VERSION ""

NS_ :

BS_:

BU_: BCM BSM DIAG_TEST ECM EPS IPC MTA ORC PAM

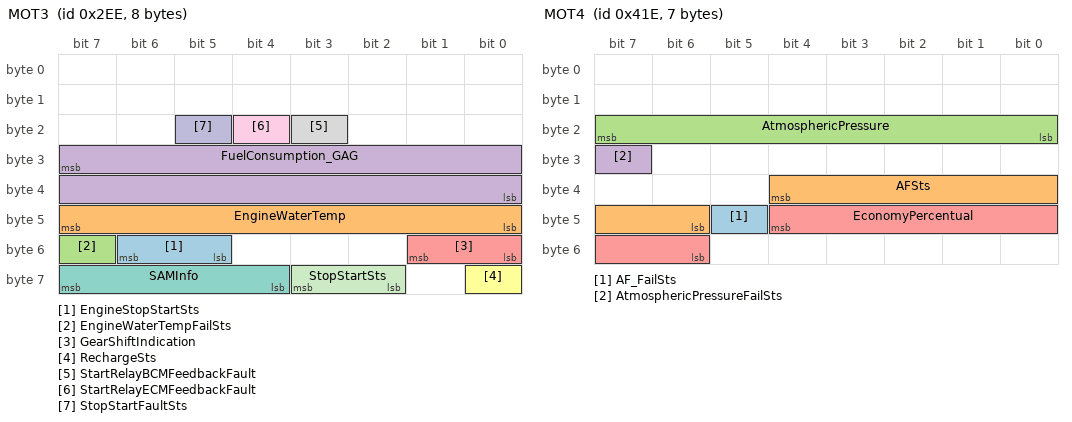
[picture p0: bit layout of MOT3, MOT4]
BO_ 750 MOT3: 8 ECM
 SG_ EngineStopStartSts : 54|2@0+ (1,0) [0|3] "-"  BCM,BSM,EPS,MTA
 SG_ EngineWaterTemp : 47|8@0+ (1,-40) [-40|215] "°C"  BCM,IPC,MTA
 SG_ EngineWaterTempFailSts : 55|1@0+ (1,0) [0|1] "-"  BCM,IPC
 SG_ FuelConsumption_GAG : 31|16@0+ (0.0022,0) [0|144.1748] "litres/hour"  BCM,IPC
 SG_ GearShiftIndication : 49|2@0+ (1,0) [0|3] "-"  BCM,IPC
 SG_ RechargeSts : 56|1@0+ (1,0) [0|1] "-"  BCM,IPC
 SG_ SAMInfo : 63|4@0+ (1,0) [0|0] "-"  BCM
 SG_ StartRelayBCMFeedbackFault : 19|1@0+ (1,0) [0|1] "-"  BCM
 SG_ StartRelayECMFeedbackFault : 20|1@0+ (1,0) [0|1] "-"  BCM
 SG_ StopStartFaultSts : 21|1@0+ (1,0) [0|1] "-"  BCM
 SG_ StopStartSts : 59|2@0+ (1,0) [0|3] "-"  BCM,BSM,EPS,IPC,MTA

BO_ 1054 MOT4: 7 ECM
 SG_ AF_FailSts : 45|1@0+ (1,0) [0|1] ""  BCM,IPC
 SG_ AFSts : 36|7@0+ (0.1,8) [8|20.7] ""  BCM,IPC
 SG_ AtmosphericPressure : 23|8@0+ (3.6,300) [300|1214.4] "mbar"  MTA
 SG_ AtmosphericPressureFailSts : 31|1@0+ (1,0) [0|1] "-"  MTA
 SG_ EconomyPercentual : 44|7@0+ (1,0) [0|127] "%"  IPC

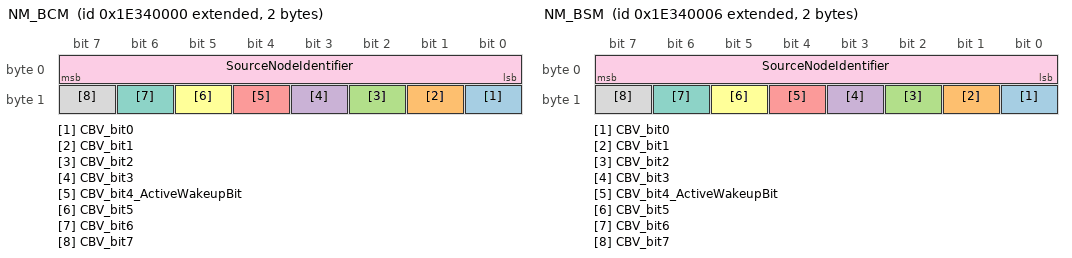
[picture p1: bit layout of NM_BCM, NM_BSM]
BO_ 2654208000 NM_BCM: 2 BCM
 SG_ CBV_bit0 : 8|1@0+ (1,0) [0|0] ""  BSM,ECM,EPS,IPC,MTA
 SG_ CBV_bit1 : 9|1@0+ (1,0) [0|0] ""  BSM,ECM,EPS,IPC,MTA
 SG_ CBV_bit2 : 10|1@0+ (1,0) [0|0] ""  BSM,ECM,EPS,IPC,MTA
 SG_ CBV_bit3 : 11|1@0+ (1,0) [0|0] ""  BSM,ECM,EPS,IPC,MTA
 SG_ CBV_bit4_ActiveWakeupBit : 12|1@0+ (1,0) [0|0] ""  BSM,ECM,EPS,IPC,MTA
 SG_ CBV_bit5 : 13|1@0+ (1,0) [0|0] ""  BSM,ECM,EPS,IPC,MTA
 SG_ CBV_bit6 : 14|1@0+ (1,0) [0|0] ""  BSM,ECM,EPS,IPC,MTA
 SG_ CBV_bit7 : 15|1@0+ (1,0) [0|0] ""  BSM,ECM,EPS,IPC,MTA
 SG_ SourceNodeIdentifier : 7|8@0+ (1,0) [0|1] "-"  BSM,ECM,EPS,IPC,MTA

BO_ 2654208006 NM_BSM: 2 BSM
 SG_ CBV_bit0 : 8|1@0+ (1,0) [0|0] ""  BCM,ECM,EPS,IPC,MTA
 SG_ CBV_bit1 : 9|1@0+ (1,0) [0|0] ""  BCM,ECM,EPS,IPC,MTA
 SG_ CBV_bit2 : 10|1@0+ (1,0) [0|0] ""  BCM,ECM,EPS,IPC,MTA
 SG_ CBV_bit3 : 11|1@0+ (1,0) [0|0] ""  BCM,ECM,EPS,IPC,MTA
 SG_ CBV_bit4_ActiveWakeupBit : 12|1@0+ (1,0) [0|0] ""  BCM,ECM,EPS,IPC,MTA
 SG_ CBV_bit5 : 13|1@0+ (1,0) [0|0] ""  BCM,ECM,EPS,IPC,MTA
 SG_ CBV_bit6 : 14|1@0+ (1,0) [0|0] ""  BCM,ECM,EPS,IPC,MTA
 SG_ CBV_bit7 : 15|1@0+ (1,0) [0|0] ""  BCM,ECM,EPS,IPC,MTA
 SG_ SourceNodeIdentifier : 7|8@0+ (1,0) [0|1] "-"  BCM,ECM,EPS,IPC,MTA

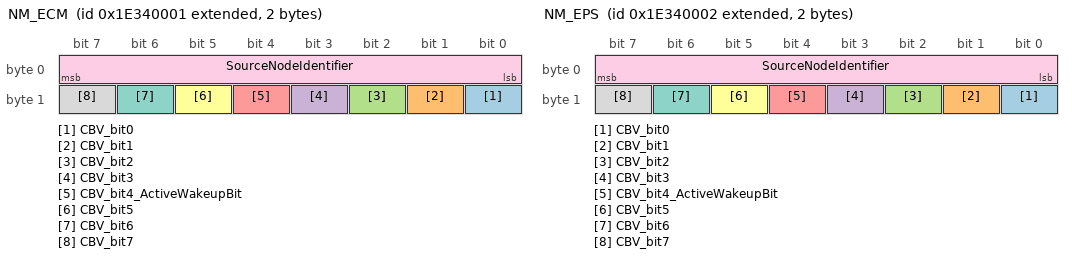
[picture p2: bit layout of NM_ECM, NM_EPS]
BO_ 2654208001 NM_ECM: 2 ECM
 SG_ CBV_bit0 : 8|1@0+ (1,0) [0|0] ""  BCM,BSM,EPS,IPC,MTA
 SG_ CBV_bit1 : 9|1@0+ (1,0) [0|0] ""  BCM,BSM,EPS,IPC,MTA
 SG_ CBV_bit2 : 10|1@0+ (1,0) [0|0] ""  BCM,BSM,EPS,IPC,MTA
 SG_ CBV_bit3 : 11|1@0+ (1,0) [0|0] ""  BCM,BSM,EPS,IPC,MTA
 SG_ CBV_bit4_ActiveWakeupBit : 12|1@0+ (1,0) [0|0] ""  BCM,BSM,EPS,IPC,MTA
 SG_ CBV_bit5 : 13|1@0+ (1,0) [0|0] ""  BCM,BSM,EPS,IPC,MTA
 SG_ CBV_bit6 : 14|1@0+ (1,0) [0|0] ""  BCM,BSM,EPS,IPC,MTA
 SG_ CBV_bit7 : 15|1@0+ (1,0) [0|0] ""  BCM,BSM,EPS,IPC,MTA
 SG_ SourceNodeIdentifier : 7|8@0+ (1,0) [0|1] "-"  BCM,BSM,EPS,IPC,MTA

BO_ 2654208002 NM_EPS: 2 EPS
 SG_ CBV_bit0 : 8|1@0+ (1,0) [0|0] ""  BCM,BSM,ECM,IPC,MTA
 SG_ CBV_bit1 : 9|1@0+ (1,0) [0|0] ""  BCM,BSM,ECM,IPC,MTA
 SG_ CBV_bit2 : 10|1@0+ (1,0) [0|0] ""  BCM,BSM,ECM,IPC,MTA
 SG_ CBV_bit3 : 11|1@0+ (1,0) [0|0] ""  BCM,BSM,ECM,IPC,MTA
 SG_ CBV_bit4_ActiveWakeupBit : 12|1@0+ (1,0) [0|0] ""  BCM,BSM,ECM,IPC,MTA
 SG_ CBV_bit5 : 13|1@0+ (1,0) [0|0] ""  BCM,BSM,ECM,IPC,MTA
 SG_ CBV_bit6 : 14|1@0+ (1,0) [0|0] ""  BCM,BSM,ECM,IPC,MTA
 SG_ CBV_bit7 : 15|1@0+ (1,0) [0|0] ""  BCM,BSM,ECM,IPC,MTA
 SG_ SourceNodeIdentifier : 7|8@0+ (1,0) [0|1] "-"  BCM,BSM,ECM,IPC,MTA

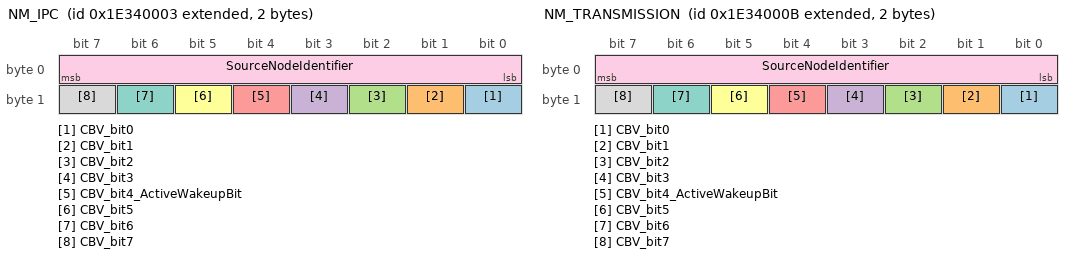
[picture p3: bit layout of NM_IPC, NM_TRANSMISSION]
BO_ 2654208003 NM_IPC: 2 IPC
 SG_ CBV_bit0 : 8|1@0+ (1,0) [0|0] ""  BCM,BSM,ECM,EPS,MTA
 SG_ CBV_bit1 : 9|1@0+ (1,0) [0|0] ""  BCM,BSM,ECM,EPS,MTA
 SG_ CBV_bit2 : 10|1@0+ (1,0) [0|0] ""  BCM,BSM,ECM,EPS,MTA
 SG_ CBV_bit3 : 11|1@0+ (1,0) [0|0] ""  BCM,BSM,ECM,EPS,MTA
 SG_ CBV_bit4_ActiveWakeupBit : 12|1@0+ (1,0) [0|0] ""  BCM,BSM,ECM,EPS,MTA
 SG_ CBV_bit5 : 13|1@0+ (1,0) [0|0] ""  BCM,BSM,ECM,EPS,MTA
 SG_ CBV_bit6 : 14|1@0+ (1,0) [0|0] ""  BCM,BSM,ECM,EPS,MTA
 SG_ CBV_bit7 : 15|1@0+ (1,0) [0|0] ""  BCM,BSM,ECM,EPS,MTA
 SG_ SourceNodeIdentifier : 7|8@0+ (1,0) [0|1] "-"  BCM,BSM,ECM,EPS,MTA

BO_ 2654208011 NM_TRANSMISSION: 2 MTA
 SG_ CBV_bit0 : 8|1@0+ (1,0) [0|0] ""  BCM,BSM,ECM,EPS,IPC
 SG_ CBV_bit1 : 9|1@0+ (1,0) [0|0] ""  BCM,BSM,ECM,EPS,IPC
 SG_ CBV_bit2 : 10|1@0+ (1,0) [0|0] ""  BCM,BSM,ECM,EPS,IPC
 SG_ CBV_bit3 : 11|1@0+ (1,0) [0|0] ""  BCM,BSM,ECM,EPS,IPC
 SG_ CBV_bit4_ActiveWakeupBit : 12|1@0+ (1,0) [0|0] ""  BCM,BSM,ECM,EPS,IPC
 SG_ CBV_bit5 : 13|1@0+ (1,0) [0|0] ""  BCM,BSM,ECM,EPS,IPC
 SG_ CBV_bit6 : 14|1@0+ (1,0) [0|0] ""  BCM,BSM,ECM,EPS,IPC
 SG_ CBV_bit7 : 15|1@0+ (1,0) [0|0] ""  BCM,BSM,ECM,EPS,IPC
 SG_ SourceNodeIdentifier : 7|8@0+ (1,0) [0|1] "-"  BCM,BSM,ECM,EPS,IPC

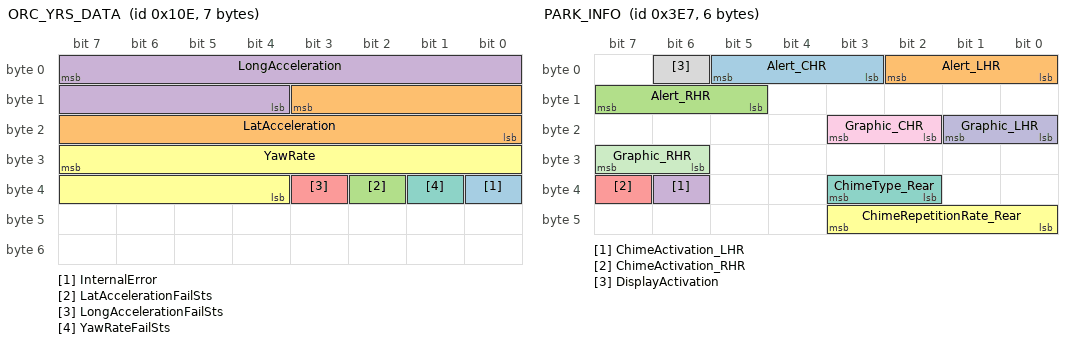
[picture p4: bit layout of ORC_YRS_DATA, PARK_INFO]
BO_ 270 ORC_YRS_DATA: 7 ORC
 SG_ InternalError : 32|1@0+ (1,0) [0|1] "-"  BSM
 SG_ LatAcceleration : 11|12@0+ (0.02,-40.96) [-40.96|40.92] "m/s^2"  BSM
 SG_ LatAccelerationFailSts : 34|1@0+ (1,0) [0|3] "-"  BSM
 SG_ LongAcceleration : 7|12@0+ (0.02,-40.96) [-40.96|40.92] "m/s^2"  BSM
 SG_ LongAccelerationFailSts : 35|1@0+ (1,0) [0|3] "-"  BSM
 SG_ YawRate : 31|12@0+ (0.08,-163.84) [-163.84|163.68] "deg/s"  BSM
 SG_ YawRateFailSts : 33|1@0+ (1,0) [0|3] "-"  BSM

BO_ 999 PARK_INFO: 6 PAM
 SG_ Alert_CHR : 5|3@0+ (1,0) [0|7] "-"  IPC
 SG_ Alert_LHR : 2|3@0+ (1,0) [0|7] "-"  IPC
 SG_ Alert_RHR : 15|3@0+ (1,0) [0|7] "-"  IPC
 SG_ ChimeActivation_LHR : 38|1@0+ (1,0) [0|1] "-"  IPC
 SG_ ChimeActivation_RHR : 39|1@0+ (1,0) [0|1] "-"  IPC
 SG_ ChimeRepetitionRate_Rear : 43|4@0+ (1,0) [0|15] "Hz"  IPC
 SG_ ChimeType_Rear : 35|2@0+ (1,0) [0|1] "-"  IPC
 SG_ DisplayActivation : 6|1@0+ (1,0) [0|1] "-"  IPC
 SG_ Graphic_CHR : 19|2@0+ (1,0) [0|3] "-"  IPC
 SG_ Graphic_LHR : 17|2@0+ (1,0) [0|3] "-"  IPC
 SG_ Graphic_RHR : 31|2@0+ (1,0) [0|3] "-"  IPC

BO_ 2654339072 PDC_INFO_BCM: 3 BCM
 SG_ CurrentFailSts_BCM : 6|1@0+ (1,0) [0|1] "" Vector__XXX
 SG_ DES_BCM : 4|1@0+ (1,0) [0|1] "" Vector__XXX
 SG_ EOL_BCM : 7|1@0+ (1,0) [0|1] "-" Vector__XXX
 SG_ GenericFailSts_BCM : 5|1@0+ (1,0) [0|1] "" Vector__XXX
 SG_ Reserved_for_PDC_BCM : 3|4@0+ (1,0) [0|0] "" Vector__XXX
 SG_ StayActiveSource_BCM_0 : 15|1@0+ (1,0) [0|1] "" Vector__XXX
 SG_ StayActiveSource_BCM_1 : 14|1@0+ (1,0) [0|1] "" Vector__XXX
 SG_ StayActiveSource_BCM_10 : 21|1@0+ (1,0) [0|1] "" Vector__XXX
 SG_ StayActiveSource_BCM_11 : 20|1@0+ (1,0) [0|1] "" Vector__XXX
 SG_ StayActiveSource_BCM_12 : 19|1@0+ (1,0) [0|1] "" Vector__XXX
 SG_ StayActiveSource_BCM_13 : 18|1@0+ (1,0) [0|1] "" Vector__XXX
 SG_ StayActiveSource_BCM_14 : 17|1@0+ (1,0) [0|1] "" Vector__XXX
 SG_ StayActiveSource_BCM_15 : 16|1@0+ (1,0) [0|1] "" Vector__XXX
 SG_ StayActiveSource_BCM_2 : 13|1@0+ (1,0) [0|1] "" Vector__XXX
 SG_ StayActiveSource_BCM_3 : 12|1@0+ (1,0) [0|1] "" Vector__XXX
 SG_ StayActiveSource_BCM_4 : 11|1@0+ (1,0) [0|1] "" Vector__XXX
 SG_ StayActiveSource_BCM_5 : 10|1@0+ (1,0) [0|1] "" Vector__XXX
 SG_ StayActiveSource_BCM_6 : 9|1@0+ (1,0) [0|1] "" Vector__XXX
 SG_ StayActiveSource_BCM_7 : 8|1@0+ (1,0) [0|1] "" Vector__XXX
 SG_ StayActiveSource_BCM_8 : 23|1@0+ (1,0) [0|1] "" Vector__XXX
 SG_ StayActiveSource_BCM_9 : 22|1@0+ (1,0) [0|1] "" Vector__XXX

BO_ 2654339078 PDC_INFO_BSM: 3 BSM
 SG_ CurrentFailSts_BSM : 6|1@0+ (1,0) [0|1] ""  BCM
 SG_ DES_BSM : 4|1@0+ (1,0) [0|1] "" Vector__XXX
 SG_ EOL_BSM : 7|1@0+ (1,0) [0|1] "-"  BCM
 SG_ GenericFailSts_BSM : 5|1@0+ (1,0) [0|1] ""  BCM
 SG_ Reserved_for_PDC_BSM : 3|4@0+ (1,0) [0|0] "" Vector__XXX
 SG_ StayActiveSource_BSM_0 : 15|1@0+ (1,0) [0|1] "" Vector__XXX
 SG_ StayActiveSource_BSM_1 : 14|1@0+ (1,0) [0|1] "" Vector__XXX
 SG_ StayActiveSource_BSM_10 : 21|1@0+ (1,0) [0|1] "" Vector__XXX
 SG_ StayActiveSource_BSM_11 : 20|1@0+ (1,0) [0|1] "" Vector__XXX
 SG_ StayActiveSource_BSM_12 : 19|1@0+ (1,0) [0|1] "" Vector__XXX
 SG_ StayActiveSource_BSM_13 : 18|1@0+ (1,0) [0|1] "" Vector__XXX
 SG_ StayActiveSource_BSM_14 : 17|1@0+ (1,0) [0|1] "" Vector__XXX
 SG_ StayActiveSource_BSM_15 : 16|1@0+ (1,0) [0|1] "" Vector__XXX
 SG_ StayActiveSource_BSM_2 : 13|1@0+ (1,0) [0|1] "" Vector__XXX
 SG_ StayActiveSource_BSM_3 : 12|1@0+ (1,0) [0|1] "" Vector__XXX
 SG_ StayActiveSource_BSM_4 : 11|1@0+ (1,0) [0|1] "" Vector__XXX
 SG_ StayActiveSource_BSM_5 : 10|1@0+ (1,0) [0|1] "" Vector__XXX
 SG_ StayActiveSource_BSM_6 : 9|1@0+ (1,0) [0|1] "" Vector__XXX
 SG_ StayActiveSource_BSM_7 : 8|1@0+ (1,0) [0|1] "" Vector__XXX
 SG_ StayActiveSource_BSM_8 : 23|1@0+ (1,0) [0|1] "" Vector__XXX
 SG_ StayActiveSource_BSM_9 : 22|1@0+ (1,0) [0|1] "" Vector__XXX

BO_ 2654339073 PDC_INFO_ECM: 3 ECM
 SG_ CurrentFailSts_ECM : 6|1@0+ (1,0) [0|1] ""  BCM
 SG_ DES_ECM : 4|1@0+ (1,0) [0|1] "" Vector__XXX
 SG_ EOL_ECM : 7|1@0+ (1,0) [0|1] "-"  BCM
 SG_ GenericFailSts_ECM : 5|1@0+ (1,0) [0|1] ""  BCM
 SG_ Reserved_for_PDC_ECM : 3|4@0+ (1,0) [0|0] "" Vector__XXX
 SG_ StayActiveSource_ECM_0 : 15|1@0+ (1,0) [0|1] "" Vector__XXX
 SG_ StayActiveSource_ECM_1 : 14|1@0+ (1,0) [0|1] "" Vector__XXX
 SG_ StayActiveSource_ECM_10 : 21|1@0+ (1,0) [0|1] "" Vector__XXX
 SG_ StayActiveSource_ECM_11 : 20|1@0+ (1,0) [0|1] "" Vector__XXX
 SG_ StayActiveSource_ECM_12 : 19|1@0+ (1,0) [0|1] "" Vector__XXX
 SG_ StayActiveSource_ECM_13 : 18|1@0+ (1,0) [0|1] "" Vector__XXX
 SG_ StayActiveSource_ECM_14 : 17|1@0+ (1,0) [0|1] "" Vector__XXX
 SG_ StayActiveSource_ECM_15 : 16|1@0+ (1,0) [0|1] "" Vector__XXX
 SG_ StayActiveSource_ECM_2 : 13|1@0+ (1,0) [0|1] "" Vector__XXX
 SG_ StayActiveSource_ECM_3 : 12|1@0+ (1,0) [0|1] "" Vector__XXX
 SG_ StayActiveSource_ECM_4 : 11|1@0+ (1,0) [0|1] "" Vector__XXX
 SG_ StayActiveSource_ECM_5 : 10|1@0+ (1,0) [0|1] "" Vector__XXX
 SG_ StayActiveSource_ECM_6 : 9|1@0+ (1,0) [0|1] "" Vector__XXX
 SG_ StayActiveSource_ECM_7 : 8|1@0+ (1,0) [0|1] "" Vector__XXX
 SG_ StayActiveSource_ECM_8 : 23|1@0+ (1,0) [0|1] "" Vector__XXX
 SG_ StayActiveSource_ECM_9 : 22|1@0+ (1,0) [0|1] "" Vector__XXX

BO_ 2654339074 PDC_INFO_EPS: 3 EPS
 SG_ CurrentFailSts_EPS : 6|1@0+ (1,0) [0|1] ""  BCM
 SG_ DES_EPS : 4|1@0+ (1,0) [0|1] "" Vector__XXX
 SG_ EOL_EPS : 7|1@0+ (1,0) [0|1] "-"  BCM
 SG_ GenericFailSts_EPS : 5|1@0+ (1,0) [0|1] ""  BCM
 SG_ Reserved_for_PDC_EPS : 3|4@0+ (1,0) [0|0] "" Vector__XXX
 SG_ StayActiveSource_EPS_0 : 15|1@0+ (1,0) [0|1] "" Vector__XXX
 SG_ StayActiveSource_EPS_1 : 14|1@0+ (1,0) [0|1] "" Vector__XXX
 SG_ StayActiveSource_EPS_10 : 21|1@0+ (1,0) [0|1] "" Vector__XXX
 SG_ StayActiveSource_EPS_11 : 20|1@0+ (1,0) [0|1] "" Vector__XXX
 SG_ StayActiveSource_EPS_12 : 19|1@0+ (1,0) [0|1] "" Vector__XXX
 SG_ StayActiveSource_EPS_13 : 18|1@0+ (1,0) [0|1] "" Vector__XXX
 SG_ StayActiveSource_EPS_14 : 17|1@0+ (1,0) [0|1] "" Vector__XXX
 SG_ StayActiveSource_EPS_15 : 16|1@0+ (1,0) [0|1] "" Vector__XXX
 SG_ StayActiveSource_EPS_2 : 13|1@0+ (1,0) [0|1] "" Vector__XXX
 SG_ StayActiveSource_EPS_3 : 12|1@0+ (1,0) [0|1] "" Vector__XXX
 SG_ StayActiveSource_EPS_4 : 11|1@0+ (1,0) [0|1] "" Vector__XXX
 SG_ StayActiveSource_EPS_5 : 10|1@0+ (1,0) [0|1] "" Vector__XXX
 SG_ StayActiveSource_EPS_6 : 9|1@0+ (1,0) [0|1] "" Vector__XXX
 SG_ StayActiveSource_EPS_7 : 8|1@0+ (1,0) [0|1] "" Vector__XXX
 SG_ StayActiveSource_EPS_8 : 23|1@0+ (1,0) [0|1] "" Vector__XXX
 SG_ StayActiveSource_EPS_9 : 22|1@0+ (1,0) [0|1] "" Vector__XXX

BO_ 2654339075 PDC_INFO_IPC: 3 IPC
 SG_ CurrentFailSts_IPC : 6|1@0+ (1,0) [0|1] ""  BCM
 SG_ DES_IPC : 4|1@0+ (1,0) [0|1] "" Vector__XXX
 SG_ EOL_IPC : 7|1@0+ (1,0) [0|1] "-"  BCM
 SG_ GenericFailSts_IPC : 5|1@0+ (1,0) [0|1] ""  BCM
 SG_ Reserved_for_PDC_IPC : 3|4@0+ (1,0) [0|0] "" Vector__XXX
 SG_ StayActiveSource_IPC_0 : 15|1@0+ (1,0) [0|1] "" Vector__XXX
 SG_ StayActiveSource_IPC_1 : 14|1@0+ (1,0) [0|1] "" Vector__XXX
 SG_ StayActiveSource_IPC_10 : 21|1@0+ (1,0) [0|1] "" Vector__XXX
 SG_ StayActiveSource_IPC_11 : 20|1@0+ (1,0) [0|1] "" Vector__XXX
 SG_ StayActiveSource_IPC_12 : 19|1@0+ (1,0) [0|1] "" Vector__XXX
 SG_ StayActiveSource_IPC_13 : 18|1@0+ (1,0) [0|1] "" Vector__XXX
 SG_ StayActiveSource_IPC_14 : 17|1@0+ (1,0) [0|1] "" Vector__XXX
 SG_ StayActiveSource_IPC_15 : 16|1@0+ (1,0) [0|1] "" Vector__XXX
 SG_ StayActiveSource_IPC_2 : 13|1@0+ (1,0) [0|1] "" Vector__XXX
 SG_ StayActiveSource_IPC_3 : 12|1@0+ (1,0) [0|1] "" Vector__XXX
 SG_ StayActiveSource_IPC_4 : 11|1@0+ (1,0) [0|1] "" Vector__XXX
 SG_ StayActiveSource_IPC_5 : 10|1@0+ (1,0) [0|1] "" Vector__XXX
 SG_ StayActiveSource_IPC_6 : 9|1@0+ (1,0) [0|1] "" Vector__XXX
 SG_ StayActiveSource_IPC_7 : 8|1@0+ (1,0) [0|1] "" Vector__XXX
 SG_ StayActiveSource_IPC_8 : 23|1@0+ (1,0) [0|1] "" Vector__XXX
 SG_ StayActiveSource_IPC_9 : 22|1@0+ (1,0) [0|1] "" Vector__XXX

CM_ SG_ 750 EngineStopStartSts "It is set to Engine Stop when the Engine is turned off by the Stop&Start management";
CM_ SG_ 750 EngineWaterTemp "It is the engine water temperature, measured through the related sensor.";
CM_ SG_ 750 EngineWaterTempFailSts "It is the Fail Status bit of EngineWaterTemp signal; the signal is set to Fail Present when the engine temperature sensor is faulty.";
CM_ SG_ 750 FuelConsumption_GAG "It represents istantaneous consumption information sent on network";
CM_ SG_ 750 GearShiftIndication "It gives indication of gear shifting";
CM_ SG_ 750 RechargeSts "It is the ECM logical Output used to indicate if alternator status is in Recharge or Not Recharge status.";
CM_ SG_ 750 SAMInfo "This signal indicates the logic status of the SAM strategy.";
CM_ SG_ 750 StartRelayBCMFeedbackFault "Diagnosis signal of the BCM cranking relay sent by ECM";
CM_ SG_ 750 StartRelayECMFeedbackFault "Diagnosis signal of the ECM cranking relay, sent by ECM";
CM_ SG_ 750 StopStartFaultSts "Indicates a possible fault occurred on the sensor acquired by ECM";
CM_ SG_ 750 StopStartSts "Sent by ECM to BCM, highlight the status of the Stop&Start function.";
CM_ SG_ 1054 AtmosphericPressure "It indicates atmospheric pressure read from the atmospheric pressure sensor.";
CM_ SG_ 1054 AtmosphericPressureFailSts "This signal indicates if the atmospheric pressure sensor is in fail.";
CM_ SG_ 270 InternalError "This signal indicates if an internal error has been processed";
CM_ SG_ 270 LatAcceleration "This signal indicates the Lateral Acceleration Value";
CM_ SG_ 270 LatAccelerationFailSts "This signal indicates the status of Lateral Acceleration Signal";
CM_ SG_ 270 LongAcceleration "This signal indicates the Longitudinal Acceleration Value";
CM_ SG_ 270 LongAccelerationFailSts "This signal indicates the status of Longitudinal acceleration signal";
CM_ SG_ 270 YawRate "This signal indicates the Yaw Rate Value";
CM_ SG_ 270 YawRateFailSts "This signal indicates the Status of Yaw Rate Signal";
CM_ SG_ 999 Alert_CHR "This signal indicates which arc shall be displayed in the central hand, rear position of the car graphics.";
CM_ SG_ 999 Alert_LHR "This signal indicates which arc shall be displayed in the left hand, rear position of the car graphics.";
CM_ SG_ 999 Alert_RHR "This signal indicates which arc shall be displayed in the right hand, rear position of the car graphics.";
CM_ SG_ 999 ChimeActivation_LHR "This signal indicates the chime activation request for the left hand, rear audio speaker, or rear hardwired buzzer.";
CM_ SG_ 999 ChimeActivation_RHR "This signal indicates the chime activation request for the right hand, rear audio speaker, or rear hardwired buzzer.";
CM_ SG_ 999 ChimeRepetitionRate_Rear "This signal indicates the repetition rate for the rear audio speakers.";
CM_ SG_ 999 ChimeType_Rear "This signal indicates the Chime Type for the rear audio speakers.";
CM_ SG_ 999 DisplayActivation "This signal indicates the request to display the car graphics layout on the IPC/EVIC screen.";
CM_ SG_ 999 Graphic_CHR "This signal indicates the flash rate of the arc displayed in the central hand, rear position of the car graphics.";
CM_ SG_ 999 Graphic_LHR "This signal indicates the flash rate of the arc displayed in the left hand, rear position of the car graphics.";
CM_ SG_ 999 Graphic_RHR "This signal indicates the flash rate of the arc displayed in the right hand, rear position of the car graphics.";
BA_DEF_ SG_  "GenSigStartValue" INT 0 2147483647;
BA_DEF_ SG_  "GenSigInactiveValue" INT 0 2147483647;
BA_DEF_ SG_  "GenSigSendType" ENUM  "NotUsed","OnWrite","OnWriteWithRepetition","OnChange","OnChangeWithRepetition","IfActive","IfActiveWithRepetition","NoSigSendType";
BA_DEF_ SG_  "GenSigTimeoutTime_BCM" INT 0 65535;
BA_DEF_ SG_  "GenSigTimeoutTime_BSM" INT 0 65535;
BA_DEF_ SG_  "GenSigTimeoutTime_DIAG_TEST" INT 0 65535;
BA_DEF_ SG_  "GenSigTimeoutTime_ECM" INT 0 65535;
BA_DEF_ SG_  "GenSigTimeoutTime_EPS" INT 0 65535;
BA_DEF_ SG_  "GenSigTimeoutTime_IPC" INT 0 65535;
BA_DEF_ SG_  "GenSigTimeoutTime_MTA" INT 0 65535;
BA_DEF_ SG_  "GenSigTimeoutTime_ORC" INT 0 65535;
BA_DEF_ SG_  "GenSigTimeoutTime_PAM" INT 0 65535;
BA_DEF_ BO_  "DiagRequest" ENUM  "No","Yes";
BA_DEF_ BO_  "Type" ENUM  "P","C","PE","COC","PE_Cntrl","E","E_Cntrl","OC","S","BAF","DC","EM","MM","-";
BA_DEF_ BO_  "DiagResponse" ENUM  "No","Yes";
BA_DEF_ BO_  "NmMessage" ENUM  "No","Yes";
BA_DEF_ BO_  "GenMsgSendType" ENUM  "Cyclic","NotUsed","NotUsed","NotUsed","NotUsed","NotUsed","NotUsed","NotUsed","NoMsgSendType";
BA_DEF_ BO_  "GenMsgNrOfRepetition" INT 0 255;
BA_DEF_ BO_  "GenMsgILSupport" ENUM  "No","Yes";
BA_DEF_ BO_  "GenMsgStartDelayTime" INT 0 65535;
BA_DEF_ BO_  "GenMsgCycleTimeFast" INT 0 65535;
BA_DEF_ BO_  "GenMsgCycleTime" INT 0 65535;
BA_DEF_ BO_  "GenMsgDelayTime" INT 0 65535;
BA_DEF_ BO_  "NmAsrMessage" ENUM  "No","Yes";
BA_DEF_ BO_  "DiagState" ENUM  "No","Yes";
BA_DEF_ BO_  "DiagConnection" HEX 0 65535;
BA_DEF_DEF_  "GenSigStartValue" 0;
BA_DEF_DEF_  "GenSigInactiveValue" 0;
BA_DEF_DEF_  "GenSigSendType" "NoSigSendType";
BA_DEF_DEF_  "GenSigTimeoutTime_BCM" 2500;
BA_DEF_DEF_  "GenSigTimeoutTime_BSM" 2500;
BA_DEF_DEF_  "GenSigTimeoutTime_DIAG_TEST" 2500;
BA_DEF_DEF_  "GenSigTimeoutTime_ECM" 2500;
BA_DEF_DEF_  "GenSigTimeoutTime_EPS" 2500;
BA_DEF_DEF_  "GenSigTimeoutTime_IPC" 2500;
BA_DEF_DEF_  "GenSigTimeoutTime_MTA" 2500;
BA_DEF_DEF_  "GenSigTimeoutTime_ORC" 2500;
BA_DEF_DEF_  "GenSigTimeoutTime_PAM" 2500;
BA_DEF_DEF_  "DiagRequest" "No";
BA_DEF_DEF_  "Type" "-";
BA_DEF_DEF_  "DiagResponse" "No";
BA_DEF_DEF_  "NmMessage" "No";
BA_DEF_DEF_  "GenMsgSendType" "NoMsgSendType";
BA_DEF_DEF_  "GenMsgNrOfRepetition" 0;
BA_DEF_DEF_  "GenMsgILSupport" "No";
BA_DEF_DEF_  "GenMsgStartDelayTime" 0;
BA_DEF_DEF_  "GenMsgCycleTimeFast" 0;
BA_DEF_DEF_  "GenMsgCycleTime" 0;
BA_DEF_DEF_  "GenMsgDelayTime" 0;
BA_DEF_DEF_  "NmAsrMessage" "No";
BA_DEF_DEF_  "DiagState" "No";
BA_DEF_DEF_  "DiagConnection" 0;
BA_ "Type" BO_ 750 1;
BA_ "GenMsgSendType" BO_ 750 0;
BA_ "GenMsgILSupport" BO_ 750 1;
BA_ "GenMsgStartDelayTime" BO_ 750 30;
BA_ "GenMsgCycleTime" BO_ 750 50;
BA_ "Type" BO_ 1054 1;
BA_ "GenMsgSendType" BO_ 1054 0;
BA_ "GenMsgILSupport" BO_ 1054 1;
BA_ "GenMsgStartDelayTime" BO_ 1054 50;
BA_ "GenMsgCycleTime" BO_ 1054 100;
BA_ "Type" BO_ 2654208000 8;
BA_ "NmMessage" BO_ 2654208000 1;
BA_ "NmAsrMessage" BO_ 2654208000 1;
BA_ "Type" BO_ 2654208006 8;
BA_ "NmMessage" BO_ 2654208006 1;
BA_ "NmAsrMessage" BO_ 2654208006 1;
BA_ "Type" BO_ 2654208001 8;
BA_ "NmMessage" BO_ 2654208001 1;
BA_ "NmAsrMessage" BO_ 2654208001 1;
BA_ "Type" BO_ 2654208002 8;
BA_ "NmMessage" BO_ 2654208002 1;
BA_ "NmAsrMessage" BO_ 2654208002 1;
BA_ "Type" BO_ 2654208003 8;
BA_ "NmMessage" BO_ 2654208003 1;
BA_ "NmAsrMessage" BO_ 2654208003 1;
BA_ "Type" BO_ 2654208011 8;
BA_ "NmMessage" BO_ 2654208011 1;
BA_ "NmAsrMessage" BO_ 2654208011 1;
BA_ "Type" BO_ 270 1;
BA_ "GenMsgSendType" BO_ 270 0;
BA_ "GenMsgILSupport" BO_ 270 1;
BA_ "GenMsgCycleTime" BO_ 270 10;
BA_ "Type" BO_ 999 9;
BA_ "GenMsgNrOfRepetition" BO_ 999 3;
BA_ "GenMsgILSupport" BO_ 999 1;
BA_ "GenMsgCycleTimeFast" BO_ 999 100;
BA_ "Type" BO_ 2654339072 1;
BA_ "GenMsgSendType" BO_ 2654339072 0;
BA_ "GenMsgILSupport" BO_ 2654339072 1;
BA_ "GenMsgStartDelayTime" BO_ 2654339072 500;
BA_ "GenMsgCycleTime" BO_ 2654339072 1000;
BA_ "Type" BO_ 2654339078 1;
BA_ "GenMsgSendType" BO_ 2654339078 0;
BA_ "GenMsgILSupport" BO_ 2654339078 1;
BA_ "GenMsgStartDelayTime" BO_ 2654339078 755;
BA_ "GenMsgCycleTime" BO_ 2654339078 1000;
BA_ "Type" BO_ 2654339073 1;
BA_ "GenMsgSendType" BO_ 2654339073 0;
BA_ "GenMsgILSupport" BO_ 2654339073 1;
BA_ "GenMsgStartDelayTime" BO_ 2654339073 260;
BA_ "GenMsgCycleTime" BO_ 2654339073 1000;
BA_ "Type" BO_ 2654339074 1;
BA_ "GenMsgSendType" BO_ 2654339074 0;
BA_ "GenMsgILSupport" BO_ 2654339074 1;
BA_ "GenMsgCycleTime" BO_ 2654339074 1000;
BA_ "Type" BO_ 2654339075 1;
BA_ "GenMsgSendType" BO_ 2654339075 0;
BA_ "GenMsgILSupport" BO_ 2654339075 1;
BA_ "GenMsgStartDelayTime" BO_ 2654339075 265;
BA_ "GenMsgCycleTime" BO_ 2654339075 1000;
BA_ "GenSigStartValue" SG_ 750 EngineStopStartSts 1;
BA_ "GenSigTimeoutTime_DIAG_TEST" SG_ 750 EngineStopStartSts 0;
BA_ "GenSigTimeoutTime_ECM" SG_ 750 EngineStopStartSts 0;
BA_ "GenSigTimeoutTime_IPC" SG_ 750 EngineStopStartSts 0;
BA_ "GenSigTimeoutTime_ORC" SG_ 750 EngineStopStartSts 0;
BA_ "GenSigTimeoutTime_PAM" SG_ 750 EngineStopStartSts 0;
BA_ "GenSigTimeoutTime_BSM" SG_ 750 EngineWaterTemp 0;
BA_ "GenSigTimeoutTime_DIAG_TEST" SG_ 750 EngineWaterTemp 0;
BA_ "GenSigTimeoutTime_ECM" SG_ 750 EngineWaterTemp 0;
BA_ "GenSigTimeoutTime_EPS" SG_ 750 EngineWaterTemp 0;
BA_ "GenSigTimeoutTime_ORC" SG_ 750 EngineWaterTemp 0;
BA_ "GenSigTimeoutTime_PAM" SG_ 750 EngineWaterTemp 0;
BA_ "GenSigTimeoutTime_BSM" SG_ 750 EngineWaterTempFailSts 0;
BA_ "GenSigTimeoutTime_DIAG_TEST" SG_ 750 EngineWaterTempFailSts 0;
BA_ "GenSigTimeoutTime_ECM" SG_ 750 EngineWaterTempFailSts 0;
BA_ "GenSigTimeoutTime_EPS" SG_ 750 EngineWaterTempFailSts 0;
BA_ "GenSigTimeoutTime_MTA" SG_ 750 EngineWaterTempFailSts 0;
BA_ "GenSigTimeoutTime_ORC" SG_ 750 EngineWaterTempFailSts 0;
BA_ "GenSigTimeoutTime_PAM" SG_ 750 EngineWaterTempFailSts 0;
BA_ "GenSigTimeoutTime_BSM" SG_ 750 FuelConsumption_GAG 0;
BA_ "GenSigTimeoutTime_DIAG_TEST" SG_ 750 FuelConsumption_GAG 0;
BA_ "GenSigTimeoutTime_ECM" SG_ 750 FuelConsumption_GAG 0;
BA_ "GenSigTimeoutTime_EPS" SG_ 750 FuelConsumption_GAG 0;
BA_ "GenSigTimeoutTime_MTA" SG_ 750 FuelConsumption_GAG 0;
BA_ "GenSigTimeoutTime_ORC" SG_ 750 FuelConsumption_GAG 0;
BA_ "GenSigTimeoutTime_PAM" SG_ 750 FuelConsumption_GAG 0;
BA_ "GenSigTimeoutTime_BSM" SG_ 750 GearShiftIndication 0;
BA_ "GenSigTimeoutTime_DIAG_TEST" SG_ 750 GearShiftIndication 0;
BA_ "GenSigTimeoutTime_ECM" SG_ 750 GearShiftIndication 0;
BA_ "GenSigTimeoutTime_EPS" SG_ 750 GearShiftIndication 0;
BA_ "GenSigTimeoutTime_MTA" SG_ 750 GearShiftIndication 0;
BA_ "GenSigTimeoutTime_ORC" SG_ 750 GearShiftIndication 0;
BA_ "GenSigTimeoutTime_PAM" SG_ 750 GearShiftIndication 0;
BA_ "GenSigStartValue" SG_ 750 RechargeSts 1;
BA_ "GenSigTimeoutTime_BSM" SG_ 750 RechargeSts 0;
BA_ "GenSigTimeoutTime_DIAG_TEST" SG_ 750 RechargeSts 0;
BA_ "GenSigTimeoutTime_ECM" SG_ 750 RechargeSts 0;
BA_ "GenSigTimeoutTime_EPS" SG_ 750 RechargeSts 0;
BA_ "GenSigTimeoutTime_MTA" SG_ 750 RechargeSts 0;
BA_ "GenSigTimeoutTime_ORC" SG_ 750 RechargeSts 0;
BA_ "GenSigTimeoutTime_PAM" SG_ 750 RechargeSts 0;
BA_ "GenSigStartValue" SG_ 750 SAMInfo 15;
BA_ "GenSigTimeoutTime_BSM" SG_ 750 SAMInfo 0;
BA_ "GenSigTimeoutTime_DIAG_TEST" SG_ 750 SAMInfo 0;
BA_ "GenSigTimeoutTime_ECM" SG_ 750 SAMInfo 0;
BA_ "GenSigTimeoutTime_EPS" SG_ 750 SAMInfo 0;
BA_ "GenSigTimeoutTime_IPC" SG_ 750 SAMInfo 0;
BA_ "GenSigTimeoutTime_MTA" SG_ 750 SAMInfo 0;
BA_ "GenSigTimeoutTime_ORC" SG_ 750 SAMInfo 0;
BA_ "GenSigTimeoutTime_PAM" SG_ 750 SAMInfo 0;
BA_ "GenSigTimeoutTime_BSM" SG_ 750 StartRelayBCMFeedbackFault 0;
BA_ "GenSigTimeoutTime_DIAG_TEST" SG_ 750 StartRelayBCMFeedbackFault 0;
BA_ "GenSigTimeoutTime_ECM" SG_ 750 StartRelayBCMFeedbackFault 0;
BA_ "GenSigTimeoutTime_EPS" SG_ 750 StartRelayBCMFeedbackFault 0;
BA_ "GenSigTimeoutTime_IPC" SG_ 750 StartRelayBCMFeedbackFault 0;
BA_ "GenSigTimeoutTime_MTA" SG_ 750 StartRelayBCMFeedbackFault 0;
BA_ "GenSigTimeoutTime_ORC" SG_ 750 StartRelayBCMFeedbackFault 0;
BA_ "GenSigTimeoutTime_PAM" SG_ 750 StartRelayBCMFeedbackFault 0;
BA_ "GenSigTimeoutTime_BSM" SG_ 750 StartRelayECMFeedbackFault 0;
BA_ "GenSigTimeoutTime_DIAG_TEST" SG_ 750 StartRelayECMFeedbackFault 0;
BA_ "GenSigTimeoutTime_ECM" SG_ 750 StartRelayECMFeedbackFault 0;
BA_ "GenSigTimeoutTime_EPS" SG_ 750 StartRelayECMFeedbackFault 0;
BA_ "GenSigTimeoutTime_IPC" SG_ 750 StartRelayECMFeedbackFault 0;
BA_ "GenSigTimeoutTime_MTA" SG_ 750 StartRelayECMFeedbackFault 0;
BA_ "GenSigTimeoutTime_ORC" SG_ 750 StartRelayECMFeedbackFault 0;
BA_ "GenSigTimeoutTime_PAM" SG_ 750 StartRelayECMFeedbackFault 0;
BA_ "GenSigTimeoutTime_BSM" SG_ 750 StopStartFaultSts 0;
BA_ "GenSigTimeoutTime_DIAG_TEST" SG_ 750 StopStartFaultSts 0;
BA_ "GenSigTimeoutTime_ECM" SG_ 750 StopStartFaultSts 0;
BA_ "GenSigTimeoutTime_EPS" SG_ 750 StopStartFaultSts 0;
BA_ "GenSigTimeoutTime_IPC" SG_ 750 StopStartFaultSts 0;
BA_ "GenSigTimeoutTime_MTA" SG_ 750 StopStartFaultSts 0;
BA_ "GenSigTimeoutTime_ORC" SG_ 750 StopStartFaultSts 0;
BA_ "GenSigTimeoutTime_PAM" SG_ 750 StopStartFaultSts 0;
BA_ "GenSigTimeoutTime_DIAG_TEST" SG_ 750 StopStartSts 0;
BA_ "GenSigTimeoutTime_ECM" SG_ 750 StopStartSts 0;
BA_ "GenSigTimeoutTime_ORC" SG_ 750 StopStartSts 0;
BA_ "GenSigTimeoutTime_PAM" SG_ 750 StopStartSts 0;
BA_ "GenSigTimeoutTime_BSM" SG_ 1054 AF_FailSts 0;
BA_ "GenSigTimeoutTime_DIAG_TEST" SG_ 1054 AF_FailSts 0;
BA_ "GenSigTimeoutTime_ECM" SG_ 1054 AF_FailSts 0;
BA_ "GenSigTimeoutTime_EPS" SG_ 1054 AF_FailSts 0;
BA_ "GenSigTimeoutTime_MTA" SG_ 1054 AF_FailSts 0;
BA_ "GenSigTimeoutTime_ORC" SG_ 1054 AF_FailSts 0;
BA_ "GenSigTimeoutTime_PAM" SG_ 1054 AF_FailSts 0;
BA_ "GenSigStartValue" SG_ 1054 AFSts 8;
BA_ "GenSigTimeoutTime_BSM" SG_ 1054 AFSts 0;
BA_ "GenSigTimeoutTime_DIAG_TEST" SG_ 1054 AFSts 0;
BA_ "GenSigTimeoutTime_ECM" SG_ 1054 AFSts 0;
BA_ "GenSigTimeoutTime_EPS" SG_ 1054 AFSts 0;
BA_ "GenSigTimeoutTime_MTA" SG_ 1054 AFSts 0;
BA_ "GenSigTimeoutTime_ORC" SG_ 1054 AFSts 0;
BA_ "GenSigTimeoutTime_PAM" SG_ 1054 AFSts 0;
BA_ "GenSigStartValue" SG_ 1054 AtmosphericPressure 255;
BA_ "GenSigTimeoutTime_BCM" SG_ 1054 AtmosphericPressure 0;
BA_ "GenSigTimeoutTime_BSM" SG_ 1054 AtmosphericPressure 0;
BA_ "GenSigTimeoutTime_DIAG_TEST" SG_ 1054 AtmosphericPressure 0;
BA_ "GenSigTimeoutTime_ECM" SG_ 1054 AtmosphericPressure 0;
BA_ "GenSigTimeoutTime_EPS" SG_ 1054 AtmosphericPressure 0;
BA_ "GenSigTimeoutTime_IPC" SG_ 1054 AtmosphericPressure 0;
BA_ "GenSigTimeoutTime_ORC" SG_ 1054 AtmosphericPressure 0;
BA_ "GenSigTimeoutTime_PAM" SG_ 1054 AtmosphericPressure 0;
BA_ "GenSigTimeoutTime_BCM" SG_ 1054 AtmosphericPressureFailSts 0;
BA_ "GenSigTimeoutTime_BSM" SG_ 1054 AtmosphericPressureFailSts 0;
BA_ "GenSigTimeoutTime_DIAG_TEST" SG_ 1054 AtmosphericPressureFailSts 0;
BA_ "GenSigTimeoutTime_ECM" SG_ 1054 AtmosphericPressureFailSts 0;
BA_ "GenSigTimeoutTime_EPS" SG_ 1054 AtmosphericPressureFailSts 0;
BA_ "GenSigTimeoutTime_IPC" SG_ 1054 AtmosphericPressureFailSts 0;
BA_ "GenSigTimeoutTime_ORC" SG_ 1054 AtmosphericPressureFailSts 0;
BA_ "GenSigTimeoutTime_PAM" SG_ 1054 AtmosphericPressureFailSts 0;
BA_ "GenSigTimeoutTime_BCM" SG_ 1054 EconomyPercentual 0;
BA_ "GenSigTimeoutTime_BSM" SG_ 1054 EconomyPercentual 0;
BA_ "GenSigTimeoutTime_DIAG_TEST" SG_ 1054 EconomyPercentual 0;
BA_ "GenSigTimeoutTime_ECM" SG_ 1054 EconomyPercentual 0;
BA_ "GenSigTimeoutTime_EPS" SG_ 1054 EconomyPercentual 0;
BA_ "GenSigTimeoutTime_MTA" SG_ 1054 EconomyPercentual 0;
BA_ "GenSigTimeoutTime_ORC" SG_ 1054 EconomyPercentual 0;
BA_ "GenSigTimeoutTime_PAM" SG_ 1054 EconomyPercentual 0;
BA_ "GenSigTimeoutTime_BCM" SG_ 2654208000 CBV_bit0 0;
BA_ "GenSigTimeoutTime_BSM" SG_ 2654208000 CBV_bit0 0;
BA_ "GenSigTimeoutTime_DIAG_TEST" SG_ 2654208000 CBV_bit0 0;
BA_ "GenSigTimeoutTime_ECM" SG_ 2654208000 CBV_bit0 0;
BA_ "GenSigTimeoutTime_EPS" SG_ 2654208000 CBV_bit0 0;
BA_ "GenSigTimeoutTime_IPC" SG_ 2654208000 CBV_bit0 0;
BA_ "GenSigTimeoutTime_MTA" SG_ 2654208000 CBV_bit0 0;
BA_ "GenSigTimeoutTime_ORC" SG_ 2654208000 CBV_bit0 0;
BA_ "GenSigTimeoutTime_PAM" SG_ 2654208000 CBV_bit0 0;
BA_ "GenSigTimeoutTime_BCM" SG_ 2654208000 CBV_bit1 0;
BA_ "GenSigTimeoutTime_BSM" SG_ 2654208000 CBV_bit1 0;
BA_ "GenSigTimeoutTime_DIAG_TEST" SG_ 2654208000 CBV_bit1 0;
BA_ "GenSigTimeoutTime_ECM" SG_ 2654208000 CBV_bit1 0;
BA_ "GenSigTimeoutTime_EPS" SG_ 2654208000 CBV_bit1 0;
BA_ "GenSigTimeoutTime_IPC" SG_ 2654208000 CBV_bit1 0;
BA_ "GenSigTimeoutTime_MTA" SG_ 2654208000 CBV_bit1 0;
BA_ "GenSigTimeoutTime_ORC" SG_ 2654208000 CBV_bit1 0;
BA_ "GenSigTimeoutTime_PAM" SG_ 2654208000 CBV_bit1 0;
BA_ "GenSigTimeoutTime_BCM" SG_ 2654208000 CBV_bit2 0;
BA_ "GenSigTimeoutTime_BSM" SG_ 2654208000 CBV_bit2 0;
BA_ "GenSigTimeoutTime_DIAG_TEST" SG_ 2654208000 CBV_bit2 0;
BA_ "GenSigTimeoutTime_ECM" SG_ 2654208000 CBV_bit2 0;
BA_ "GenSigTimeoutTime_EPS" SG_ 2654208000 CBV_bit2 0;
BA_ "GenSigTimeoutTime_IPC" SG_ 2654208000 CBV_bit2 0;
BA_ "GenSigTimeoutTime_MTA" SG_ 2654208000 CBV_bit2 0;
BA_ "GenSigTimeoutTime_ORC" SG_ 2654208000 CBV_bit2 0;
BA_ "GenSigTimeoutTime_PAM" SG_ 2654208000 CBV_bit2 0;
BA_ "GenSigTimeoutTime_BCM" SG_ 2654208000 CBV_bit3 0;
BA_ "GenSigTimeoutTime_BSM" SG_ 2654208000 CBV_bit3 0;
BA_ "GenSigTimeoutTime_DIAG_TEST" SG_ 2654208000 CBV_bit3 0;
BA_ "GenSigTimeoutTime_ECM" SG_ 2654208000 CBV_bit3 0;
BA_ "GenSigTimeoutTime_EPS" SG_ 2654208000 CBV_bit3 0;
BA_ "GenSigTimeoutTime_IPC" SG_ 2654208000 CBV_bit3 0;
BA_ "GenSigTimeoutTime_MTA" SG_ 2654208000 CBV_bit3 0;
BA_ "GenSigTimeoutTime_ORC" SG_ 2654208000 CBV_bit3 0;
BA_ "GenSigTimeoutTime_PAM" SG_ 2654208000 CBV_bit3 0;
BA_ "GenSigTimeoutTime_BCM" SG_ 2654208000 CBV_bit4_ActiveWakeupBit 0;
BA_ "GenSigTimeoutTime_BSM" SG_ 2654208000 CBV_bit4_ActiveWakeupBit 0;
BA_ "GenSigTimeoutTime_DIAG_TEST" SG_ 2654208000 CBV_bit4_ActiveWakeupBit 0;
BA_ "GenSigTimeoutTime_ECM" SG_ 2654208000 CBV_bit4_ActiveWakeupBit 0;
BA_ "GenSigTimeoutTime_EPS" SG_ 2654208000 CBV_bit4_ActiveWakeupBit 0;
BA_ "GenSigTimeoutTime_IPC" SG_ 2654208000 CBV_bit4_ActiveWakeupBit 0;
BA_ "GenSigTimeoutTime_MTA" SG_ 2654208000 CBV_bit4_ActiveWakeupBit 0;
BA_ "GenSigTimeoutTime_ORC" SG_ 2654208000 CBV_bit4_ActiveWakeupBit 0;
BA_ "GenSigTimeoutTime_PAM" SG_ 2654208000 CBV_bit4_ActiveWakeupBit 0;
BA_ "GenSigTimeoutTime_BCM" SG_ 2654208000 CBV_bit5 0;
BA_ "GenSigTimeoutTime_BSM" SG_ 2654208000 CBV_bit5 0;
BA_ "GenSigTimeoutTime_DIAG_TEST" SG_ 2654208000 CBV_bit5 0;
BA_ "GenSigTimeoutTime_ECM" SG_ 2654208000 CBV_bit5 0;
BA_ "GenSigTimeoutTime_EPS" SG_ 2654208000 CBV_bit5 0;
BA_ "GenSigTimeoutTime_IPC" SG_ 2654208000 CBV_bit5 0;
BA_ "GenSigTimeoutTime_MTA" SG_ 2654208000 CBV_bit5 0;
BA_ "GenSigTimeoutTime_ORC" SG_ 2654208000 CBV_bit5 0;
BA_ "GenSigTimeoutTime_PAM" SG_ 2654208000 CBV_bit5 0;
BA_ "GenSigTimeoutTime_BCM" SG_ 2654208000 CBV_bit6 0;
BA_ "GenSigTimeoutTime_BSM" SG_ 2654208000 CBV_bit6 0;
BA_ "GenSigTimeoutTime_DIAG_TEST" SG_ 2654208000 CBV_bit6 0;
BA_ "GenSigTimeoutTime_ECM" SG_ 2654208000 CBV_bit6 0;
BA_ "GenSigTimeoutTime_EPS" SG_ 2654208000 CBV_bit6 0;
BA_ "GenSigTimeoutTime_IPC" SG_ 2654208000 CBV_bit6 0;
BA_ "GenSigTimeoutTime_MTA" SG_ 2654208000 CBV_bit6 0;
BA_ "GenSigTimeoutTime_ORC" SG_ 2654208000 CBV_bit6 0;
BA_ "GenSigTimeoutTime_PAM" SG_ 2654208000 CBV_bit6 0;
BA_ "GenSigTimeoutTime_BCM" SG_ 2654208000 CBV_bit7 0;
BA_ "GenSigTimeoutTime_BSM" SG_ 2654208000 CBV_bit7 0;
BA_ "GenSigTimeoutTime_DIAG_TEST" SG_ 2654208000 CBV_bit7 0;
BA_ "GenSigTimeoutTime_ECM" SG_ 2654208000 CBV_bit7 0;
BA_ "GenSigTimeoutTime_EPS" SG_ 2654208000 CBV_bit7 0;
BA_ "GenSigTimeoutTime_IPC" SG_ 2654208000 CBV_bit7 0;
BA_ "GenSigTimeoutTime_MTA" SG_ 2654208000 CBV_bit7 0;
BA_ "GenSigTimeoutTime_ORC" SG_ 2654208000 CBV_bit7 0;
BA_ "GenSigTimeoutTime_PAM" SG_ 2654208000 CBV_bit7 0;
BA_ "GenSigTimeoutTime_BCM" SG_ 2654208000 SourceNodeIdentifier 0;
BA_ "GenSigTimeoutTime_BSM" SG_ 2654208000 SourceNodeIdentifier 0;
BA_ "GenSigTimeoutTime_DIAG_TEST" SG_ 2654208000 SourceNodeIdentifier 0;
BA_ "GenSigTimeoutTime_ECM" SG_ 2654208000 SourceNodeIdentifier 0;
BA_ "GenSigTimeoutTime_EPS" SG_ 2654208000 SourceNodeIdentifier 0;
BA_ "GenSigTimeoutTime_IPC" SG_ 2654208000 SourceNodeIdentifier 0;
BA_ "GenSigTimeoutTime_MTA" SG_ 2654208000 SourceNodeIdentifier 0;
BA_ "GenSigTimeoutTime_ORC" SG_ 2654208000 SourceNodeIdentifier 0;
BA_ "GenSigTimeoutTime_PAM" SG_ 2654208000 SourceNodeIdentifier 0;
BA_ "GenSigTimeoutTime_BCM" SG_ 2654208006 CBV_bit0 0;
BA_ "GenSigTimeoutTime_BSM" SG_ 2654208006 CBV_bit0 0;
BA_ "GenSigTimeoutTime_DIAG_TEST" SG_ 2654208006 CBV_bit0 0;
BA_ "GenSigTimeoutTime_ECM" SG_ 2654208006 CBV_bit0 0;
BA_ "GenSigTimeoutTime_EPS" SG_ 2654208006 CBV_bit0 0;
BA_ "GenSigTimeoutTime_IPC" SG_ 2654208006 CBV_bit0 0;
BA_ "GenSigTimeoutTime_MTA" SG_ 2654208006 CBV_bit0 0;
BA_ "GenSigTimeoutTime_ORC" SG_ 2654208006 CBV_bit0 0;
BA_ "GenSigTimeoutTime_PAM" SG_ 2654208006 CBV_bit0 0;
BA_ "GenSigTimeoutTime_BCM" SG_ 2654208006 CBV_bit1 0;
BA_ "GenSigTimeoutTime_BSM" SG_ 2654208006 CBV_bit1 0;
BA_ "GenSigTimeoutTime_DIAG_TEST" SG_ 2654208006 CBV_bit1 0;
BA_ "GenSigTimeoutTime_ECM" SG_ 2654208006 CBV_bit1 0;
BA_ "GenSigTimeoutTime_EPS" SG_ 2654208006 CBV_bit1 0;
BA_ "GenSigTimeoutTime_IPC" SG_ 2654208006 CBV_bit1 0;
BA_ "GenSigTimeoutTime_MTA" SG_ 2654208006 CBV_bit1 0;
BA_ "GenSigTimeoutTime_ORC" SG_ 2654208006 CBV_bit1 0;
BA_ "GenSigTimeoutTime_PAM" SG_ 2654208006 CBV_bit1 0;
BA_ "GenSigTimeoutTime_BCM" SG_ 2654208006 CBV_bit2 0;
BA_ "GenSigTimeoutTime_BSM" SG_ 2654208006 CBV_bit2 0;
BA_ "GenSigTimeoutTime_DIAG_TEST" SG_ 2654208006 CBV_bit2 0;
BA_ "GenSigTimeoutTime_ECM" SG_ 2654208006 CBV_bit2 0;
BA_ "GenSigTimeoutTime_EPS" SG_ 2654208006 CBV_bit2 0;
BA_ "GenSigTimeoutTime_IPC" SG_ 2654208006 CBV_bit2 0;
BA_ "GenSigTimeoutTime_MTA" SG_ 2654208006 CBV_bit2 0;
BA_ "GenSigTimeoutTime_ORC" SG_ 2654208006 CBV_bit2 0;
BA_ "GenSigTimeoutTime_PAM" SG_ 2654208006 CBV_bit2 0;
BA_ "GenSigTimeoutTime_BCM" SG_ 2654208006 CBV_bit3 0;
BA_ "GenSigTimeoutTime_BSM" SG_ 2654208006 CBV_bit3 0;
BA_ "GenSigTimeoutTime_DIAG_TEST" SG_ 2654208006 CBV_bit3 0;
BA_ "GenSigTimeoutTime_ECM" SG_ 2654208006 CBV_bit3 0;
BA_ "GenSigTimeoutTime_EPS" SG_ 2654208006 CBV_bit3 0;
BA_ "GenSigTimeoutTime_IPC" SG_ 2654208006 CBV_bit3 0;
BA_ "GenSigTimeoutTime_MTA" SG_ 2654208006 CBV_bit3 0;
BA_ "GenSigTimeoutTime_ORC" SG_ 2654208006 CBV_bit3 0;
BA_ "GenSigTimeoutTime_PAM" SG_ 2654208006 CBV_bit3 0;
BA_ "GenSigTimeoutTime_BCM" SG_ 2654208006 CBV_bit4_ActiveWakeupBit 0;
BA_ "GenSigTimeoutTime_BSM" SG_ 2654208006 CBV_bit4_ActiveWakeupBit 0;
BA_ "GenSigTimeoutTime_DIAG_TEST" SG_ 2654208006 CBV_bit4_ActiveWakeupBit 0;
BA_ "GenSigTimeoutTime_ECM" SG_ 2654208006 CBV_bit4_ActiveWakeupBit 0;
BA_ "GenSigTimeoutTime_EPS" SG_ 2654208006 CBV_bit4_ActiveWakeupBit 0;
BA_ "GenSigTimeoutTime_IPC" SG_ 2654208006 CBV_bit4_ActiveWakeupBit 0;
BA_ "GenSigTimeoutTime_MTA" SG_ 2654208006 CBV_bit4_ActiveWakeupBit 0;
BA_ "GenSigTimeoutTime_ORC" SG_ 2654208006 CBV_bit4_ActiveWakeupBit 0;
BA_ "GenSigTimeoutTime_PAM" SG_ 2654208006 CBV_bit4_ActiveWakeupBit 0;
BA_ "GenSigTimeoutTime_BCM" SG_ 2654208006 CBV_bit5 0;
BA_ "GenSigTimeoutTime_BSM" SG_ 2654208006 CBV_bit5 0;
BA_ "GenSigTimeoutTime_DIAG_TEST" SG_ 2654208006 CBV_bit5 0;
BA_ "GenSigTimeoutTime_ECM" SG_ 2654208006 CBV_bit5 0;
BA_ "GenSigTimeoutTime_EPS" SG_ 2654208006 CBV_bit5 0;
BA_ "GenSigTimeoutTime_IPC" SG_ 2654208006 CBV_bit5 0;
BA_ "GenSigTimeoutTime_MTA" SG_ 2654208006 CBV_bit5 0;
BA_ "GenSigTimeoutTime_ORC" SG_ 2654208006 CBV_bit5 0;
BA_ "GenSigTimeoutTime_PAM" SG_ 2654208006 CBV_bit5 0;
BA_ "GenSigTimeoutTime_BCM" SG_ 2654208006 CBV_bit6 0;
BA_ "GenSigTimeoutTime_BSM" SG_ 2654208006 CBV_bit6 0;
BA_ "GenSigTimeoutTime_DIAG_TEST" SG_ 2654208006 CBV_bit6 0;
BA_ "GenSigTimeoutTime_ECM" SG_ 2654208006 CBV_bit6 0;
BA_ "GenSigTimeoutTime_EPS" SG_ 2654208006 CBV_bit6 0;
BA_ "GenSigTimeoutTime_IPC" SG_ 2654208006 CBV_bit6 0;
BA_ "GenSigTimeoutTime_MTA" SG_ 2654208006 CBV_bit6 0;
BA_ "GenSigTimeoutTime_ORC" SG_ 2654208006 CBV_bit6 0;
BA_ "GenSigTimeoutTime_PAM" SG_ 2654208006 CBV_bit6 0;
BA_ "GenSigTimeoutTime_BCM" SG_ 2654208006 CBV_bit7 0;
BA_ "GenSigTimeoutTime_BSM" SG_ 2654208006 CBV_bit7 0;
BA_ "GenSigTimeoutTime_DIAG_TEST" SG_ 2654208006 CBV_bit7 0;
BA_ "GenSigTimeoutTime_ECM" SG_ 2654208006 CBV_bit7 0;
BA_ "GenSigTimeoutTime_EPS" SG_ 2654208006 CBV_bit7 0;
BA_ "GenSigTimeoutTime_IPC" SG_ 2654208006 CBV_bit7 0;
BA_ "GenSigTimeoutTime_MTA" SG_ 2654208006 CBV_bit7 0;
BA_ "GenSigTimeoutTime_ORC" SG_ 2654208006 CBV_bit7 0;
BA_ "GenSigTimeoutTime_PAM" SG_ 2654208006 CBV_bit7 0;
BA_ "GenSigTimeoutTime_BCM" SG_ 2654208006 SourceNodeIdentifier 0;
BA_ "GenSigTimeoutTime_BSM" SG_ 2654208006 SourceNodeIdentifier 0;
BA_ "GenSigTimeoutTime_DIAG_TEST" SG_ 2654208006 SourceNodeIdentifier 0;
BA_ "GenSigTimeoutTime_ECM" SG_ 2654208006 SourceNodeIdentifier 0;
BA_ "GenSigTimeoutTime_EPS" SG_ 2654208006 SourceNodeIdentifier 0;
BA_ "GenSigTimeoutTime_IPC" SG_ 2654208006 SourceNodeIdentifier 0;
BA_ "GenSigTimeoutTime_MTA" SG_ 2654208006 SourceNodeIdentifier 0;
BA_ "GenSigTimeoutTime_ORC" SG_ 2654208006 SourceNodeIdentifier 0;
BA_ "GenSigTimeoutTime_PAM" SG_ 2654208006 SourceNodeIdentifier 0;
BA_ "GenSigTimeoutTime_BCM" SG_ 2654208001 CBV_bit0 0;
BA_ "GenSigTimeoutTime_BSM" SG_ 2654208001 CBV_bit0 0;
BA_ "GenSigTimeoutTime_DIAG_TEST" SG_ 2654208001 CBV_bit0 0;
BA_ "GenSigTimeoutTime_ECM" SG_ 2654208001 CBV_bit0 0;
BA_ "GenSigTimeoutTime_EPS" SG_ 2654208001 CBV_bit0 0;
BA_ "GenSigTimeoutTime_IPC" SG_ 2654208001 CBV_bit0 0;
BA_ "GenSigTimeoutTime_MTA" SG_ 2654208001 CBV_bit0 0;
BA_ "GenSigTimeoutTime_ORC" SG_ 2654208001 CBV_bit0 0;
BA_ "GenSigTimeoutTime_PAM" SG_ 2654208001 CBV_bit0 0;
BA_ "GenSigTimeoutTime_BCM" SG_ 2654208001 CBV_bit1 0;
BA_ "GenSigTimeoutTime_BSM" SG_ 2654208001 CBV_bit1 0;
BA_ "GenSigTimeoutTime_DIAG_TEST" SG_ 2654208001 CBV_bit1 0;
BA_ "GenSigTimeoutTime_ECM" SG_ 2654208001 CBV_bit1 0;
BA_ "GenSigTimeoutTime_EPS" SG_ 2654208001 CBV_bit1 0;
BA_ "GenSigTimeoutTime_IPC" SG_ 2654208001 CBV_bit1 0;
BA_ "GenSigTimeoutTime_MTA" SG_ 2654208001 CBV_bit1 0;
BA_ "GenSigTimeoutTime_ORC" SG_ 2654208001 CBV_bit1 0;
BA_ "GenSigTimeoutTime_PAM" SG_ 2654208001 CBV_bit1 0;
BA_ "GenSigTimeoutTime_BCM" SG_ 2654208001 CBV_bit2 0;
BA_ "GenSigTimeoutTime_BSM" SG_ 2654208001 CBV_bit2 0;
BA_ "GenSigTimeoutTime_DIAG_TEST" SG_ 2654208001 CBV_bit2 0;
BA_ "GenSigTimeoutTime_ECM" SG_ 2654208001 CBV_bit2 0;
BA_ "GenSigTimeoutTime_EPS" SG_ 2654208001 CBV_bit2 0;
BA_ "GenSigTimeoutTime_IPC" SG_ 2654208001 CBV_bit2 0;
BA_ "GenSigTimeoutTime_MTA" SG_ 2654208001 CBV_bit2 0;
BA_ "GenSigTimeoutTime_ORC" SG_ 2654208001 CBV_bit2 0;
BA_ "GenSigTimeoutTime_PAM" SG_ 2654208001 CBV_bit2 0;
BA_ "GenSigTimeoutTime_BCM" SG_ 2654208001 CBV_bit3 0;
BA_ "GenSigTimeoutTime_BSM" SG_ 2654208001 CBV_bit3 0;
BA_ "GenSigTimeoutTime_DIAG_TEST" SG_ 2654208001 CBV_bit3 0;
BA_ "GenSigTimeoutTime_ECM" SG_ 2654208001 CBV_bit3 0;
BA_ "GenSigTimeoutTime_EPS" SG_ 2654208001 CBV_bit3 0;
BA_ "GenSigTimeoutTime_IPC" SG_ 2654208001 CBV_bit3 0;
BA_ "GenSigTimeoutTime_MTA" SG_ 2654208001 CBV_bit3 0;
BA_ "GenSigTimeoutTime_ORC" SG_ 2654208001 CBV_bit3 0;
BA_ "GenSigTimeoutTime_PAM" SG_ 2654208001 CBV_bit3 0;
BA_ "GenSigTimeoutTime_BCM" SG_ 2654208001 CBV_bit4_ActiveWakeupBit 0;
BA_ "GenSigTimeoutTime_BSM" SG_ 2654208001 CBV_bit4_ActiveWakeupBit 0;
BA_ "GenSigTimeoutTime_DIAG_TEST" SG_ 2654208001 CBV_bit4_ActiveWakeupBit 0;
BA_ "GenSigTimeoutTime_ECM" SG_ 2654208001 CBV_bit4_ActiveWakeupBit 0;
BA_ "GenSigTimeoutTime_EPS" SG_ 2654208001 CBV_bit4_ActiveWakeupBit 0;
BA_ "GenSigTimeoutTime_IPC" SG_ 2654208001 CBV_bit4_ActiveWakeupBit 0;
BA_ "GenSigTimeoutTime_MTA" SG_ 2654208001 CBV_bit4_ActiveWakeupBit 0;
BA_ "GenSigTimeoutTime_ORC" SG_ 2654208001 CBV_bit4_ActiveWakeupBit 0;
BA_ "GenSigTimeoutTime_PAM" SG_ 2654208001 CBV_bit4_ActiveWakeupBit 0;
BA_ "GenSigTimeoutTime_BCM" SG_ 2654208001 CBV_bit5 0;
BA_ "GenSigTimeoutTime_BSM" SG_ 2654208001 CBV_bit5 0;
BA_ "GenSigTimeoutTime_DIAG_TEST" SG_ 2654208001 CBV_bit5 0;
BA_ "GenSigTimeoutTime_ECM" SG_ 2654208001 CBV_bit5 0;
BA_ "GenSigTimeoutTime_EPS" SG_ 2654208001 CBV_bit5 0;
BA_ "GenSigTimeoutTime_IPC" SG_ 2654208001 CBV_bit5 0;
BA_ "GenSigTimeoutTime_MTA" SG_ 2654208001 CBV_bit5 0;
BA_ "GenSigTimeoutTime_ORC" SG_ 2654208001 CBV_bit5 0;
BA_ "GenSigTimeoutTime_PAM" SG_ 2654208001 CBV_bit5 0;
BA_ "GenSigTimeoutTime_BCM" SG_ 2654208001 CBV_bit6 0;
BA_ "GenSigTimeoutTime_BSM" SG_ 2654208001 CBV_bit6 0;
BA_ "GenSigTimeoutTime_DIAG_TEST" SG_ 2654208001 CBV_bit6 0;
BA_ "GenSigTimeoutTime_ECM" SG_ 2654208001 CBV_bit6 0;
BA_ "GenSigTimeoutTime_EPS" SG_ 2654208001 CBV_bit6 0;
BA_ "GenSigTimeoutTime_IPC" SG_ 2654208001 CBV_bit6 0;
BA_ "GenSigTimeoutTime_MTA" SG_ 2654208001 CBV_bit6 0;
BA_ "GenSigTimeoutTime_ORC" SG_ 2654208001 CBV_bit6 0;
BA_ "GenSigTimeoutTime_PAM" SG_ 2654208001 CBV_bit6 0;
BA_ "GenSigTimeoutTime_BCM" SG_ 2654208001 CBV_bit7 0;
BA_ "GenSigTimeoutTime_BSM" SG_ 2654208001 CBV_bit7 0;
BA_ "GenSigTimeoutTime_DIAG_TEST" SG_ 2654208001 CBV_bit7 0;
BA_ "GenSigTimeoutTime_ECM" SG_ 2654208001 CBV_bit7 0;
BA_ "GenSigTimeoutTime_EPS" SG_ 2654208001 CBV_bit7 0;
BA_ "GenSigTimeoutTime_IPC" SG_ 2654208001 CBV_bit7 0;
BA_ "GenSigTimeoutTime_MTA" SG_ 2654208001 CBV_bit7 0;
BA_ "GenSigTimeoutTime_ORC" SG_ 2654208001 CBV_bit7 0;
BA_ "GenSigTimeoutTime_PAM" SG_ 2654208001 CBV_bit7 0;
BA_ "GenSigTimeoutTime_BCM" SG_ 2654208001 SourceNodeIdentifier 0;
BA_ "GenSigTimeoutTime_BSM" SG_ 2654208001 SourceNodeIdentifier 0;
BA_ "GenSigTimeoutTime_DIAG_TEST" SG_ 2654208001 SourceNodeIdentifier 0;
BA_ "GenSigTimeoutTime_ECM" SG_ 2654208001 SourceNodeIdentifier 0;
BA_ "GenSigTimeoutTime_EPS" SG_ 2654208001 SourceNodeIdentifier 0;
BA_ "GenSigTimeoutTime_IPC" SG_ 2654208001 SourceNodeIdentifier 0;
BA_ "GenSigTimeoutTime_MTA" SG_ 2654208001 SourceNodeIdentifier 0;
BA_ "GenSigTimeoutTime_ORC" SG_ 2654208001 SourceNodeIdentifier 0;
BA_ "GenSigTimeoutTime_PAM" SG_ 2654208001 SourceNodeIdentifier 0;
BA_ "GenSigTimeoutTime_BCM" SG_ 2654208002 CBV_bit0 0;
BA_ "GenSigTimeoutTime_BSM" SG_ 2654208002 CBV_bit0 0;
BA_ "GenSigTimeoutTime_DIAG_TEST" SG_ 2654208002 CBV_bit0 0;
BA_ "GenSigTimeoutTime_ECM" SG_ 2654208002 CBV_bit0 0;
BA_ "GenSigTimeoutTime_EPS" SG_ 2654208002 CBV_bit0 0;
BA_ "GenSigTimeoutTime_IPC" SG_ 2654208002 CBV_bit0 0;
BA_ "GenSigTimeoutTime_MTA" SG_ 2654208002 CBV_bit0 0;
BA_ "GenSigTimeoutTime_ORC" SG_ 2654208002 CBV_bit0 0;
BA_ "GenSigTimeoutTime_PAM" SG_ 2654208002 CBV_bit0 0;
BA_ "GenSigTimeoutTime_BCM" SG_ 2654208002 CBV_bit1 0;
BA_ "GenSigTimeoutTime_BSM" SG_ 2654208002 CBV_bit1 0;
BA_ "GenSigTimeoutTime_DIAG_TEST" SG_ 2654208002 CBV_bit1 0;
BA_ "GenSigTimeoutTime_ECM" SG_ 2654208002 CBV_bit1 0;
BA_ "GenSigTimeoutTime_EPS" SG_ 2654208002 CBV_bit1 0;
BA_ "GenSigTimeoutTime_IPC" SG_ 2654208002 CBV_bit1 0;
BA_ "GenSigTimeoutTime_MTA" SG_ 2654208002 CBV_bit1 0;
BA_ "GenSigTimeoutTime_ORC" SG_ 2654208002 CBV_bit1 0;
BA_ "GenSigTimeoutTime_PAM" SG_ 2654208002 CBV_bit1 0;
BA_ "GenSigTimeoutTime_BCM" SG_ 2654208002 CBV_bit2 0;
BA_ "GenSigTimeoutTime_BSM" SG_ 2654208002 CBV_bit2 0;
BA_ "GenSigTimeoutTime_DIAG_TEST" SG_ 2654208002 CBV_bit2 0;
BA_ "GenSigTimeoutTime_ECM" SG_ 2654208002 CBV_bit2 0;
BA_ "GenSigTimeoutTime_EPS" SG_ 2654208002 CBV_bit2 0;
BA_ "GenSigTimeoutTime_IPC" SG_ 2654208002 CBV_bit2 0;
BA_ "GenSigTimeoutTime_MTA" SG_ 2654208002 CBV_bit2 0;
BA_ "GenSigTimeoutTime_ORC" SG_ 2654208002 CBV_bit2 0;
BA_ "GenSigTimeoutTime_PAM" SG_ 2654208002 CBV_bit2 0;
BA_ "GenSigTimeoutTime_BCM" SG_ 2654208002 CBV_bit3 0;
BA_ "GenSigTimeoutTime_BSM" SG_ 2654208002 CBV_bit3 0;
BA_ "GenSigTimeoutTime_DIAG_TEST" SG_ 2654208002 CBV_bit3 0;
BA_ "GenSigTimeoutTime_ECM" SG_ 2654208002 CBV_bit3 0;
BA_ "GenSigTimeoutTime_EPS" SG_ 2654208002 CBV_bit3 0;
BA_ "GenSigTimeoutTime_IPC" SG_ 2654208002 CBV_bit3 0;
BA_ "GenSigTimeoutTime_MTA" SG_ 2654208002 CBV_bit3 0;
BA_ "GenSigTimeoutTime_ORC" SG_ 2654208002 CBV_bit3 0;
BA_ "GenSigTimeoutTime_PAM" SG_ 2654208002 CBV_bit3 0;
BA_ "GenSigTimeoutTime_BCM" SG_ 2654208002 CBV_bit4_ActiveWakeupBit 0;
BA_ "GenSigTimeoutTime_BSM" SG_ 2654208002 CBV_bit4_ActiveWakeupBit 0;
BA_ "GenSigTimeoutTime_DIAG_TEST" SG_ 2654208002 CBV_bit4_ActiveWakeupBit 0;
BA_ "GenSigTimeoutTime_ECM" SG_ 2654208002 CBV_bit4_ActiveWakeupBit 0;
BA_ "GenSigTimeoutTime_EPS" SG_ 2654208002 CBV_bit4_ActiveWakeupBit 0;
BA_ "GenSigTimeoutTime_IPC" SG_ 2654208002 CBV_bit4_ActiveWakeupBit 0;
BA_ "GenSigTimeoutTime_MTA" SG_ 2654208002 CBV_bit4_ActiveWakeupBit 0;
BA_ "GenSigTimeoutTime_ORC" SG_ 2654208002 CBV_bit4_ActiveWakeupBit 0;
BA_ "GenSigTimeoutTime_PAM" SG_ 2654208002 CBV_bit4_ActiveWakeupBit 0;
BA_ "GenSigTimeoutTime_BCM" SG_ 2654208002 CBV_bit5 0;
BA_ "GenSigTimeoutTime_BSM" SG_ 2654208002 CBV_bit5 0;
BA_ "GenSigTimeoutTime_DIAG_TEST" SG_ 2654208002 CBV_bit5 0;
BA_ "GenSigTimeoutTime_ECM" SG_ 2654208002 CBV_bit5 0;
BA_ "GenSigTimeoutTime_EPS" SG_ 2654208002 CBV_bit5 0;
BA_ "GenSigTimeoutTime_IPC" SG_ 2654208002 CBV_bit5 0;
BA_ "GenSigTimeoutTime_MTA" SG_ 2654208002 CBV_bit5 0;
BA_ "GenSigTimeoutTime_ORC" SG_ 2654208002 CBV_bit5 0;
BA_ "GenSigTimeoutTime_PAM" SG_ 2654208002 CBV_bit5 0;
BA_ "GenSigTimeoutTime_BCM" SG_ 2654208002 CBV_bit6 0;
BA_ "GenSigTimeoutTime_BSM" SG_ 2654208002 CBV_bit6 0;
BA_ "GenSigTimeoutTime_DIAG_TEST" SG_ 2654208002 CBV_bit6 0;
BA_ "GenSigTimeoutTime_ECM" SG_ 2654208002 CBV_bit6 0;
BA_ "GenSigTimeoutTime_EPS" SG_ 2654208002 CBV_bit6 0;
BA_ "GenSigTimeoutTime_IPC" SG_ 2654208002 CBV_bit6 0;
BA_ "GenSigTimeoutTime_MTA" SG_ 2654208002 CBV_bit6 0;
BA_ "GenSigTimeoutTime_ORC" SG_ 2654208002 CBV_bit6 0;
BA_ "GenSigTimeoutTime_PAM" SG_ 2654208002 CBV_bit6 0;
BA_ "GenSigTimeoutTime_BCM" SG_ 2654208002 CBV_bit7 0;
BA_ "GenSigTimeoutTime_BSM" SG_ 2654208002 CBV_bit7 0;
BA_ "GenSigTimeoutTime_DIAG_TEST" SG_ 2654208002 CBV_bit7 0;
BA_ "GenSigTimeoutTime_ECM" SG_ 2654208002 CBV_bit7 0;
BA_ "GenSigTimeoutTime_EPS" SG_ 2654208002 CBV_bit7 0;
BA_ "GenSigTimeoutTime_IPC" SG_ 2654208002 CBV_bit7 0;
BA_ "GenSigTimeoutTime_MTA" SG_ 2654208002 CBV_bit7 0;
BA_ "GenSigTimeoutTime_ORC" SG_ 2654208002 CBV_bit7 0;
BA_ "GenSigTimeoutTime_PAM" SG_ 2654208002 CBV_bit7 0;
BA_ "GenSigTimeoutTime_BCM" SG_ 2654208002 SourceNodeIdentifier 0;
BA_ "GenSigTimeoutTime_BSM" SG_ 2654208002 SourceNodeIdentifier 0;
BA_ "GenSigTimeoutTime_DIAG_TEST" SG_ 2654208002 SourceNodeIdentifier 0;
BA_ "GenSigTimeoutTime_ECM" SG_ 2654208002 SourceNodeIdentifier 0;
BA_ "GenSigTimeoutTime_EPS" SG_ 2654208002 SourceNodeIdentifier 0;
BA_ "GenSigTimeoutTime_IPC" SG_ 2654208002 SourceNodeIdentifier 0;
BA_ "GenSigTimeoutTime_MTA" SG_ 2654208002 SourceNodeIdentifier 0;
BA_ "GenSigTimeoutTime_ORC" SG_ 2654208002 SourceNodeIdentifier 0;
BA_ "GenSigTimeoutTime_PAM" SG_ 2654208002 SourceNodeIdentifier 0;
BA_ "GenSigTimeoutTime_BCM" SG_ 2654208003 CBV_bit0 0;
BA_ "GenSigTimeoutTime_BSM" SG_ 2654208003 CBV_bit0 0;
BA_ "GenSigTimeoutTime_DIAG_TEST" SG_ 2654208003 CBV_bit0 0;
BA_ "GenSigTimeoutTime_ECM" SG_ 2654208003 CBV_bit0 0;
BA_ "GenSigTimeoutTime_EPS" SG_ 2654208003 CBV_bit0 0;
BA_ "GenSigTimeoutTime_IPC" SG_ 2654208003 CBV_bit0 0;
BA_ "GenSigTimeoutTime_MTA" SG_ 2654208003 CBV_bit0 0;
BA_ "GenSigTimeoutTime_ORC" SG_ 2654208003 CBV_bit0 0;
BA_ "GenSigTimeoutTime_PAM" SG_ 2654208003 CBV_bit0 0;
BA_ "GenSigTimeoutTime_BCM" SG_ 2654208003 CBV_bit1 0;
BA_ "GenSigTimeoutTime_BSM" SG_ 2654208003 CBV_bit1 0;
BA_ "GenSigTimeoutTime_DIAG_TEST" SG_ 2654208003 CBV_bit1 0;
BA_ "GenSigTimeoutTime_ECM" SG_ 2654208003 CBV_bit1 0;
BA_ "GenSigTimeoutTime_EPS" SG_ 2654208003 CBV_bit1 0;
BA_ "GenSigTimeoutTime_IPC" SG_ 2654208003 CBV_bit1 0;
BA_ "GenSigTimeoutTime_MTA" SG_ 2654208003 CBV_bit1 0;
BA_ "GenSigTimeoutTime_ORC" SG_ 2654208003 CBV_bit1 0;
BA_ "GenSigTimeoutTime_PAM" SG_ 2654208003 CBV_bit1 0;
BA_ "GenSigTimeoutTime_BCM" SG_ 2654208003 CBV_bit2 0;
BA_ "GenSigTimeoutTime_BSM" SG_ 2654208003 CBV_bit2 0;
BA_ "GenSigTimeoutTime_DIAG_TEST" SG_ 2654208003 CBV_bit2 0;
BA_ "GenSigTimeoutTime_ECM" SG_ 2654208003 CBV_bit2 0;
BA_ "GenSigTimeoutTime_EPS" SG_ 2654208003 CBV_bit2 0;
BA_ "GenSigTimeoutTime_IPC" SG_ 2654208003 CBV_bit2 0;
BA_ "GenSigTimeoutTime_MTA" SG_ 2654208003 CBV_bit2 0;
BA_ "GenSigTimeoutTime_ORC" SG_ 2654208003 CBV_bit2 0;
BA_ "GenSigTimeoutTime_PAM" SG_ 2654208003 CBV_bit2 0;
BA_ "GenSigTimeoutTime_BCM" SG_ 2654208003 CBV_bit3 0;
BA_ "GenSigTimeoutTime_BSM" SG_ 2654208003 CBV_bit3 0;
BA_ "GenSigTimeoutTime_DIAG_TEST" SG_ 2654208003 CBV_bit3 0;
BA_ "GenSigTimeoutTime_ECM" SG_ 2654208003 CBV_bit3 0;
BA_ "GenSigTimeoutTime_EPS" SG_ 2654208003 CBV_bit3 0;
BA_ "GenSigTimeoutTime_IPC" SG_ 2654208003 CBV_bit3 0;
BA_ "GenSigTimeoutTime_MTA" SG_ 2654208003 CBV_bit3 0;
BA_ "GenSigTimeoutTime_ORC" SG_ 2654208003 CBV_bit3 0;
BA_ "GenSigTimeoutTime_PAM" SG_ 2654208003 CBV_bit3 0;
BA_ "GenSigTimeoutTime_BCM" SG_ 2654208003 CBV_bit4_ActiveWakeupBit 0;
BA_ "GenSigTimeoutTime_BSM" SG_ 2654208003 CBV_bit4_ActiveWakeupBit 0;
BA_ "GenSigTimeoutTime_DIAG_TEST" SG_ 2654208003 CBV_bit4_ActiveWakeupBit 0;
BA_ "GenSigTimeoutTime_ECM" SG_ 2654208003 CBV_bit4_ActiveWakeupBit 0;
BA_ "GenSigTimeoutTime_EPS" SG_ 2654208003 CBV_bit4_ActiveWakeupBit 0;
BA_ "GenSigTimeoutTime_IPC" SG_ 2654208003 CBV_bit4_ActiveWakeupBit 0;
BA_ "GenSigTimeoutTime_MTA" SG_ 2654208003 CBV_bit4_ActiveWakeupBit 0;
BA_ "GenSigTimeoutTime_ORC" SG_ 2654208003 CBV_bit4_ActiveWakeupBit 0;
BA_ "GenSigTimeoutTime_PAM" SG_ 2654208003 CBV_bit4_ActiveWakeupBit 0;
BA_ "GenSigTimeoutTime_BCM" SG_ 2654208003 CBV_bit5 0;
BA_ "GenSigTimeoutTime_BSM" SG_ 2654208003 CBV_bit5 0;
BA_ "GenSigTimeoutTime_DIAG_TEST" SG_ 2654208003 CBV_bit5 0;
BA_ "GenSigTimeoutTime_ECM" SG_ 2654208003 CBV_bit5 0;
BA_ "GenSigTimeoutTime_EPS" SG_ 2654208003 CBV_bit5 0;
BA_ "GenSigTimeoutTime_IPC" SG_ 2654208003 CBV_bit5 0;
BA_ "GenSigTimeoutTime_MTA" SG_ 2654208003 CBV_bit5 0;
BA_ "GenSigTimeoutTime_ORC" SG_ 2654208003 CBV_bit5 0;
BA_ "GenSigTimeoutTime_PAM" SG_ 2654208003 CBV_bit5 0;
BA_ "GenSigTimeoutTime_BCM" SG_ 2654208003 CBV_bit6 0;
BA_ "GenSigTimeoutTime_BSM" SG_ 2654208003 CBV_bit6 0;
BA_ "GenSigTimeoutTime_DIAG_TEST" SG_ 2654208003 CBV_bit6 0;
BA_ "GenSigTimeoutTime_ECM" SG_ 2654208003 CBV_bit6 0;
BA_ "GenSigTimeoutTime_EPS" SG_ 2654208003 CBV_bit6 0;
BA_ "GenSigTimeoutTime_IPC" SG_ 2654208003 CBV_bit6 0;
BA_ "GenSigTimeoutTime_MTA" SG_ 2654208003 CBV_bit6 0;
BA_ "GenSigTimeoutTime_ORC" SG_ 2654208003 CBV_bit6 0;
BA_ "GenSigTimeoutTime_PAM" SG_ 2654208003 CBV_bit6 0;
BA_ "GenSigTimeoutTime_BCM" SG_ 2654208003 CBV_bit7 0;
BA_ "GenSigTimeoutTime_BSM" SG_ 2654208003 CBV_bit7 0;
BA_ "GenSigTimeoutTime_DIAG_TEST" SG_ 2654208003 CBV_bit7 0;
BA_ "GenSigTimeoutTime_ECM" SG_ 2654208003 CBV_bit7 0;
BA_ "GenSigTimeoutTime_EPS" SG_ 2654208003 CBV_bit7 0;
BA_ "GenSigTimeoutTime_IPC" SG_ 2654208003 CBV_bit7 0;
BA_ "GenSigTimeoutTime_MTA" SG_ 2654208003 CBV_bit7 0;
BA_ "GenSigTimeoutTime_ORC" SG_ 2654208003 CBV_bit7 0;
BA_ "GenSigTimeoutTime_PAM" SG_ 2654208003 CBV_bit7 0;
BA_ "GenSigTimeoutTime_BCM" SG_ 2654208003 SourceNodeIdentifier 0;
BA_ "GenSigTimeoutTime_BSM" SG_ 2654208003 SourceNodeIdentifier 0;
BA_ "GenSigTimeoutTime_DIAG_TEST" SG_ 2654208003 SourceNodeIdentifier 0;
BA_ "GenSigTimeoutTime_ECM" SG_ 2654208003 SourceNodeIdentifier 0;
BA_ "GenSigTimeoutTime_EPS" SG_ 2654208003 SourceNodeIdentifier 0;
BA_ "GenSigTimeoutTime_IPC" SG_ 2654208003 SourceNodeIdentifier 0;
BA_ "GenSigTimeoutTime_MTA" SG_ 2654208003 SourceNodeIdentifier 0;
BA_ "GenSigTimeoutTime_ORC" SG_ 2654208003 SourceNodeIdentifier 0;
BA_ "GenSigTimeoutTime_PAM" SG_ 2654208003 SourceNodeIdentifier 0;
BA_ "GenSigTimeoutTime_BCM" SG_ 2654208011 CBV_bit0 0;
BA_ "GenSigTimeoutTime_BSM" SG_ 2654208011 CBV_bit0 0;
BA_ "GenSigTimeoutTime_DIAG_TEST" SG_ 2654208011 CBV_bit0 0;
BA_ "GenSigTimeoutTime_ECM" SG_ 2654208011 CBV_bit0 0;
BA_ "GenSigTimeoutTime_EPS" SG_ 2654208011 CBV_bit0 0;
BA_ "GenSigTimeoutTime_IPC" SG_ 2654208011 CBV_bit0 0;
BA_ "GenSigTimeoutTime_MTA" SG_ 2654208011 CBV_bit0 0;
BA_ "GenSigTimeoutTime_ORC" SG_ 2654208011 CBV_bit0 0;
BA_ "GenSigTimeoutTime_PAM" SG_ 2654208011 CBV_bit0 0;
BA_ "GenSigTimeoutTime_BCM" SG_ 2654208011 CBV_bit1 0;
BA_ "GenSigTimeoutTime_BSM" SG_ 2654208011 CBV_bit1 0;
BA_ "GenSigTimeoutTime_DIAG_TEST" SG_ 2654208011 CBV_bit1 0;
BA_ "GenSigTimeoutTime_ECM" SG_ 2654208011 CBV_bit1 0;
BA_ "GenSigTimeoutTime_EPS" SG_ 2654208011 CBV_bit1 0;
BA_ "GenSigTimeoutTime_IPC" SG_ 2654208011 CBV_bit1 0;
BA_ "GenSigTimeoutTime_MTA" SG_ 2654208011 CBV_bit1 0;
BA_ "GenSigTimeoutTime_ORC" SG_ 2654208011 CBV_bit1 0;
BA_ "GenSigTimeoutTime_PAM" SG_ 2654208011 CBV_bit1 0;
BA_ "GenSigTimeoutTime_BCM" SG_ 2654208011 CBV_bit2 0;
BA_ "GenSigTimeoutTime_BSM" SG_ 2654208011 CBV_bit2 0;
BA_ "GenSigTimeoutTime_DIAG_TEST" SG_ 2654208011 CBV_bit2 0;
BA_ "GenSigTimeoutTime_ECM" SG_ 2654208011 CBV_bit2 0;
BA_ "GenSigTimeoutTime_EPS" SG_ 2654208011 CBV_bit2 0;
BA_ "GenSigTimeoutTime_IPC" SG_ 2654208011 CBV_bit2 0;
BA_ "GenSigTimeoutTime_MTA" SG_ 2654208011 CBV_bit2 0;
BA_ "GenSigTimeoutTime_ORC" SG_ 2654208011 CBV_bit2 0;
BA_ "GenSigTimeoutTime_PAM" SG_ 2654208011 CBV_bit2 0;
BA_ "GenSigTimeoutTime_BCM" SG_ 2654208011 CBV_bit3 0;
BA_ "GenSigTimeoutTime_BSM" SG_ 2654208011 CBV_bit3 0;
BA_ "GenSigTimeoutTime_DIAG_TEST" SG_ 2654208011 CBV_bit3 0;
BA_ "GenSigTimeoutTime_ECM" SG_ 2654208011 CBV_bit3 0;
BA_ "GenSigTimeoutTime_EPS" SG_ 2654208011 CBV_bit3 0;
BA_ "GenSigTimeoutTime_IPC" SG_ 2654208011 CBV_bit3 0;
BA_ "GenSigTimeoutTime_MTA" SG_ 2654208011 CBV_bit3 0;
BA_ "GenSigTimeoutTime_ORC" SG_ 2654208011 CBV_bit3 0;
BA_ "GenSigTimeoutTime_PAM" SG_ 2654208011 CBV_bit3 0;
BA_ "GenSigTimeoutTime_BCM" SG_ 2654208011 CBV_bit4_ActiveWakeupBit 0;
BA_ "GenSigTimeoutTime_BSM" SG_ 2654208011 CBV_bit4_ActiveWakeupBit 0;
BA_ "GenSigTimeoutTime_DIAG_TEST" SG_ 2654208011 CBV_bit4_ActiveWakeupBit 0;
BA_ "GenSigTimeoutTime_ECM" SG_ 2654208011 CBV_bit4_ActiveWakeupBit 0;
BA_ "GenSigTimeoutTime_EPS" SG_ 2654208011 CBV_bit4_ActiveWakeupBit 0;
BA_ "GenSigTimeoutTime_IPC" SG_ 2654208011 CBV_bit4_ActiveWakeupBit 0;
BA_ "GenSigTimeoutTime_MTA" SG_ 2654208011 CBV_bit4_ActiveWakeupBit 0;
BA_ "GenSigTimeoutTime_ORC" SG_ 2654208011 CBV_bit4_ActiveWakeupBit 0;
BA_ "GenSigTimeoutTime_PAM" SG_ 2654208011 CBV_bit4_ActiveWakeupBit 0;
BA_ "GenSigTimeoutTime_BCM" SG_ 2654208011 CBV_bit5 0;
BA_ "GenSigTimeoutTime_BSM" SG_ 2654208011 CBV_bit5 0;
BA_ "GenSigTimeoutTime_DIAG_TEST" SG_ 2654208011 CBV_bit5 0;
BA_ "GenSigTimeoutTime_ECM" SG_ 2654208011 CBV_bit5 0;
BA_ "GenSigTimeoutTime_EPS" SG_ 2654208011 CBV_bit5 0;
BA_ "GenSigTimeoutTime_IPC" SG_ 2654208011 CBV_bit5 0;
BA_ "GenSigTimeoutTime_MTA" SG_ 2654208011 CBV_bit5 0;
BA_ "GenSigTimeoutTime_ORC" SG_ 2654208011 CBV_bit5 0;
BA_ "GenSigTimeoutTime_PAM" SG_ 2654208011 CBV_bit5 0;
BA_ "GenSigTimeoutTime_BCM" SG_ 2654208011 CBV_bit6 0;
BA_ "GenSigTimeoutTime_BSM" SG_ 2654208011 CBV_bit6 0;
BA_ "GenSigTimeoutTime_DIAG_TEST" SG_ 2654208011 CBV_bit6 0;
BA_ "GenSigTimeoutTime_ECM" SG_ 2654208011 CBV_bit6 0;
BA_ "GenSigTimeoutTime_EPS" SG_ 2654208011 CBV_bit6 0;
BA_ "GenSigTimeoutTime_IPC" SG_ 2654208011 CBV_bit6 0;
BA_ "GenSigTimeoutTime_MTA" SG_ 2654208011 CBV_bit6 0;
BA_ "GenSigTimeoutTime_ORC" SG_ 2654208011 CBV_bit6 0;
BA_ "GenSigTimeoutTime_PAM" SG_ 2654208011 CBV_bit6 0;
BA_ "GenSigTimeoutTime_BCM" SG_ 2654208011 CBV_bit7 0;
BA_ "GenSigTimeoutTime_BSM" SG_ 2654208011 CBV_bit7 0;
BA_ "GenSigTimeoutTime_DIAG_TEST" SG_ 2654208011 CBV_bit7 0;
BA_ "GenSigTimeoutTime_ECM" SG_ 2654208011 CBV_bit7 0;
BA_ "GenSigTimeoutTime_EPS" SG_ 2654208011 CBV_bit7 0;
BA_ "GenSigTimeoutTime_IPC" SG_ 2654208011 CBV_bit7 0;
BA_ "GenSigTimeoutTime_MTA" SG_ 2654208011 CBV_bit7 0;
BA_ "GenSigTimeoutTime_ORC" SG_ 2654208011 CBV_bit7 0;
BA_ "GenSigTimeoutTime_PAM" SG_ 2654208011 CBV_bit7 0;
BA_ "GenSigTimeoutTime_BCM" SG_ 2654208011 SourceNodeIdentifier 0;
BA_ "GenSigTimeoutTime_BSM" SG_ 2654208011 SourceNodeIdentifier 0;
BA_ "GenSigTimeoutTime_DIAG_TEST" SG_ 2654208011 SourceNodeIdentifier 0;
BA_ "GenSigTimeoutTime_ECM" SG_ 2654208011 SourceNodeIdentifier 0;
BA_ "GenSigTimeoutTime_EPS" SG_ 2654208011 SourceNodeIdentifier 0;
BA_ "GenSigTimeoutTime_IPC" SG_ 2654208011 SourceNodeIdentifier 0;
BA_ "GenSigTimeoutTime_MTA" SG_ 2654208011 SourceNodeIdentifier 0;
BA_ "GenSigTimeoutTime_ORC" SG_ 2654208011 SourceNodeIdentifier 0;
BA_ "GenSigTimeoutTime_PAM" SG_ 2654208011 SourceNodeIdentifier 0;
BA_ "GenSigTimeoutTime_BCM" SG_ 270 InternalError 0;
BA_ "GenSigTimeoutTime_DIAG_TEST" SG_ 270 InternalError 0;
BA_ "GenSigTimeoutTime_ECM" SG_ 270 InternalError 0;
BA_ "GenSigTimeoutTime_EPS" SG_ 270 InternalError 0;
BA_ "GenSigTimeoutTime_IPC" SG_ 270 InternalError 0;
BA_ "GenSigTimeoutTime_MTA" SG_ 270 InternalError 0;
BA_ "GenSigTimeoutTime_ORC" SG_ 270 InternalError 0;
BA_ "GenSigTimeoutTime_PAM" SG_ 270 InternalError 0;
BA_ "GenSigTimeoutTime_BCM" SG_ 270 LatAcceleration 0;
BA_ "GenSigTimeoutTime_DIAG_TEST" SG_ 270 LatAcceleration 0;
BA_ "GenSigTimeoutTime_ECM" SG_ 270 LatAcceleration 0;
BA_ "GenSigTimeoutTime_EPS" SG_ 270 LatAcceleration 0;
BA_ "GenSigTimeoutTime_IPC" SG_ 270 LatAcceleration 0;
BA_ "GenSigTimeoutTime_MTA" SG_ 270 LatAcceleration 0;
BA_ "GenSigTimeoutTime_ORC" SG_ 270 LatAcceleration 0;
BA_ "GenSigTimeoutTime_PAM" SG_ 270 LatAcceleration 0;
BA_ "GenSigTimeoutTime_BCM" SG_ 270 LatAccelerationFailSts 0;
BA_ "GenSigTimeoutTime_DIAG_TEST" SG_ 270 LatAccelerationFailSts 0;
BA_ "GenSigTimeoutTime_ECM" SG_ 270 LatAccelerationFailSts 0;
BA_ "GenSigTimeoutTime_EPS" SG_ 270 LatAccelerationFailSts 0;
BA_ "GenSigTimeoutTime_IPC" SG_ 270 LatAccelerationFailSts 0;
BA_ "GenSigTimeoutTime_MTA" SG_ 270 LatAccelerationFailSts 0;
BA_ "GenSigTimeoutTime_ORC" SG_ 270 LatAccelerationFailSts 0;
BA_ "GenSigTimeoutTime_PAM" SG_ 270 LatAccelerationFailSts 0;
BA_ "GenSigTimeoutTime_BCM" SG_ 270 LongAcceleration 0;
BA_ "GenSigTimeoutTime_DIAG_TEST" SG_ 270 LongAcceleration 0;
BA_ "GenSigTimeoutTime_ECM" SG_ 270 LongAcceleration 0;
BA_ "GenSigTimeoutTime_EPS" SG_ 270 LongAcceleration 0;
BA_ "GenSigTimeoutTime_IPC" SG_ 270 LongAcceleration 0;
BA_ "GenSigTimeoutTime_MTA" SG_ 270 LongAcceleration 0;
BA_ "GenSigTimeoutTime_ORC" SG_ 270 LongAcceleration 0;
BA_ "GenSigTimeoutTime_PAM" SG_ 270 LongAcceleration 0;
BA_ "GenSigTimeoutTime_BCM" SG_ 270 LongAccelerationFailSts 0;
BA_ "GenSigTimeoutTime_DIAG_TEST" SG_ 270 LongAccelerationFailSts 0;
BA_ "GenSigTimeoutTime_ECM" SG_ 270 LongAccelerationFailSts 0;
BA_ "GenSigTimeoutTime_EPS" SG_ 270 LongAccelerationFailSts 0;
BA_ "GenSigTimeoutTime_IPC" SG_ 270 LongAccelerationFailSts 0;
BA_ "GenSigTimeoutTime_MTA" SG_ 270 LongAccelerationFailSts 0;
BA_ "GenSigTimeoutTime_ORC" SG_ 270 LongAccelerationFailSts 0;
BA_ "GenSigTimeoutTime_PAM" SG_ 270 LongAccelerationFailSts 0;
BA_ "GenSigTimeoutTime_BCM" SG_ 270 YawRate 0;
BA_ "GenSigTimeoutTime_DIAG_TEST" SG_ 270 YawRate 0;
BA_ "GenSigTimeoutTime_ECM" SG_ 270 YawRate 0;
BA_ "GenSigTimeoutTime_EPS" SG_ 270 YawRate 0;
BA_ "GenSigTimeoutTime_IPC" SG_ 270 YawRate 0;
BA_ "GenSigTimeoutTime_MTA" SG_ 270 YawRate 0;
BA_ "GenSigTimeoutTime_ORC" SG_ 270 YawRate 0;
BA_ "GenSigTimeoutTime_PAM" SG_ 270 YawRate 0;
BA_ "GenSigTimeoutTime_BCM" SG_ 270 YawRateFailSts 0;
BA_ "GenSigTimeoutTime_DIAG_TEST" SG_ 270 YawRateFailSts 0;
BA_ "GenSigTimeoutTime_ECM" SG_ 270 YawRateFailSts 0;
BA_ "GenSigTimeoutTime_EPS" SG_ 270 YawRateFailSts 0;
BA_ "GenSigTimeoutTime_IPC" SG_ 270 YawRateFailSts 0;
BA_ "GenSigTimeoutTime_MTA" SG_ 270 YawRateFailSts 0;
BA_ "GenSigTimeoutTime_ORC" SG_ 270 YawRateFailSts 0;
BA_ "GenSigTimeoutTime_PAM" SG_ 270 YawRateFailSts 0;
BA_ "GenSigTimeoutTime_BCM" SG_ 999 Alert_CHR 0;
BA_ "GenSigTimeoutTime_BSM" SG_ 999 Alert_CHR 0;
BA_ "GenSigTimeoutTime_DIAG_TEST" SG_ 999 Alert_CHR 0;
BA_ "GenSigTimeoutTime_ECM" SG_ 999 Alert_CHR 0;
BA_ "GenSigTimeoutTime_EPS" SG_ 999 Alert_CHR 0;
BA_ "GenSigTimeoutTime_MTA" SG_ 999 Alert_CHR 0;
BA_ "GenSigTimeoutTime_ORC" SG_ 999 Alert_CHR 0;
BA_ "GenSigTimeoutTime_PAM" SG_ 999 Alert_CHR 0;
BA_ "GenSigTimeoutTime_BCM" SG_ 999 Alert_LHR 0;
BA_ "GenSigTimeoutTime_BSM" SG_ 999 Alert_LHR 0;
BA_ "GenSigTimeoutTime_DIAG_TEST" SG_ 999 Alert_LHR 0;
BA_ "GenSigTimeoutTime_ECM" SG_ 999 Alert_LHR 0;
BA_ "GenSigTimeoutTime_EPS" SG_ 999 Alert_LHR 0;
BA_ "GenSigTimeoutTime_MTA" SG_ 999 Alert_LHR 0;
BA_ "GenSigTimeoutTime_ORC" SG_ 999 Alert_LHR 0;
BA_ "GenSigTimeoutTime_PAM" SG_ 999 Alert_LHR 0;
BA_ "GenSigTimeoutTime_BCM" SG_ 999 Alert_RHR 0;
BA_ "GenSigTimeoutTime_BSM" SG_ 999 Alert_RHR 0;
BA_ "GenSigTimeoutTime_DIAG_TEST" SG_ 999 Alert_RHR 0;
BA_ "GenSigTimeoutTime_ECM" SG_ 999 Alert_RHR 0;
BA_ "GenSigTimeoutTime_EPS" SG_ 999 Alert_RHR 0;
BA_ "GenSigTimeoutTime_MTA" SG_ 999 Alert_RHR 0;
BA_ "GenSigTimeoutTime_ORC" SG_ 999 Alert_RHR 0;
BA_ "GenSigTimeoutTime_PAM" SG_ 999 Alert_RHR 0;
BA_ "GenSigSendType" SG_ 999 ChimeActivation_LHR 6;
BA_ "GenSigTimeoutTime_BCM" SG_ 999 ChimeActivation_LHR 0;
BA_ "GenSigTimeoutTime_BSM" SG_ 999 ChimeActivation_LHR 0;
BA_ "GenSigTimeoutTime_DIAG_TEST" SG_ 999 ChimeActivation_LHR 0;
BA_ "GenSigTimeoutTime_ECM" SG_ 999 ChimeActivation_LHR 0;
BA_ "GenSigTimeoutTime_EPS" SG_ 999 ChimeActivation_LHR 0;
BA_ "GenSigTimeoutTime_MTA" SG_ 999 ChimeActivation_LHR 0;
BA_ "GenSigTimeoutTime_ORC" SG_ 999 ChimeActivation_LHR 0;
BA_ "GenSigTimeoutTime_PAM" SG_ 999 ChimeActivation_LHR 0;
BA_ "GenSigSendType" SG_ 999 ChimeActivation_RHR 6;
BA_ "GenSigTimeoutTime_BCM" SG_ 999 ChimeActivation_RHR 0;
BA_ "GenSigTimeoutTime_BSM" SG_ 999 ChimeActivation_RHR 0;
BA_ "GenSigTimeoutTime_DIAG_TEST" SG_ 999 ChimeActivation_RHR 0;
BA_ "GenSigTimeoutTime_ECM" SG_ 999 ChimeActivation_RHR 0;
BA_ "GenSigTimeoutTime_EPS" SG_ 999 ChimeActivation_RHR 0;
BA_ "GenSigTimeoutTime_MTA" SG_ 999 ChimeActivation_RHR 0;
BA_ "GenSigTimeoutTime_ORC" SG_ 999 ChimeActivation_RHR 0;
BA_ "GenSigTimeoutTime_PAM" SG_ 999 ChimeActivation_RHR 0;
BA_ "GenSigTimeoutTime_BCM" SG_ 999 ChimeRepetitionRate_Rear 0;
BA_ "GenSigTimeoutTime_BSM" SG_ 999 ChimeRepetitionRate_Rear 0;
BA_ "GenSigTimeoutTime_DIAG_TEST" SG_ 999 ChimeRepetitionRate_Rear 0;
BA_ "GenSigTimeoutTime_ECM" SG_ 999 ChimeRepetitionRate_Rear 0;
BA_ "GenSigTimeoutTime_EPS" SG_ 999 ChimeRepetitionRate_Rear 0;
BA_ "GenSigTimeoutTime_MTA" SG_ 999 ChimeRepetitionRate_Rear 0;
BA_ "GenSigTimeoutTime_ORC" SG_ 999 ChimeRepetitionRate_Rear 0;
BA_ "GenSigTimeoutTime_PAM" SG_ 999 ChimeRepetitionRate_Rear 0;
BA_ "GenSigTimeoutTime_BCM" SG_ 999 ChimeType_Rear 0;
BA_ "GenSigTimeoutTime_BSM" SG_ 999 ChimeType_Rear 0;
BA_ "GenSigTimeoutTime_DIAG_TEST" SG_ 999 ChimeType_Rear 0;
BA_ "GenSigTimeoutTime_ECM" SG_ 999 ChimeType_Rear 0;
BA_ "GenSigTimeoutTime_EPS" SG_ 999 ChimeType_Rear 0;
BA_ "GenSigTimeoutTime_MTA" SG_ 999 ChimeType_Rear 0;
BA_ "GenSigTimeoutTime_ORC" SG_ 999 ChimeType_Rear 0;
BA_ "GenSigTimeoutTime_PAM" SG_ 999 ChimeType_Rear 0;
BA_ "GenSigSendType" SG_ 999 DisplayActivation 6;
BA_ "GenSigTimeoutTime_BCM" SG_ 999 DisplayActivation 0;
BA_ "GenSigTimeoutTime_BSM" SG_ 999 DisplayActivation 0;
BA_ "GenSigTimeoutTime_DIAG_TEST" SG_ 999 DisplayActivation 0;
BA_ "GenSigTimeoutTime_ECM" SG_ 999 DisplayActivation 0;
BA_ "GenSigTimeoutTime_EPS" SG_ 999 DisplayActivation 0;
BA_ "GenSigTimeoutTime_MTA" SG_ 999 DisplayActivation 0;
BA_ "GenSigTimeoutTime_ORC" SG_ 999 DisplayActivation 0;
BA_ "GenSigTimeoutTime_PAM" SG_ 999 DisplayActivation 0;
BA_ "GenSigTimeoutTime_BCM" SG_ 999 Graphic_CHR 0;
BA_ "GenSigTimeoutTime_BSM" SG_ 999 Graphic_CHR 0;
BA_ "GenSigTimeoutTime_DIAG_TEST" SG_ 999 Graphic_CHR 0;
BA_ "GenSigTimeoutTime_ECM" SG_ 999 Graphic_CHR 0;
BA_ "GenSigTimeoutTime_EPS" SG_ 999 Graphic_CHR 0;
BA_ "GenSigTimeoutTime_MTA" SG_ 999 Graphic_CHR 0;
BA_ "GenSigTimeoutTime_ORC" SG_ 999 Graphic_CHR 0;
BA_ "GenSigTimeoutTime_PAM" SG_ 999 Graphic_CHR 0;
BA_ "GenSigTimeoutTime_BCM" SG_ 999 Graphic_LHR 0;
BA_ "GenSigTimeoutTime_BSM" SG_ 999 Graphic_LHR 0;
BA_ "GenSigTimeoutTime_DIAG_TEST" SG_ 999 Graphic_LHR 0;
BA_ "GenSigTimeoutTime_ECM" SG_ 999 Graphic_LHR 0;
BA_ "GenSigTimeoutTime_EPS" SG_ 999 Graphic_LHR 0;
BA_ "GenSigTimeoutTime_MTA" SG_ 999 Graphic_LHR 0;
BA_ "GenSigTimeoutTime_ORC" SG_ 999 Graphic_LHR 0;
BA_ "GenSigTimeoutTime_PAM" SG_ 999 Graphic_LHR 0;
BA_ "GenSigTimeoutTime_BCM" SG_ 999 Graphic_RHR 0;
BA_ "GenSigTimeoutTime_BSM" SG_ 999 Graphic_RHR 0;
BA_ "GenSigTimeoutTime_DIAG_TEST" SG_ 999 Graphic_RHR 0;
BA_ "GenSigTimeoutTime_ECM" SG_ 999 Graphic_RHR 0;
BA_ "GenSigTimeoutTime_EPS" SG_ 999 Graphic_RHR 0;
BA_ "GenSigTimeoutTime_MTA" SG_ 999 Graphic_RHR 0;
BA_ "GenSigTimeoutTime_ORC" SG_ 999 Graphic_RHR 0;
BA_ "GenSigTimeoutTime_PAM" SG_ 999 Graphic_RHR 0;
BA_ "GenSigTimeoutTime_BCM" SG_ 2654339072 CurrentFailSts_BCM 0;
BA_ "GenSigTimeoutTime_BSM" SG_ 2654339072 CurrentFailSts_BCM 0;
BA_ "GenSigTimeoutTime_DIAG_TEST" SG_ 2654339072 CurrentFailSts_BCM 0;
BA_ "GenSigTimeoutTime_ECM" SG_ 2654339072 CurrentFailSts_BCM 0;
BA_ "GenSigTimeoutTime_EPS" SG_ 2654339072 CurrentFailSts_BCM 0;
BA_ "GenSigTimeoutTime_IPC" SG_ 2654339072 CurrentFailSts_BCM 0;
BA_ "GenSigTimeoutTime_MTA" SG_ 2654339072 CurrentFailSts_BCM 0;
BA_ "GenSigTimeoutTime_ORC" SG_ 2654339072 CurrentFailSts_BCM 0;
BA_ "GenSigTimeoutTime_PAM" SG_ 2654339072 CurrentFailSts_BCM 0;
BA_ "GenSigTimeoutTime_BCM" SG_ 2654339072 DES_BCM 0;
BA_ "GenSigTimeoutTime_BSM" SG_ 2654339072 DES_BCM 0;
BA_ "GenSigTimeoutTime_DIAG_TEST" SG_ 2654339072 DES_BCM 0;
BA_ "GenSigTimeoutTime_ECM" SG_ 2654339072 DES_BCM 0;
BA_ "GenSigTimeoutTime_EPS" SG_ 2654339072 DES_BCM 0;
BA_ "GenSigTimeoutTime_IPC" SG_ 2654339072 DES_BCM 0;
BA_ "GenSigTimeoutTime_MTA" SG_ 2654339072 DES_BCM 0;
BA_ "GenSigTimeoutTime_ORC" SG_ 2654339072 DES_BCM 0;
BA_ "GenSigTimeoutTime_PAM" SG_ 2654339072 DES_BCM 0;
BA_ "GenSigTimeoutTime_BCM" SG_ 2654339072 EOL_BCM 0;
BA_ "GenSigTimeoutTime_BSM" SG_ 2654339072 EOL_BCM 0;
BA_ "GenSigTimeoutTime_DIAG_TEST" SG_ 2654339072 EOL_BCM 0;
BA_ "GenSigTimeoutTime_ECM" SG_ 2654339072 EOL_BCM 0;
BA_ "GenSigTimeoutTime_EPS" SG_ 2654339072 EOL_BCM 0;
BA_ "GenSigTimeoutTime_IPC" SG_ 2654339072 EOL_BCM 0;
BA_ "GenSigTimeoutTime_MTA" SG_ 2654339072 EOL_BCM 0;
BA_ "GenSigTimeoutTime_ORC" SG_ 2654339072 EOL_BCM 0;
BA_ "GenSigTimeoutTime_PAM" SG_ 2654339072 EOL_BCM 0;
BA_ "GenSigTimeoutTime_BCM" SG_ 2654339072 GenericFailSts_BCM 0;
BA_ "GenSigTimeoutTime_BSM" SG_ 2654339072 GenericFailSts_BCM 0;
BA_ "GenSigTimeoutTime_DIAG_TEST" SG_ 2654339072 GenericFailSts_BCM 0;
BA_ "GenSigTimeoutTime_ECM" SG_ 2654339072 GenericFailSts_BCM 0;
BA_ "GenSigTimeoutTime_EPS" SG_ 2654339072 GenericFailSts_BCM 0;
BA_ "GenSigTimeoutTime_IPC" SG_ 2654339072 GenericFailSts_BCM 0;
BA_ "GenSigTimeoutTime_MTA" SG_ 2654339072 GenericFailSts_BCM 0;
BA_ "GenSigTimeoutTime_ORC" SG_ 2654339072 GenericFailSts_BCM 0;
BA_ "GenSigTimeoutTime_PAM" SG_ 2654339072 GenericFailSts_BCM 0;
BA_ "GenSigTimeoutTime_BCM" SG_ 2654339072 Reserved_for_PDC_BCM 0;
BA_ "GenSigTimeoutTime_BSM" SG_ 2654339072 Reserved_for_PDC_BCM 0;
BA_ "GenSigTimeoutTime_DIAG_TEST" SG_ 2654339072 Reserved_for_PDC_BCM 0;
BA_ "GenSigTimeoutTime_ECM" SG_ 2654339072 Reserved_for_PDC_BCM 0;
BA_ "GenSigTimeoutTime_EPS" SG_ 2654339072 Reserved_for_PDC_BCM 0;
BA_ "GenSigTimeoutTime_IPC" SG_ 2654339072 Reserved_for_PDC_BCM 0;
BA_ "GenSigTimeoutTime_MTA" SG_ 2654339072 Reserved_for_PDC_BCM 0;
BA_ "GenSigTimeoutTime_ORC" SG_ 2654339072 Reserved_for_PDC_BCM 0;
BA_ "GenSigTimeoutTime_PAM" SG_ 2654339072 Reserved_for_PDC_BCM 0;
BA_ "GenSigTimeoutTime_BCM" SG_ 2654339072 StayActiveSource_BCM_0 0;
BA_ "GenSigTimeoutTime_BSM" SG_ 2654339072 StayActiveSource_BCM_0 0;
BA_ "GenSigTimeoutTime_DIAG_TEST" SG_ 2654339072 StayActiveSource_BCM_0 0;
BA_ "GenSigTimeoutTime_ECM" SG_ 2654339072 StayActiveSource_BCM_0 0;
BA_ "GenSigTimeoutTime_EPS" SG_ 2654339072 StayActiveSource_BCM_0 0;
BA_ "GenSigTimeoutTime_IPC" SG_ 2654339072 StayActiveSource_BCM_0 0;
BA_ "GenSigTimeoutTime_MTA" SG_ 2654339072 StayActiveSource_BCM_0 0;
BA_ "GenSigTimeoutTime_ORC" SG_ 2654339072 StayActiveSource_BCM_0 0;
BA_ "GenSigTimeoutTime_PAM" SG_ 2654339072 StayActiveSource_BCM_0 0;
BA_ "GenSigTimeoutTime_BCM" SG_ 2654339072 StayActiveSource_BCM_1 0;
BA_ "GenSigTimeoutTime_BSM" SG_ 2654339072 StayActiveSource_BCM_1 0;
BA_ "GenSigTimeoutTime_DIAG_TEST" SG_ 2654339072 StayActiveSource_BCM_1 0;
BA_ "GenSigTimeoutTime_ECM" SG_ 2654339072 StayActiveSource_BCM_1 0;
BA_ "GenSigTimeoutTime_EPS" SG_ 2654339072 StayActiveSource_BCM_1 0;
BA_ "GenSigTimeoutTime_IPC" SG_ 2654339072 StayActiveSource_BCM_1 0;
BA_ "GenSigTimeoutTime_MTA" SG_ 2654339072 StayActiveSource_BCM_1 0;
BA_ "GenSigTimeoutTime_ORC" SG_ 2654339072 StayActiveSource_BCM_1 0;
BA_ "GenSigTimeoutTime_PAM" SG_ 2654339072 StayActiveSource_BCM_1 0;
BA_ "GenSigTimeoutTime_BCM" SG_ 2654339072 StayActiveSource_BCM_10 0;
BA_ "GenSigTimeoutTime_BSM" SG_ 2654339072 StayActiveSource_BCM_10 0;
BA_ "GenSigTimeoutTime_DIAG_TEST" SG_ 2654339072 StayActiveSource_BCM_10 0;
BA_ "GenSigTimeoutTime_ECM" SG_ 2654339072 StayActiveSource_BCM_10 0;
BA_ "GenSigTimeoutTime_EPS" SG_ 2654339072 StayActiveSource_BCM_10 0;
BA_ "GenSigTimeoutTime_IPC" SG_ 2654339072 StayActiveSource_BCM_10 0;
BA_ "GenSigTimeoutTime_MTA" SG_ 2654339072 StayActiveSource_BCM_10 0;
BA_ "GenSigTimeoutTime_ORC" SG_ 2654339072 StayActiveSource_BCM_10 0;
BA_ "GenSigTimeoutTime_PAM" SG_ 2654339072 StayActiveSource_BCM_10 0;
BA_ "GenSigTimeoutTime_BCM" SG_ 2654339072 StayActiveSource_BCM_11 0;
BA_ "GenSigTimeoutTime_BSM" SG_ 2654339072 StayActiveSource_BCM_11 0;
BA_ "GenSigTimeoutTime_DIAG_TEST" SG_ 2654339072 StayActiveSource_BCM_11 0;
BA_ "GenSigTimeoutTime_ECM" SG_ 2654339072 StayActiveSource_BCM_11 0;
BA_ "GenSigTimeoutTime_EPS" SG_ 2654339072 StayActiveSource_BCM_11 0;
BA_ "GenSigTimeoutTime_IPC" SG_ 2654339072 StayActiveSource_BCM_11 0;
BA_ "GenSigTimeoutTime_MTA" SG_ 2654339072 StayActiveSource_BCM_11 0;
BA_ "GenSigTimeoutTime_ORC" SG_ 2654339072 StayActiveSource_BCM_11 0;
BA_ "GenSigTimeoutTime_PAM" SG_ 2654339072 StayActiveSource_BCM_11 0;
BA_ "GenSigTimeoutTime_BCM" SG_ 2654339072 StayActiveSource_BCM_12 0;
BA_ "GenSigTimeoutTime_BSM" SG_ 2654339072 StayActiveSource_BCM_12 0;
BA_ "GenSigTimeoutTime_DIAG_TEST" SG_ 2654339072 StayActiveSource_BCM_12 0;
BA_ "GenSigTimeoutTime_ECM" SG_ 2654339072 StayActiveSource_BCM_12 0;
BA_ "GenSigTimeoutTime_EPS" SG_ 2654339072 StayActiveSource_BCM_12 0;
BA_ "GenSigTimeoutTime_IPC" SG_ 2654339072 StayActiveSource_BCM_12 0;
BA_ "GenSigTimeoutTime_MTA" SG_ 2654339072 StayActiveSource_BCM_12 0;
BA_ "GenSigTimeoutTime_ORC" SG_ 2654339072 StayActiveSource_BCM_12 0;
BA_ "GenSigTimeoutTime_PAM" SG_ 2654339072 StayActiveSource_BCM_12 0;
BA_ "GenSigTimeoutTime_BCM" SG_ 2654339072 StayActiveSource_BCM_13 0;
BA_ "GenSigTimeoutTime_BSM" SG_ 2654339072 StayActiveSource_BCM_13 0;
BA_ "GenSigTimeoutTime_DIAG_TEST" SG_ 2654339072 StayActiveSource_BCM_13 0;
BA_ "GenSigTimeoutTime_ECM" SG_ 2654339072 StayActiveSource_BCM_13 0;
BA_ "GenSigTimeoutTime_EPS" SG_ 2654339072 StayActiveSource_BCM_13 0;
BA_ "GenSigTimeoutTime_IPC" SG_ 2654339072 StayActiveSource_BCM_13 0;
BA_ "GenSigTimeoutTime_MTA" SG_ 2654339072 StayActiveSource_BCM_13 0;
BA_ "GenSigTimeoutTime_ORC" SG_ 2654339072 StayActiveSource_BCM_13 0;
BA_ "GenSigTimeoutTime_PAM" SG_ 2654339072 StayActiveSource_BCM_13 0;
BA_ "GenSigTimeoutTime_BCM" SG_ 2654339072 StayActiveSource_BCM_14 0;
BA_ "GenSigTimeoutTime_BSM" SG_ 2654339072 StayActiveSource_BCM_14 0;
BA_ "GenSigTimeoutTime_DIAG_TEST" SG_ 2654339072 StayActiveSource_BCM_14 0;
BA_ "GenSigTimeoutTime_ECM" SG_ 2654339072 StayActiveSource_BCM_14 0;
BA_ "GenSigTimeoutTime_EPS" SG_ 2654339072 StayActiveSource_BCM_14 0;
BA_ "GenSigTimeoutTime_IPC" SG_ 2654339072 StayActiveSource_BCM_14 0;
BA_ "GenSigTimeoutTime_MTA" SG_ 2654339072 StayActiveSource_BCM_14 0;
BA_ "GenSigTimeoutTime_ORC" SG_ 2654339072 StayActiveSource_BCM_14 0;
BA_ "GenSigTimeoutTime_PAM" SG_ 2654339072 StayActiveSource_BCM_14 0;
BA_ "GenSigTimeoutTime_BCM" SG_ 2654339072 StayActiveSource_BCM_15 0;
BA_ "GenSigTimeoutTime_BSM" SG_ 2654339072 StayActiveSource_BCM_15 0;
BA_ "GenSigTimeoutTime_DIAG_TEST" SG_ 2654339072 StayActiveSource_BCM_15 0;
BA_ "GenSigTimeoutTime_ECM" SG_ 2654339072 StayActiveSource_BCM_15 0;
BA_ "GenSigTimeoutTime_EPS" SG_ 2654339072 StayActiveSource_BCM_15 0;
BA_ "GenSigTimeoutTime_IPC" SG_ 2654339072 StayActiveSource_BCM_15 0;
BA_ "GenSigTimeoutTime_MTA" SG_ 2654339072 StayActiveSource_BCM_15 0;
BA_ "GenSigTimeoutTime_ORC" SG_ 2654339072 StayActiveSource_BCM_15 0;
BA_ "GenSigTimeoutTime_PAM" SG_ 2654339072 StayActiveSource_BCM_15 0;
BA_ "GenSigTimeoutTime_BCM" SG_ 2654339072 StayActiveSource_BCM_2 0;
BA_ "GenSigTimeoutTime_BSM" SG_ 2654339072 StayActiveSource_BCM_2 0;
BA_ "GenSigTimeoutTime_DIAG_TEST" SG_ 2654339072 StayActiveSource_BCM_2 0;
BA_ "GenSigTimeoutTime_ECM" SG_ 2654339072 StayActiveSource_BCM_2 0;
BA_ "GenSigTimeoutTime_EPS" SG_ 2654339072 StayActiveSource_BCM_2 0;
BA_ "GenSigTimeoutTime_IPC" SG_ 2654339072 StayActiveSource_BCM_2 0;
BA_ "GenSigTimeoutTime_MTA" SG_ 2654339072 StayActiveSource_BCM_2 0;
BA_ "GenSigTimeoutTime_ORC" SG_ 2654339072 StayActiveSource_BCM_2 0;
BA_ "GenSigTimeoutTime_PAM" SG_ 2654339072 StayActiveSource_BCM_2 0;
BA_ "GenSigTimeoutTime_BCM" SG_ 2654339072 StayActiveSource_BCM_3 0;
BA_ "GenSigTimeoutTime_BSM" SG_ 2654339072 StayActiveSource_BCM_3 0;
BA_ "GenSigTimeoutTime_DIAG_TEST" SG_ 2654339072 StayActiveSource_BCM_3 0;
BA_ "GenSigTimeoutTime_ECM" SG_ 2654339072 StayActiveSource_BCM_3 0;
BA_ "GenSigTimeoutTime_EPS" SG_ 2654339072 StayActiveSource_BCM_3 0;
BA_ "GenSigTimeoutTime_IPC" SG_ 2654339072 StayActiveSource_BCM_3 0;
BA_ "GenSigTimeoutTime_MTA" SG_ 2654339072 StayActiveSource_BCM_3 0;
BA_ "GenSigTimeoutTime_ORC" SG_ 2654339072 StayActiveSource_BCM_3 0;
BA_ "GenSigTimeoutTime_PAM" SG_ 2654339072 StayActiveSource_BCM_3 0;
BA_ "GenSigTimeoutTime_BCM" SG_ 2654339072 StayActiveSource_BCM_4 0;
BA_ "GenSigTimeoutTime_BSM" SG_ 2654339072 StayActiveSource_BCM_4 0;
BA_ "GenSigTimeoutTime_DIAG_TEST" SG_ 2654339072 StayActiveSource_BCM_4 0;
BA_ "GenSigTimeoutTime_ECM" SG_ 2654339072 StayActiveSource_BCM_4 0;
BA_ "GenSigTimeoutTime_EPS" SG_ 2654339072 StayActiveSource_BCM_4 0;
BA_ "GenSigTimeoutTime_IPC" SG_ 2654339072 StayActiveSource_BCM_4 0;
BA_ "GenSigTimeoutTime_MTA" SG_ 2654339072 StayActiveSource_BCM_4 0;
BA_ "GenSigTimeoutTime_ORC" SG_ 2654339072 StayActiveSource_BCM_4 0;
BA_ "GenSigTimeoutTime_PAM" SG_ 2654339072 StayActiveSource_BCM_4 0;
BA_ "GenSigTimeoutTime_BCM" SG_ 2654339072 StayActiveSource_BCM_5 0;
BA_ "GenSigTimeoutTime_BSM" SG_ 2654339072 StayActiveSource_BCM_5 0;
BA_ "GenSigTimeoutTime_DIAG_TEST" SG_ 2654339072 StayActiveSource_BCM_5 0;
BA_ "GenSigTimeoutTime_ECM" SG_ 2654339072 StayActiveSource_BCM_5 0;
BA_ "GenSigTimeoutTime_EPS" SG_ 2654339072 StayActiveSource_BCM_5 0;
BA_ "GenSigTimeoutTime_IPC" SG_ 2654339072 StayActiveSource_BCM_5 0;
BA_ "GenSigTimeoutTime_MTA" SG_ 2654339072 StayActiveSource_BCM_5 0;
BA_ "GenSigTimeoutTime_ORC" SG_ 2654339072 StayActiveSource_BCM_5 0;
BA_ "GenSigTimeoutTime_PAM" SG_ 2654339072 StayActiveSource_BCM_5 0;
BA_ "GenSigTimeoutTime_BCM" SG_ 2654339072 StayActiveSource_BCM_6 0;
BA_ "GenSigTimeoutTime_BSM" SG_ 2654339072 StayActiveSource_BCM_6 0;
BA_ "GenSigTimeoutTime_DIAG_TEST" SG_ 2654339072 StayActiveSource_BCM_6 0;
BA_ "GenSigTimeoutTime_ECM" SG_ 2654339072 StayActiveSource_BCM_6 0;
BA_ "GenSigTimeoutTime_EPS" SG_ 2654339072 StayActiveSource_BCM_6 0;
BA_ "GenSigTimeoutTime_IPC" SG_ 2654339072 StayActiveSource_BCM_6 0;
BA_ "GenSigTimeoutTime_MTA" SG_ 2654339072 StayActiveSource_BCM_6 0;
BA_ "GenSigTimeoutTime_ORC" SG_ 2654339072 StayActiveSource_BCM_6 0;
BA_ "GenSigTimeoutTime_PAM" SG_ 2654339072 StayActiveSource_BCM_6 0;
BA_ "GenSigTimeoutTime_BCM" SG_ 2654339072 StayActiveSource_BCM_7 0;
BA_ "GenSigTimeoutTime_BSM" SG_ 2654339072 StayActiveSource_BCM_7 0;
BA_ "GenSigTimeoutTime_DIAG_TEST" SG_ 2654339072 StayActiveSource_BCM_7 0;
BA_ "GenSigTimeoutTime_ECM" SG_ 2654339072 StayActiveSource_BCM_7 0;
BA_ "GenSigTimeoutTime_EPS" SG_ 2654339072 StayActiveSource_BCM_7 0;
BA_ "GenSigTimeoutTime_IPC" SG_ 2654339072 StayActiveSource_BCM_7 0;
BA_ "GenSigTimeoutTime_MTA" SG_ 2654339072 StayActiveSource_BCM_7 0;
BA_ "GenSigTimeoutTime_ORC" SG_ 2654339072 StayActiveSource_BCM_7 0;
BA_ "GenSigTimeoutTime_PAM" SG_ 2654339072 StayActiveSource_BCM_7 0;
BA_ "GenSigTimeoutTime_BCM" SG_ 2654339072 StayActiveSource_BCM_8 0;
BA_ "GenSigTimeoutTime_BSM" SG_ 2654339072 StayActiveSource_BCM_8 0;
BA_ "GenSigTimeoutTime_DIAG_TEST" SG_ 2654339072 StayActiveSource_BCM_8 0;
BA_ "GenSigTimeoutTime_ECM" SG_ 2654339072 StayActiveSource_BCM_8 0;
BA_ "GenSigTimeoutTime_EPS" SG_ 2654339072 StayActiveSource_BCM_8 0;
BA_ "GenSigTimeoutTime_IPC" SG_ 2654339072 StayActiveSource_BCM_8 0;
BA_ "GenSigTimeoutTime_MTA" SG_ 2654339072 StayActiveSource_BCM_8 0;
BA_ "GenSigTimeoutTime_ORC" SG_ 2654339072 StayActiveSource_BCM_8 0;
BA_ "GenSigTimeoutTime_PAM" SG_ 2654339072 StayActiveSource_BCM_8 0;
BA_ "GenSigTimeoutTime_BCM" SG_ 2654339072 StayActiveSource_BCM_9 0;
BA_ "GenSigTimeoutTime_BSM" SG_ 2654339072 StayActiveSource_BCM_9 0;
BA_ "GenSigTimeoutTime_DIAG_TEST" SG_ 2654339072 StayActiveSource_BCM_9 0;
BA_ "GenSigTimeoutTime_ECM" SG_ 2654339072 StayActiveSource_BCM_9 0;
BA_ "GenSigTimeoutTime_EPS" SG_ 2654339072 StayActiveSource_BCM_9 0;
BA_ "GenSigTimeoutTime_IPC" SG_ 2654339072 StayActiveSource_BCM_9 0;
BA_ "GenSigTimeoutTime_MTA" SG_ 2654339072 StayActiveSource_BCM_9 0;
BA_ "GenSigTimeoutTime_ORC" SG_ 2654339072 StayActiveSource_BCM_9 0;
BA_ "GenSigTimeoutTime_PAM" SG_ 2654339072 StayActiveSource_BCM_9 0;
BA_ "GenSigTimeoutTime_BSM" SG_ 2654339078 CurrentFailSts_BSM 0;
BA_ "GenSigTimeoutTime_DIAG_TEST" SG_ 2654339078 CurrentFailSts_BSM 0;
BA_ "GenSigTimeoutTime_ECM" SG_ 2654339078 CurrentFailSts_BSM 0;
BA_ "GenSigTimeoutTime_EPS" SG_ 2654339078 CurrentFailSts_BSM 0;
BA_ "GenSigTimeoutTime_IPC" SG_ 2654339078 CurrentFailSts_BSM 0;
BA_ "GenSigTimeoutTime_MTA" SG_ 2654339078 CurrentFailSts_BSM 0;
BA_ "GenSigTimeoutTime_ORC" SG_ 2654339078 CurrentFailSts_BSM 0;
BA_ "GenSigTimeoutTime_PAM" SG_ 2654339078 CurrentFailSts_BSM 0;
BA_ "GenSigTimeoutTime_BCM" SG_ 2654339078 DES_BSM 0;
BA_ "GenSigTimeoutTime_BSM" SG_ 2654339078 DES_BSM 0;
BA_ "GenSigTimeoutTime_DIAG_TEST" SG_ 2654339078 DES_BSM 0;
BA_ "GenSigTimeoutTime_ECM" SG_ 2654339078 DES_BSM 0;
BA_ "GenSigTimeoutTime_EPS" SG_ 2654339078 DES_BSM 0;
BA_ "GenSigTimeoutTime_IPC" SG_ 2654339078 DES_BSM 0;
BA_ "GenSigTimeoutTime_MTA" SG_ 2654339078 DES_BSM 0;
BA_ "GenSigTimeoutTime_ORC" SG_ 2654339078 DES_BSM 0;
BA_ "GenSigTimeoutTime_PAM" SG_ 2654339078 DES_BSM 0;
BA_ "GenSigTimeoutTime_BSM" SG_ 2654339078 EOL_BSM 0;
BA_ "GenSigTimeoutTime_DIAG_TEST" SG_ 2654339078 EOL_BSM 0;
BA_ "GenSigTimeoutTime_ECM" SG_ 2654339078 EOL_BSM 0;
BA_ "GenSigTimeoutTime_EPS" SG_ 2654339078 EOL_BSM 0;
BA_ "GenSigTimeoutTime_IPC" SG_ 2654339078 EOL_BSM 0;
BA_ "GenSigTimeoutTime_MTA" SG_ 2654339078 EOL_BSM 0;
BA_ "GenSigTimeoutTime_ORC" SG_ 2654339078 EOL_BSM 0;
BA_ "GenSigTimeoutTime_PAM" SG_ 2654339078 EOL_BSM 0;
BA_ "GenSigTimeoutTime_BSM" SG_ 2654339078 GenericFailSts_BSM 0;
BA_ "GenSigTimeoutTime_DIAG_TEST" SG_ 2654339078 GenericFailSts_BSM 0;
BA_ "GenSigTimeoutTime_ECM" SG_ 2654339078 GenericFailSts_BSM 0;
BA_ "GenSigTimeoutTime_EPS" SG_ 2654339078 GenericFailSts_BSM 0;
BA_ "GenSigTimeoutTime_IPC" SG_ 2654339078 GenericFailSts_BSM 0;
BA_ "GenSigTimeoutTime_MTA" SG_ 2654339078 GenericFailSts_BSM 0;
BA_ "GenSigTimeoutTime_ORC" SG_ 2654339078 GenericFailSts_BSM 0;
BA_ "GenSigTimeoutTime_PAM" SG_ 2654339078 GenericFailSts_BSM 0;
BA_ "GenSigTimeoutTime_BCM" SG_ 2654339078 Reserved_for_PDC_BSM 0;
BA_ "GenSigTimeoutTime_BSM" SG_ 2654339078 Reserved_for_PDC_BSM 0;
BA_ "GenSigTimeoutTime_DIAG_TEST" SG_ 2654339078 Reserved_for_PDC_BSM 0;
BA_ "GenSigTimeoutTime_ECM" SG_ 2654339078 Reserved_for_PDC_BSM 0;
BA_ "GenSigTimeoutTime_EPS" SG_ 2654339078 Reserved_for_PDC_BSM 0;
BA_ "GenSigTimeoutTime_IPC" SG_ 2654339078 Reserved_for_PDC_BSM 0;
BA_ "GenSigTimeoutTime_MTA" SG_ 2654339078 Reserved_for_PDC_BSM 0;
BA_ "GenSigTimeoutTime_ORC" SG_ 2654339078 Reserved_for_PDC_BSM 0;
BA_ "GenSigTimeoutTime_PAM" SG_ 2654339078 Reserved_for_PDC_BSM 0;
BA_ "GenSigTimeoutTime_BCM" SG_ 2654339078 StayActiveSource_BSM_0 0;
BA_ "GenSigTimeoutTime_BSM" SG_ 2654339078 StayActiveSource_BSM_0 0;
BA_ "GenSigTimeoutTime_DIAG_TEST" SG_ 2654339078 StayActiveSource_BSM_0 0;
BA_ "GenSigTimeoutTime_ECM" SG_ 2654339078 StayActiveSource_BSM_0 0;
BA_ "GenSigTimeoutTime_EPS" SG_ 2654339078 StayActiveSource_BSM_0 0;
BA_ "GenSigTimeoutTime_IPC" SG_ 2654339078 StayActiveSource_BSM_0 0;
BA_ "GenSigTimeoutTime_MTA" SG_ 2654339078 StayActiveSource_BSM_0 0;
BA_ "GenSigTimeoutTime_ORC" SG_ 2654339078 StayActiveSource_BSM_0 0;
BA_ "GenSigTimeoutTime_PAM" SG_ 2654339078 StayActiveSource_BSM_0 0;
BA_ "GenSigTimeoutTime_BCM" SG_ 2654339078 StayActiveSource_BSM_1 0;
BA_ "GenSigTimeoutTime_BSM" SG_ 2654339078 StayActiveSource_BSM_1 0;
BA_ "GenSigTimeoutTime_DIAG_TEST" SG_ 2654339078 StayActiveSource_BSM_1 0;
BA_ "GenSigTimeoutTime_ECM" SG_ 2654339078 StayActiveSource_BSM_1 0;
BA_ "GenSigTimeoutTime_EPS" SG_ 2654339078 StayActiveSource_BSM_1 0;
BA_ "GenSigTimeoutTime_IPC" SG_ 2654339078 StayActiveSource_BSM_1 0;
BA_ "GenSigTimeoutTime_MTA" SG_ 2654339078 StayActiveSource_BSM_1 0;
BA_ "GenSigTimeoutTime_ORC" SG_ 2654339078 StayActiveSource_BSM_1 0;
BA_ "GenSigTimeoutTime_PAM" SG_ 2654339078 StayActiveSource_BSM_1 0;
BA_ "GenSigTimeoutTime_BCM" SG_ 2654339078 StayActiveSource_BSM_10 0;
BA_ "GenSigTimeoutTime_BSM" SG_ 2654339078 StayActiveSource_BSM_10 0;
BA_ "GenSigTimeoutTime_DIAG_TEST" SG_ 2654339078 StayActiveSource_BSM_10 0;
BA_ "GenSigTimeoutTime_ECM" SG_ 2654339078 StayActiveSource_BSM_10 0;
BA_ "GenSigTimeoutTime_EPS" SG_ 2654339078 StayActiveSource_BSM_10 0;
BA_ "GenSigTimeoutTime_IPC" SG_ 2654339078 StayActiveSource_BSM_10 0;
BA_ "GenSigTimeoutTime_MTA" SG_ 2654339078 StayActiveSource_BSM_10 0;
BA_ "GenSigTimeoutTime_ORC" SG_ 2654339078 StayActiveSource_BSM_10 0;
BA_ "GenSigTimeoutTime_PAM" SG_ 2654339078 StayActiveSource_BSM_10 0;
BA_ "GenSigTimeoutTime_BCM" SG_ 2654339078 StayActiveSource_BSM_11 0;
BA_ "GenSigTimeoutTime_BSM" SG_ 2654339078 StayActiveSource_BSM_11 0;
BA_ "GenSigTimeoutTime_DIAG_TEST" SG_ 2654339078 StayActiveSource_BSM_11 0;
BA_ "GenSigTimeoutTime_ECM" SG_ 2654339078 StayActiveSource_BSM_11 0;
BA_ "GenSigTimeoutTime_EPS" SG_ 2654339078 StayActiveSource_BSM_11 0;
BA_ "GenSigTimeoutTime_IPC" SG_ 2654339078 StayActiveSource_BSM_11 0;
BA_ "GenSigTimeoutTime_MTA" SG_ 2654339078 StayActiveSource_BSM_11 0;
BA_ "GenSigTimeoutTime_ORC" SG_ 2654339078 StayActiveSource_BSM_11 0;
BA_ "GenSigTimeoutTime_PAM" SG_ 2654339078 StayActiveSource_BSM_11 0;
BA_ "GenSigTimeoutTime_BCM" SG_ 2654339078 StayActiveSource_BSM_12 0;
BA_ "GenSigTimeoutTime_BSM" SG_ 2654339078 StayActiveSource_BSM_12 0;
BA_ "GenSigTimeoutTime_DIAG_TEST" SG_ 2654339078 StayActiveSource_BSM_12 0;
BA_ "GenSigTimeoutTime_ECM" SG_ 2654339078 StayActiveSource_BSM_12 0;
BA_ "GenSigTimeoutTime_EPS" SG_ 2654339078 StayActiveSource_BSM_12 0;
BA_ "GenSigTimeoutTime_IPC" SG_ 2654339078 StayActiveSource_BSM_12 0;
BA_ "GenSigTimeoutTime_MTA" SG_ 2654339078 StayActiveSource_BSM_12 0;
BA_ "GenSigTimeoutTime_ORC" SG_ 2654339078 StayActiveSource_BSM_12 0;
BA_ "GenSigTimeoutTime_PAM" SG_ 2654339078 StayActiveSource_BSM_12 0;
BA_ "GenSigTimeoutTime_BCM" SG_ 2654339078 StayActiveSource_BSM_13 0;
BA_ "GenSigTimeoutTime_BSM" SG_ 2654339078 StayActiveSource_BSM_13 0;
BA_ "GenSigTimeoutTime_DIAG_TEST" SG_ 2654339078 StayActiveSource_BSM_13 0;
BA_ "GenSigTimeoutTime_ECM" SG_ 2654339078 StayActiveSource_BSM_13 0;
BA_ "GenSigTimeoutTime_EPS" SG_ 2654339078 StayActiveSource_BSM_13 0;
BA_ "GenSigTimeoutTime_IPC" SG_ 2654339078 StayActiveSource_BSM_13 0;
BA_ "GenSigTimeoutTime_MTA" SG_ 2654339078 StayActiveSource_BSM_13 0;
BA_ "GenSigTimeoutTime_ORC" SG_ 2654339078 StayActiveSource_BSM_13 0;
BA_ "GenSigTimeoutTime_PAM" SG_ 2654339078 StayActiveSource_BSM_13 0;
BA_ "GenSigTimeoutTime_BCM" SG_ 2654339078 StayActiveSource_BSM_14 0;
BA_ "GenSigTimeoutTime_BSM" SG_ 2654339078 StayActiveSource_BSM_14 0;
BA_ "GenSigTimeoutTime_DIAG_TEST" SG_ 2654339078 StayActiveSource_BSM_14 0;
BA_ "GenSigTimeoutTime_ECM" SG_ 2654339078 StayActiveSource_BSM_14 0;
BA_ "GenSigTimeoutTime_EPS" SG_ 2654339078 StayActiveSource_BSM_14 0;
BA_ "GenSigTimeoutTime_IPC" SG_ 2654339078 StayActiveSource_BSM_14 0;
BA_ "GenSigTimeoutTime_MTA" SG_ 2654339078 StayActiveSource_BSM_14 0;
BA_ "GenSigTimeoutTime_ORC" SG_ 2654339078 StayActiveSource_BSM_14 0;
BA_ "GenSigTimeoutTime_PAM" SG_ 2654339078 StayActiveSource_BSM_14 0;
BA_ "GenSigTimeoutTime_BCM" SG_ 2654339078 StayActiveSource_BSM_15 0;
BA_ "GenSigTimeoutTime_BSM" SG_ 2654339078 StayActiveSource_BSM_15 0;
BA_ "GenSigTimeoutTime_DIAG_TEST" SG_ 2654339078 StayActiveSource_BSM_15 0;
BA_ "GenSigTimeoutTime_ECM" SG_ 2654339078 StayActiveSource_BSM_15 0;
BA_ "GenSigTimeoutTime_EPS" SG_ 2654339078 StayActiveSource_BSM_15 0;
BA_ "GenSigTimeoutTime_IPC" SG_ 2654339078 StayActiveSource_BSM_15 0;
BA_ "GenSigTimeoutTime_MTA" SG_ 2654339078 StayActiveSource_BSM_15 0;
BA_ "GenSigTimeoutTime_ORC" SG_ 2654339078 StayActiveSource_BSM_15 0;
BA_ "GenSigTimeoutTime_PAM" SG_ 2654339078 StayActiveSource_BSM_15 0;
BA_ "GenSigTimeoutTime_BCM" SG_ 2654339078 StayActiveSource_BSM_2 0;
BA_ "GenSigTimeoutTime_BSM" SG_ 2654339078 StayActiveSource_BSM_2 0;
BA_ "GenSigTimeoutTime_DIAG_TEST" SG_ 2654339078 StayActiveSource_BSM_2 0;
BA_ "GenSigTimeoutTime_ECM" SG_ 2654339078 StayActiveSource_BSM_2 0;
BA_ "GenSigTimeoutTime_EPS" SG_ 2654339078 StayActiveSource_BSM_2 0;
BA_ "GenSigTimeoutTime_IPC" SG_ 2654339078 StayActiveSource_BSM_2 0;
BA_ "GenSigTimeoutTime_MTA" SG_ 2654339078 StayActiveSource_BSM_2 0;
BA_ "GenSigTimeoutTime_ORC" SG_ 2654339078 StayActiveSource_BSM_2 0;
BA_ "GenSigTimeoutTime_PAM" SG_ 2654339078 StayActiveSource_BSM_2 0;
BA_ "GenSigTimeoutTime_BCM" SG_ 2654339078 StayActiveSource_BSM_3 0;
BA_ "GenSigTimeoutTime_BSM" SG_ 2654339078 StayActiveSource_BSM_3 0;
BA_ "GenSigTimeoutTime_DIAG_TEST" SG_ 2654339078 StayActiveSource_BSM_3 0;
BA_ "GenSigTimeoutTime_ECM" SG_ 2654339078 StayActiveSource_BSM_3 0;
BA_ "GenSigTimeoutTime_EPS" SG_ 2654339078 StayActiveSource_BSM_3 0;
BA_ "GenSigTimeoutTime_IPC" SG_ 2654339078 StayActiveSource_BSM_3 0;
BA_ "GenSigTimeoutTime_MTA" SG_ 2654339078 StayActiveSource_BSM_3 0;
BA_ "GenSigTimeoutTime_ORC" SG_ 2654339078 StayActiveSource_BSM_3 0;
BA_ "GenSigTimeoutTime_PAM" SG_ 2654339078 StayActiveSource_BSM_3 0;
BA_ "GenSigTimeoutTime_BCM" SG_ 2654339078 StayActiveSource_BSM_4 0;
BA_ "GenSigTimeoutTime_BSM" SG_ 2654339078 StayActiveSource_BSM_4 0;
BA_ "GenSigTimeoutTime_DIAG_TEST" SG_ 2654339078 StayActiveSource_BSM_4 0;
BA_ "GenSigTimeoutTime_ECM" SG_ 2654339078 StayActiveSource_BSM_4 0;
BA_ "GenSigTimeoutTime_EPS" SG_ 2654339078 StayActiveSource_BSM_4 0;
BA_ "GenSigTimeoutTime_IPC" SG_ 2654339078 StayActiveSource_BSM_4 0;
BA_ "GenSigTimeoutTime_MTA" SG_ 2654339078 StayActiveSource_BSM_4 0;
BA_ "GenSigTimeoutTime_ORC" SG_ 2654339078 StayActiveSource_BSM_4 0;
BA_ "GenSigTimeoutTime_PAM" SG_ 2654339078 StayActiveSource_BSM_4 0;
BA_ "GenSigTimeoutTime_BCM" SG_ 2654339078 StayActiveSource_BSM_5 0;
BA_ "GenSigTimeoutTime_BSM" SG_ 2654339078 StayActiveSource_BSM_5 0;
BA_ "GenSigTimeoutTime_DIAG_TEST" SG_ 2654339078 StayActiveSource_BSM_5 0;
BA_ "GenSigTimeoutTime_ECM" SG_ 2654339078 StayActiveSource_BSM_5 0;
BA_ "GenSigTimeoutTime_EPS" SG_ 2654339078 StayActiveSource_BSM_5 0;
BA_ "GenSigTimeoutTime_IPC" SG_ 2654339078 StayActiveSource_BSM_5 0;
BA_ "GenSigTimeoutTime_MTA" SG_ 2654339078 StayActiveSource_BSM_5 0;
BA_ "GenSigTimeoutTime_ORC" SG_ 2654339078 StayActiveSource_BSM_5 0;
BA_ "GenSigTimeoutTime_PAM" SG_ 2654339078 StayActiveSource_BSM_5 0;
BA_ "GenSigTimeoutTime_BCM" SG_ 2654339078 StayActiveSource_BSM_6 0;
BA_ "GenSigTimeoutTime_BSM" SG_ 2654339078 StayActiveSource_BSM_6 0;
BA_ "GenSigTimeoutTime_DIAG_TEST" SG_ 2654339078 StayActiveSource_BSM_6 0;
BA_ "GenSigTimeoutTime_ECM" SG_ 2654339078 StayActiveSource_BSM_6 0;
BA_ "GenSigTimeoutTime_EPS" SG_ 2654339078 StayActiveSource_BSM_6 0;
BA_ "GenSigTimeoutTime_IPC" SG_ 2654339078 StayActiveSource_BSM_6 0;
BA_ "GenSigTimeoutTime_MTA" SG_ 2654339078 StayActiveSource_BSM_6 0;
BA_ "GenSigTimeoutTime_ORC" SG_ 2654339078 StayActiveSource_BSM_6 0;
BA_ "GenSigTimeoutTime_PAM" SG_ 2654339078 StayActiveSource_BSM_6 0;
BA_ "GenSigTimeoutTime_BCM" SG_ 2654339078 StayActiveSource_BSM_7 0;
BA_ "GenSigTimeoutTime_BSM" SG_ 2654339078 StayActiveSource_BSM_7 0;
BA_ "GenSigTimeoutTime_DIAG_TEST" SG_ 2654339078 StayActiveSource_BSM_7 0;
BA_ "GenSigTimeoutTime_ECM" SG_ 2654339078 StayActiveSource_BSM_7 0;
BA_ "GenSigTimeoutTime_EPS" SG_ 2654339078 StayActiveSource_BSM_7 0;
BA_ "GenSigTimeoutTime_IPC" SG_ 2654339078 StayActiveSource_BSM_7 0;
BA_ "GenSigTimeoutTime_MTA" SG_ 2654339078 StayActiveSource_BSM_7 0;
BA_ "GenSigTimeoutTime_ORC" SG_ 2654339078 StayActiveSource_BSM_7 0;
BA_ "GenSigTimeoutTime_PAM" SG_ 2654339078 StayActiveSource_BSM_7 0;
BA_ "GenSigTimeoutTime_BCM" SG_ 2654339078 StayActiveSource_BSM_8 0;
BA_ "GenSigTimeoutTime_BSM" SG_ 2654339078 StayActiveSource_BSM_8 0;
BA_ "GenSigTimeoutTime_DIAG_TEST" SG_ 2654339078 StayActiveSource_BSM_8 0;
BA_ "GenSigTimeoutTime_ECM" SG_ 2654339078 StayActiveSource_BSM_8 0;
BA_ "GenSigTimeoutTime_EPS" SG_ 2654339078 StayActiveSource_BSM_8 0;
BA_ "GenSigTimeoutTime_IPC" SG_ 2654339078 StayActiveSource_BSM_8 0;
BA_ "GenSigTimeoutTime_MTA" SG_ 2654339078 StayActiveSource_BSM_8 0;
BA_ "GenSigTimeoutTime_ORC" SG_ 2654339078 StayActiveSource_BSM_8 0;
BA_ "GenSigTimeoutTime_PAM" SG_ 2654339078 StayActiveSource_BSM_8 0;
BA_ "GenSigTimeoutTime_BCM" SG_ 2654339078 StayActiveSource_BSM_9 0;
BA_ "GenSigTimeoutTime_BSM" SG_ 2654339078 StayActiveSource_BSM_9 0;
BA_ "GenSigTimeoutTime_DIAG_TEST" SG_ 2654339078 StayActiveSource_BSM_9 0;
BA_ "GenSigTimeoutTime_ECM" SG_ 2654339078 StayActiveSource_BSM_9 0;
BA_ "GenSigTimeoutTime_EPS" SG_ 2654339078 StayActiveSource_BSM_9 0;
BA_ "GenSigTimeoutTime_IPC" SG_ 2654339078 StayActiveSource_BSM_9 0;
BA_ "GenSigTimeoutTime_MTA" SG_ 2654339078 StayActiveSource_BSM_9 0;
BA_ "GenSigTimeoutTime_ORC" SG_ 2654339078 StayActiveSource_BSM_9 0;
BA_ "GenSigTimeoutTime_PAM" SG_ 2654339078 StayActiveSource_BSM_9 0;
BA_ "GenSigTimeoutTime_BSM" SG_ 2654339073 CurrentFailSts_ECM 0;
BA_ "GenSigTimeoutTime_DIAG_TEST" SG_ 2654339073 CurrentFailSts_ECM 0;
BA_ "GenSigTimeoutTime_ECM" SG_ 2654339073 CurrentFailSts_ECM 0;
BA_ "GenSigTimeoutTime_EPS" SG_ 2654339073 CurrentFailSts_ECM 0;
BA_ "GenSigTimeoutTime_IPC" SG_ 2654339073 CurrentFailSts_ECM 0;
BA_ "GenSigTimeoutTime_MTA" SG_ 2654339073 CurrentFailSts_ECM 0;
BA_ "GenSigTimeoutTime_ORC" SG_ 2654339073 CurrentFailSts_ECM 0;
BA_ "GenSigTimeoutTime_PAM" SG_ 2654339073 CurrentFailSts_ECM 0;
BA_ "GenSigTimeoutTime_BCM" SG_ 2654339073 DES_ECM 0;
BA_ "GenSigTimeoutTime_BSM" SG_ 2654339073 DES_ECM 0;
BA_ "GenSigTimeoutTime_DIAG_TEST" SG_ 2654339073 DES_ECM 0;
BA_ "GenSigTimeoutTime_ECM" SG_ 2654339073 DES_ECM 0;
BA_ "GenSigTimeoutTime_EPS" SG_ 2654339073 DES_ECM 0;
BA_ "GenSigTimeoutTime_IPC" SG_ 2654339073 DES_ECM 0;
BA_ "GenSigTimeoutTime_MTA" SG_ 2654339073 DES_ECM 0;
BA_ "GenSigTimeoutTime_ORC" SG_ 2654339073 DES_ECM 0;
BA_ "GenSigTimeoutTime_PAM" SG_ 2654339073 DES_ECM 0;
BA_ "GenSigTimeoutTime_BSM" SG_ 2654339073 EOL_ECM 0;
BA_ "GenSigTimeoutTime_DIAG_TEST" SG_ 2654339073 EOL_ECM 0;
BA_ "GenSigTimeoutTime_ECM" SG_ 2654339073 EOL_ECM 0;
BA_ "GenSigTimeoutTime_EPS" SG_ 2654339073 EOL_ECM 0;
BA_ "GenSigTimeoutTime_IPC" SG_ 2654339073 EOL_ECM 0;
BA_ "GenSigTimeoutTime_MTA" SG_ 2654339073 EOL_ECM 0;
BA_ "GenSigTimeoutTime_ORC" SG_ 2654339073 EOL_ECM 0;
BA_ "GenSigTimeoutTime_PAM" SG_ 2654339073 EOL_ECM 0;
BA_ "GenSigTimeoutTime_BSM" SG_ 2654339073 GenericFailSts_ECM 0;
BA_ "GenSigTimeoutTime_DIAG_TEST" SG_ 2654339073 GenericFailSts_ECM 0;
BA_ "GenSigTimeoutTime_ECM" SG_ 2654339073 GenericFailSts_ECM 0;
BA_ "GenSigTimeoutTime_EPS" SG_ 2654339073 GenericFailSts_ECM 0;
BA_ "GenSigTimeoutTime_IPC" SG_ 2654339073 GenericFailSts_ECM 0;
BA_ "GenSigTimeoutTime_MTA" SG_ 2654339073 GenericFailSts_ECM 0;
BA_ "GenSigTimeoutTime_ORC" SG_ 2654339073 GenericFailSts_ECM 0;
BA_ "GenSigTimeoutTime_PAM" SG_ 2654339073 GenericFailSts_ECM 0;
BA_ "GenSigTimeoutTime_BCM" SG_ 2654339073 Reserved_for_PDC_ECM 0;
BA_ "GenSigTimeoutTime_BSM" SG_ 2654339073 Reserved_for_PDC_ECM 0;
BA_ "GenSigTimeoutTime_DIAG_TEST" SG_ 2654339073 Reserved_for_PDC_ECM 0;
BA_ "GenSigTimeoutTime_ECM" SG_ 2654339073 Reserved_for_PDC_ECM 0;
BA_ "GenSigTimeoutTime_EPS" SG_ 2654339073 Reserved_for_PDC_ECM 0;
BA_ "GenSigTimeoutTime_IPC" SG_ 2654339073 Reserved_for_PDC_ECM 0;
BA_ "GenSigTimeoutTime_MTA" SG_ 2654339073 Reserved_for_PDC_ECM 0;
BA_ "GenSigTimeoutTime_ORC" SG_ 2654339073 Reserved_for_PDC_ECM 0;
BA_ "GenSigTimeoutTime_PAM" SG_ 2654339073 Reserved_for_PDC_ECM 0;
BA_ "GenSigTimeoutTime_BCM" SG_ 2654339073 StayActiveSource_ECM_0 0;
BA_ "GenSigTimeoutTime_BSM" SG_ 2654339073 StayActiveSource_ECM_0 0;
BA_ "GenSigTimeoutTime_DIAG_TEST" SG_ 2654339073 StayActiveSource_ECM_0 0;
BA_ "GenSigTimeoutTime_ECM" SG_ 2654339073 StayActiveSource_ECM_0 0;
BA_ "GenSigTimeoutTime_EPS" SG_ 2654339073 StayActiveSource_ECM_0 0;
BA_ "GenSigTimeoutTime_IPC" SG_ 2654339073 StayActiveSource_ECM_0 0;
BA_ "GenSigTimeoutTime_MTA" SG_ 2654339073 StayActiveSource_ECM_0 0;
BA_ "GenSigTimeoutTime_ORC" SG_ 2654339073 StayActiveSource_ECM_0 0;
BA_ "GenSigTimeoutTime_PAM" SG_ 2654339073 StayActiveSource_ECM_0 0;
BA_ "GenSigTimeoutTime_BCM" SG_ 2654339073 StayActiveSource_ECM_1 0;
BA_ "GenSigTimeoutTime_BSM" SG_ 2654339073 StayActiveSource_ECM_1 0;
BA_ "GenSigTimeoutTime_DIAG_TEST" SG_ 2654339073 StayActiveSource_ECM_1 0;
BA_ "GenSigTimeoutTime_ECM" SG_ 2654339073 StayActiveSource_ECM_1 0;
BA_ "GenSigTimeoutTime_EPS" SG_ 2654339073 StayActiveSource_ECM_1 0;
BA_ "GenSigTimeoutTime_IPC" SG_ 2654339073 StayActiveSource_ECM_1 0;
BA_ "GenSigTimeoutTime_MTA" SG_ 2654339073 StayActiveSource_ECM_1 0;
BA_ "GenSigTimeoutTime_ORC" SG_ 2654339073 StayActiveSource_ECM_1 0;
BA_ "GenSigTimeoutTime_PAM" SG_ 2654339073 StayActiveSource_ECM_1 0;
BA_ "GenSigTimeoutTime_BCM" SG_ 2654339073 StayActiveSource_ECM_10 0;
BA_ "GenSigTimeoutTime_BSM" SG_ 2654339073 StayActiveSource_ECM_10 0;
BA_ "GenSigTimeoutTime_DIAG_TEST" SG_ 2654339073 StayActiveSource_ECM_10 0;
BA_ "GenSigTimeoutTime_ECM" SG_ 2654339073 StayActiveSource_ECM_10 0;
BA_ "GenSigTimeoutTime_EPS" SG_ 2654339073 StayActiveSource_ECM_10 0;
BA_ "GenSigTimeoutTime_IPC" SG_ 2654339073 StayActiveSource_ECM_10 0;
BA_ "GenSigTimeoutTime_MTA" SG_ 2654339073 StayActiveSource_ECM_10 0;
BA_ "GenSigTimeoutTime_ORC" SG_ 2654339073 StayActiveSource_ECM_10 0;
BA_ "GenSigTimeoutTime_PAM" SG_ 2654339073 StayActiveSource_ECM_10 0;
BA_ "GenSigTimeoutTime_BCM" SG_ 2654339073 StayActiveSource_ECM_11 0;
BA_ "GenSigTimeoutTime_BSM" SG_ 2654339073 StayActiveSource_ECM_11 0;
BA_ "GenSigTimeoutTime_DIAG_TEST" SG_ 2654339073 StayActiveSource_ECM_11 0;
BA_ "GenSigTimeoutTime_ECM" SG_ 2654339073 StayActiveSource_ECM_11 0;
BA_ "GenSigTimeoutTime_EPS" SG_ 2654339073 StayActiveSource_ECM_11 0;
BA_ "GenSigTimeoutTime_IPC" SG_ 2654339073 StayActiveSource_ECM_11 0;
BA_ "GenSigTimeoutTime_MTA" SG_ 2654339073 StayActiveSource_ECM_11 0;
BA_ "GenSigTimeoutTime_ORC" SG_ 2654339073 StayActiveSource_ECM_11 0;
BA_ "GenSigTimeoutTime_PAM" SG_ 2654339073 StayActiveSource_ECM_11 0;
BA_ "GenSigTimeoutTime_BCM" SG_ 2654339073 StayActiveSource_ECM_12 0;
BA_ "GenSigTimeoutTime_BSM" SG_ 2654339073 StayActiveSource_ECM_12 0;
BA_ "GenSigTimeoutTime_DIAG_TEST" SG_ 2654339073 StayActiveSource_ECM_12 0;
BA_ "GenSigTimeoutTime_ECM" SG_ 2654339073 StayActiveSource_ECM_12 0;
BA_ "GenSigTimeoutTime_EPS" SG_ 2654339073 StayActiveSource_ECM_12 0;
BA_ "GenSigTimeoutTime_IPC" SG_ 2654339073 StayActiveSource_ECM_12 0;
BA_ "GenSigTimeoutTime_MTA" SG_ 2654339073 StayActiveSource_ECM_12 0;
BA_ "GenSigTimeoutTime_ORC" SG_ 2654339073 StayActiveSource_ECM_12 0;
BA_ "GenSigTimeoutTime_PAM" SG_ 2654339073 StayActiveSource_ECM_12 0;
BA_ "GenSigTimeoutTime_BCM" SG_ 2654339073 StayActiveSource_ECM_13 0;
BA_ "GenSigTimeoutTime_BSM" SG_ 2654339073 StayActiveSource_ECM_13 0;
BA_ "GenSigTimeoutTime_DIAG_TEST" SG_ 2654339073 StayActiveSource_ECM_13 0;
BA_ "GenSigTimeoutTime_ECM" SG_ 2654339073 StayActiveSource_ECM_13 0;
BA_ "GenSigTimeoutTime_EPS" SG_ 2654339073 StayActiveSource_ECM_13 0;
BA_ "GenSigTimeoutTime_IPC" SG_ 2654339073 StayActiveSource_ECM_13 0;
BA_ "GenSigTimeoutTime_MTA" SG_ 2654339073 StayActiveSource_ECM_13 0;
BA_ "GenSigTimeoutTime_ORC" SG_ 2654339073 StayActiveSource_ECM_13 0;
BA_ "GenSigTimeoutTime_PAM" SG_ 2654339073 StayActiveSource_ECM_13 0;
BA_ "GenSigTimeoutTime_BCM" SG_ 2654339073 StayActiveSource_ECM_14 0;
BA_ "GenSigTimeoutTime_BSM" SG_ 2654339073 StayActiveSource_ECM_14 0;
BA_ "GenSigTimeoutTime_DIAG_TEST" SG_ 2654339073 StayActiveSource_ECM_14 0;
BA_ "GenSigTimeoutTime_ECM" SG_ 2654339073 StayActiveSource_ECM_14 0;
BA_ "GenSigTimeoutTime_EPS" SG_ 2654339073 StayActiveSource_ECM_14 0;
BA_ "GenSigTimeoutTime_IPC" SG_ 2654339073 StayActiveSource_ECM_14 0;
BA_ "GenSigTimeoutTime_MTA" SG_ 2654339073 StayActiveSource_ECM_14 0;
BA_ "GenSigTimeoutTime_ORC" SG_ 2654339073 StayActiveSource_ECM_14 0;
BA_ "GenSigTimeoutTime_PAM" SG_ 2654339073 StayActiveSource_ECM_14 0;
BA_ "GenSigTimeoutTime_BCM" SG_ 2654339073 StayActiveSource_ECM_15 0;
BA_ "GenSigTimeoutTime_BSM" SG_ 2654339073 StayActiveSource_ECM_15 0;
BA_ "GenSigTimeoutTime_DIAG_TEST" SG_ 2654339073 StayActiveSource_ECM_15 0;
BA_ "GenSigTimeoutTime_ECM" SG_ 2654339073 StayActiveSource_ECM_15 0;
BA_ "GenSigTimeoutTime_EPS" SG_ 2654339073 StayActiveSource_ECM_15 0;
BA_ "GenSigTimeoutTime_IPC" SG_ 2654339073 StayActiveSource_ECM_15 0;
BA_ "GenSigTimeoutTime_MTA" SG_ 2654339073 StayActiveSource_ECM_15 0;
BA_ "GenSigTimeoutTime_ORC" SG_ 2654339073 StayActiveSource_ECM_15 0;
BA_ "GenSigTimeoutTime_PAM" SG_ 2654339073 StayActiveSource_ECM_15 0;
BA_ "GenSigTimeoutTime_BCM" SG_ 2654339073 StayActiveSource_ECM_2 0;
BA_ "GenSigTimeoutTime_BSM" SG_ 2654339073 StayActiveSource_ECM_2 0;
BA_ "GenSigTimeoutTime_DIAG_TEST" SG_ 2654339073 StayActiveSource_ECM_2 0;
BA_ "GenSigTimeoutTime_ECM" SG_ 2654339073 StayActiveSource_ECM_2 0;
BA_ "GenSigTimeoutTime_EPS" SG_ 2654339073 StayActiveSource_ECM_2 0;
BA_ "GenSigTimeoutTime_IPC" SG_ 2654339073 StayActiveSource_ECM_2 0;
BA_ "GenSigTimeoutTime_MTA" SG_ 2654339073 StayActiveSource_ECM_2 0;
BA_ "GenSigTimeoutTime_ORC" SG_ 2654339073 StayActiveSource_ECM_2 0;
BA_ "GenSigTimeoutTime_PAM" SG_ 2654339073 StayActiveSource_ECM_2 0;
BA_ "GenSigTimeoutTime_BCM" SG_ 2654339073 StayActiveSource_ECM_3 0;
BA_ "GenSigTimeoutTime_BSM" SG_ 2654339073 StayActiveSource_ECM_3 0;
BA_ "GenSigTimeoutTime_DIAG_TEST" SG_ 2654339073 StayActiveSource_ECM_3 0;
BA_ "GenSigTimeoutTime_ECM" SG_ 2654339073 StayActiveSource_ECM_3 0;
BA_ "GenSigTimeoutTime_EPS" SG_ 2654339073 StayActiveSource_ECM_3 0;
BA_ "GenSigTimeoutTime_IPC" SG_ 2654339073 StayActiveSource_ECM_3 0;
BA_ "GenSigTimeoutTime_MTA" SG_ 2654339073 StayActiveSource_ECM_3 0;
BA_ "GenSigTimeoutTime_ORC" SG_ 2654339073 StayActiveSource_ECM_3 0;
BA_ "GenSigTimeoutTime_PAM" SG_ 2654339073 StayActiveSource_ECM_3 0;
BA_ "GenSigTimeoutTime_BCM" SG_ 2654339073 StayActiveSource_ECM_4 0;
BA_ "GenSigTimeoutTime_BSM" SG_ 2654339073 StayActiveSource_ECM_4 0;
BA_ "GenSigTimeoutTime_DIAG_TEST" SG_ 2654339073 StayActiveSource_ECM_4 0;
BA_ "GenSigTimeoutTime_ECM" SG_ 2654339073 StayActiveSource_ECM_4 0;
BA_ "GenSigTimeoutTime_EPS" SG_ 2654339073 StayActiveSource_ECM_4 0;
BA_ "GenSigTimeoutTime_IPC" SG_ 2654339073 StayActiveSource_ECM_4 0;
BA_ "GenSigTimeoutTime_MTA" SG_ 2654339073 StayActiveSource_ECM_4 0;
BA_ "GenSigTimeoutTime_ORC" SG_ 2654339073 StayActiveSource_ECM_4 0;
BA_ "GenSigTimeoutTime_PAM" SG_ 2654339073 StayActiveSource_ECM_4 0;
BA_ "GenSigTimeoutTime_BCM" SG_ 2654339073 StayActiveSource_ECM_5 0;
BA_ "GenSigTimeoutTime_BSM" SG_ 2654339073 StayActiveSource_ECM_5 0;
BA_ "GenSigTimeoutTime_DIAG_TEST" SG_ 2654339073 StayActiveSource_ECM_5 0;
BA_ "GenSigTimeoutTime_ECM" SG_ 2654339073 StayActiveSource_ECM_5 0;
BA_ "GenSigTimeoutTime_EPS" SG_ 2654339073 StayActiveSource_ECM_5 0;
BA_ "GenSigTimeoutTime_IPC" SG_ 2654339073 StayActiveSource_ECM_5 0;
BA_ "GenSigTimeoutTime_MTA" SG_ 2654339073 StayActiveSource_ECM_5 0;
BA_ "GenSigTimeoutTime_ORC" SG_ 2654339073 StayActiveSource_ECM_5 0;
BA_ "GenSigTimeoutTime_PAM" SG_ 2654339073 StayActiveSource_ECM_5 0;
BA_ "GenSigTimeoutTime_BCM" SG_ 2654339073 StayActiveSource_ECM_6 0;
BA_ "GenSigTimeoutTime_BSM" SG_ 2654339073 StayActiveSource_ECM_6 0;
BA_ "GenSigTimeoutTime_DIAG_TEST" SG_ 2654339073 StayActiveSource_ECM_6 0;
BA_ "GenSigTimeoutTime_ECM" SG_ 2654339073 StayActiveSource_ECM_6 0;
BA_ "GenSigTimeoutTime_EPS" SG_ 2654339073 StayActiveSource_ECM_6 0;
BA_ "GenSigTimeoutTime_IPC" SG_ 2654339073 StayActiveSource_ECM_6 0;
BA_ "GenSigTimeoutTime_MTA" SG_ 2654339073 StayActiveSource_ECM_6 0;
BA_ "GenSigTimeoutTime_ORC" SG_ 2654339073 StayActiveSource_ECM_6 0;
BA_ "GenSigTimeoutTime_PAM" SG_ 2654339073 StayActiveSource_ECM_6 0;
BA_ "GenSigTimeoutTime_BCM" SG_ 2654339073 StayActiveSource_ECM_7 0;
BA_ "GenSigTimeoutTime_BSM" SG_ 2654339073 StayActiveSource_ECM_7 0;
BA_ "GenSigTimeoutTime_DIAG_TEST" SG_ 2654339073 StayActiveSource_ECM_7 0;
BA_ "GenSigTimeoutTime_ECM" SG_ 2654339073 StayActiveSource_ECM_7 0;
BA_ "GenSigTimeoutTime_EPS" SG_ 2654339073 StayActiveSource_ECM_7 0;
BA_ "GenSigTimeoutTime_IPC" SG_ 2654339073 StayActiveSource_ECM_7 0;
BA_ "GenSigTimeoutTime_MTA" SG_ 2654339073 StayActiveSource_ECM_7 0;
BA_ "GenSigTimeoutTime_ORC" SG_ 2654339073 StayActiveSource_ECM_7 0;
BA_ "GenSigTimeoutTime_PAM" SG_ 2654339073 StayActiveSource_ECM_7 0;
BA_ "GenSigTimeoutTime_BCM" SG_ 2654339073 StayActiveSource_ECM_8 0;
BA_ "GenSigTimeoutTime_BSM" SG_ 2654339073 StayActiveSource_ECM_8 0;
BA_ "GenSigTimeoutTime_DIAG_TEST" SG_ 2654339073 StayActiveSource_ECM_8 0;
BA_ "GenSigTimeoutTime_ECM" SG_ 2654339073 StayActiveSource_ECM_8 0;
BA_ "GenSigTimeoutTime_EPS" SG_ 2654339073 StayActiveSource_ECM_8 0;
BA_ "GenSigTimeoutTime_IPC" SG_ 2654339073 StayActiveSource_ECM_8 0;
BA_ "GenSigTimeoutTime_MTA" SG_ 2654339073 StayActiveSource_ECM_8 0;
BA_ "GenSigTimeoutTime_ORC" SG_ 2654339073 StayActiveSource_ECM_8 0;
BA_ "GenSigTimeoutTime_PAM" SG_ 2654339073 StayActiveSource_ECM_8 0;
BA_ "GenSigTimeoutTime_BCM" SG_ 2654339073 StayActiveSource_ECM_9 0;
BA_ "GenSigTimeoutTime_BSM" SG_ 2654339073 StayActiveSource_ECM_9 0;
BA_ "GenSigTimeoutTime_DIAG_TEST" SG_ 2654339073 StayActiveSource_ECM_9 0;
BA_ "GenSigTimeoutTime_ECM" SG_ 2654339073 StayActiveSource_ECM_9 0;
BA_ "GenSigTimeoutTime_EPS" SG_ 2654339073 StayActiveSource_ECM_9 0;
BA_ "GenSigTimeoutTime_IPC" SG_ 2654339073 StayActiveSource_ECM_9 0;
BA_ "GenSigTimeoutTime_MTA" SG_ 2654339073 StayActiveSource_ECM_9 0;
BA_ "GenSigTimeoutTime_ORC" SG_ 2654339073 StayActiveSource_ECM_9 0;
BA_ "GenSigTimeoutTime_PAM" SG_ 2654339073 StayActiveSource_ECM_9 0;
BA_ "GenSigTimeoutTime_BSM" SG_ 2654339074 CurrentFailSts_EPS 0;
BA_ "GenSigTimeoutTime_DIAG_TEST" SG_ 2654339074 CurrentFailSts_EPS 0;
BA_ "GenSigTimeoutTime_ECM" SG_ 2654339074 CurrentFailSts_EPS 0;
BA_ "GenSigTimeoutTime_EPS" SG_ 2654339074 CurrentFailSts_EPS 0;
BA_ "GenSigTimeoutTime_IPC" SG_ 2654339074 CurrentFailSts_EPS 0;
BA_ "GenSigTimeoutTime_MTA" SG_ 2654339074 CurrentFailSts_EPS 0;
BA_ "GenSigTimeoutTime_ORC" SG_ 2654339074 CurrentFailSts_EPS 0;
BA_ "GenSigTimeoutTime_PAM" SG_ 2654339074 CurrentFailSts_EPS 0;
BA_ "GenSigTimeoutTime_BCM" SG_ 2654339074 DES_EPS 0;
BA_ "GenSigTimeoutTime_BSM" SG_ 2654339074 DES_EPS 0;
BA_ "GenSigTimeoutTime_DIAG_TEST" SG_ 2654339074 DES_EPS 0;
BA_ "GenSigTimeoutTime_ECM" SG_ 2654339074 DES_EPS 0;
BA_ "GenSigTimeoutTime_EPS" SG_ 2654339074 DES_EPS 0;
BA_ "GenSigTimeoutTime_IPC" SG_ 2654339074 DES_EPS 0;
BA_ "GenSigTimeoutTime_MTA" SG_ 2654339074 DES_EPS 0;
BA_ "GenSigTimeoutTime_ORC" SG_ 2654339074 DES_EPS 0;
BA_ "GenSigTimeoutTime_PAM" SG_ 2654339074 DES_EPS 0;
BA_ "GenSigTimeoutTime_BSM" SG_ 2654339074 EOL_EPS 0;
BA_ "GenSigTimeoutTime_DIAG_TEST" SG_ 2654339074 EOL_EPS 0;
BA_ "GenSigTimeoutTime_ECM" SG_ 2654339074 EOL_EPS 0;
BA_ "GenSigTimeoutTime_EPS" SG_ 2654339074 EOL_EPS 0;
BA_ "GenSigTimeoutTime_IPC" SG_ 2654339074 EOL_EPS 0;
BA_ "GenSigTimeoutTime_MTA" SG_ 2654339074 EOL_EPS 0;
BA_ "GenSigTimeoutTime_ORC" SG_ 2654339074 EOL_EPS 0;
BA_ "GenSigTimeoutTime_PAM" SG_ 2654339074 EOL_EPS 0;
BA_ "GenSigTimeoutTime_BSM" SG_ 2654339074 GenericFailSts_EPS 0;
BA_ "GenSigTimeoutTime_DIAG_TEST" SG_ 2654339074 GenericFailSts_EPS 0;
BA_ "GenSigTimeoutTime_ECM" SG_ 2654339074 GenericFailSts_EPS 0;
BA_ "GenSigTimeoutTime_EPS" SG_ 2654339074 GenericFailSts_EPS 0;
BA_ "GenSigTimeoutTime_IPC" SG_ 2654339074 GenericFailSts_EPS 0;
BA_ "GenSigTimeoutTime_MTA" SG_ 2654339074 GenericFailSts_EPS 0;
BA_ "GenSigTimeoutTime_ORC" SG_ 2654339074 GenericFailSts_EPS 0;
BA_ "GenSigTimeoutTime_PAM" SG_ 2654339074 GenericFailSts_EPS 0;
BA_ "GenSigTimeoutTime_BCM" SG_ 2654339074 Reserved_for_PDC_EPS 0;
BA_ "GenSigTimeoutTime_BSM" SG_ 2654339074 Reserved_for_PDC_EPS 0;
BA_ "GenSigTimeoutTime_DIAG_TEST" SG_ 2654339074 Reserved_for_PDC_EPS 0;
BA_ "GenSigTimeoutTime_ECM" SG_ 2654339074 Reserved_for_PDC_EPS 0;
BA_ "GenSigTimeoutTime_EPS" SG_ 2654339074 Reserved_for_PDC_EPS 0;
BA_ "GenSigTimeoutTime_IPC" SG_ 2654339074 Reserved_for_PDC_EPS 0;
BA_ "GenSigTimeoutTime_MTA" SG_ 2654339074 Reserved_for_PDC_EPS 0;
BA_ "GenSigTimeoutTime_ORC" SG_ 2654339074 Reserved_for_PDC_EPS 0;
BA_ "GenSigTimeoutTime_PAM" SG_ 2654339074 Reserved_for_PDC_EPS 0;
BA_ "GenSigTimeoutTime_BCM" SG_ 2654339074 StayActiveSource_EPS_0 0;
BA_ "GenSigTimeoutTime_BSM" SG_ 2654339074 StayActiveSource_EPS_0 0;
BA_ "GenSigTimeoutTime_DIAG_TEST" SG_ 2654339074 StayActiveSource_EPS_0 0;
BA_ "GenSigTimeoutTime_ECM" SG_ 2654339074 StayActiveSource_EPS_0 0;
BA_ "GenSigTimeoutTime_EPS" SG_ 2654339074 StayActiveSource_EPS_0 0;
BA_ "GenSigTimeoutTime_IPC" SG_ 2654339074 StayActiveSource_EPS_0 0;
BA_ "GenSigTimeoutTime_MTA" SG_ 2654339074 StayActiveSource_EPS_0 0;
BA_ "GenSigTimeoutTime_ORC" SG_ 2654339074 StayActiveSource_EPS_0 0;
BA_ "GenSigTimeoutTime_PAM" SG_ 2654339074 StayActiveSource_EPS_0 0;
BA_ "GenSigTimeoutTime_BCM" SG_ 2654339074 StayActiveSource_EPS_1 0;
BA_ "GenSigTimeoutTime_BSM" SG_ 2654339074 StayActiveSource_EPS_1 0;
BA_ "GenSigTimeoutTime_DIAG_TEST" SG_ 2654339074 StayActiveSource_EPS_1 0;
BA_ "GenSigTimeoutTime_ECM" SG_ 2654339074 StayActiveSource_EPS_1 0;
BA_ "GenSigTimeoutTime_EPS" SG_ 2654339074 StayActiveSource_EPS_1 0;
BA_ "GenSigTimeoutTime_IPC" SG_ 2654339074 StayActiveSource_EPS_1 0;
BA_ "GenSigTimeoutTime_MTA" SG_ 2654339074 StayActiveSource_EPS_1 0;
BA_ "GenSigTimeoutTime_ORC" SG_ 2654339074 StayActiveSource_EPS_1 0;
BA_ "GenSigTimeoutTime_PAM" SG_ 2654339074 StayActiveSource_EPS_1 0;
BA_ "GenSigTimeoutTime_BCM" SG_ 2654339074 StayActiveSource_EPS_10 0;
BA_ "GenSigTimeoutTime_BSM" SG_ 2654339074 StayActiveSource_EPS_10 0;
BA_ "GenSigTimeoutTime_DIAG_TEST" SG_ 2654339074 StayActiveSource_EPS_10 0;
BA_ "GenSigTimeoutTime_ECM" SG_ 2654339074 StayActiveSource_EPS_10 0;
BA_ "GenSigTimeoutTime_EPS" SG_ 2654339074 StayActiveSource_EPS_10 0;
BA_ "GenSigTimeoutTime_IPC" SG_ 2654339074 StayActiveSource_EPS_10 0;
BA_ "GenSigTimeoutTime_MTA" SG_ 2654339074 StayActiveSource_EPS_10 0;
BA_ "GenSigTimeoutTime_ORC" SG_ 2654339074 StayActiveSource_EPS_10 0;
BA_ "GenSigTimeoutTime_PAM" SG_ 2654339074 StayActiveSource_EPS_10 0;
BA_ "GenSigTimeoutTime_BCM" SG_ 2654339074 StayActiveSource_EPS_11 0;
BA_ "GenSigTimeoutTime_BSM" SG_ 2654339074 StayActiveSource_EPS_11 0;
BA_ "GenSigTimeoutTime_DIAG_TEST" SG_ 2654339074 StayActiveSource_EPS_11 0;
BA_ "GenSigTimeoutTime_ECM" SG_ 2654339074 StayActiveSource_EPS_11 0;
BA_ "GenSigTimeoutTime_EPS" SG_ 2654339074 StayActiveSource_EPS_11 0;
BA_ "GenSigTimeoutTime_IPC" SG_ 2654339074 StayActiveSource_EPS_11 0;
BA_ "GenSigTimeoutTime_MTA" SG_ 2654339074 StayActiveSource_EPS_11 0;
BA_ "GenSigTimeoutTime_ORC" SG_ 2654339074 StayActiveSource_EPS_11 0;
BA_ "GenSigTimeoutTime_PAM" SG_ 2654339074 StayActiveSource_EPS_11 0;
BA_ "GenSigTimeoutTime_BCM" SG_ 2654339074 StayActiveSource_EPS_12 0;
BA_ "GenSigTimeoutTime_BSM" SG_ 2654339074 StayActiveSource_EPS_12 0;
BA_ "GenSigTimeoutTime_DIAG_TEST" SG_ 2654339074 StayActiveSource_EPS_12 0;
BA_ "GenSigTimeoutTime_ECM" SG_ 2654339074 StayActiveSource_EPS_12 0;
BA_ "GenSigTimeoutTime_EPS" SG_ 2654339074 StayActiveSource_EPS_12 0;
BA_ "GenSigTimeoutTime_IPC" SG_ 2654339074 StayActiveSource_EPS_12 0;
BA_ "GenSigTimeoutTime_MTA" SG_ 2654339074 StayActiveSource_EPS_12 0;
BA_ "GenSigTimeoutTime_ORC" SG_ 2654339074 StayActiveSource_EPS_12 0;
BA_ "GenSigTimeoutTime_PAM" SG_ 2654339074 StayActiveSource_EPS_12 0;
BA_ "GenSigTimeoutTime_BCM" SG_ 2654339074 StayActiveSource_EPS_13 0;
BA_ "GenSigTimeoutTime_BSM" SG_ 2654339074 StayActiveSource_EPS_13 0;
BA_ "GenSigTimeoutTime_DIAG_TEST" SG_ 2654339074 StayActiveSource_EPS_13 0;
BA_ "GenSigTimeoutTime_ECM" SG_ 2654339074 StayActiveSource_EPS_13 0;
BA_ "GenSigTimeoutTime_EPS" SG_ 2654339074 StayActiveSource_EPS_13 0;
BA_ "GenSigTimeoutTime_IPC" SG_ 2654339074 StayActiveSource_EPS_13 0;
BA_ "GenSigTimeoutTime_MTA" SG_ 2654339074 StayActiveSource_EPS_13 0;
BA_ "GenSigTimeoutTime_ORC" SG_ 2654339074 StayActiveSource_EPS_13 0;
BA_ "GenSigTimeoutTime_PAM" SG_ 2654339074 StayActiveSource_EPS_13 0;
BA_ "GenSigTimeoutTime_BCM" SG_ 2654339074 StayActiveSource_EPS_14 0;
BA_ "GenSigTimeoutTime_BSM" SG_ 2654339074 StayActiveSource_EPS_14 0;
BA_ "GenSigTimeoutTime_DIAG_TEST" SG_ 2654339074 StayActiveSource_EPS_14 0;
BA_ "GenSigTimeoutTime_ECM" SG_ 2654339074 StayActiveSource_EPS_14 0;
BA_ "GenSigTimeoutTime_EPS" SG_ 2654339074 StayActiveSource_EPS_14 0;
BA_ "GenSigTimeoutTime_IPC" SG_ 2654339074 StayActiveSource_EPS_14 0;
BA_ "GenSigTimeoutTime_MTA" SG_ 2654339074 StayActiveSource_EPS_14 0;
BA_ "GenSigTimeoutTime_ORC" SG_ 2654339074 StayActiveSource_EPS_14 0;
BA_ "GenSigTimeoutTime_PAM" SG_ 2654339074 StayActiveSource_EPS_14 0;
BA_ "GenSigTimeoutTime_BCM" SG_ 2654339074 StayActiveSource_EPS_15 0;
BA_ "GenSigTimeoutTime_BSM" SG_ 2654339074 StayActiveSource_EPS_15 0;
BA_ "GenSigTimeoutTime_DIAG_TEST" SG_ 2654339074 StayActiveSource_EPS_15 0;
BA_ "GenSigTimeoutTime_ECM" SG_ 2654339074 StayActiveSource_EPS_15 0;
BA_ "GenSigTimeoutTime_EPS" SG_ 2654339074 StayActiveSource_EPS_15 0;
BA_ "GenSigTimeoutTime_IPC" SG_ 2654339074 StayActiveSource_EPS_15 0;
BA_ "GenSigTimeoutTime_MTA" SG_ 2654339074 StayActiveSource_EPS_15 0;
BA_ "GenSigTimeoutTime_ORC" SG_ 2654339074 StayActiveSource_EPS_15 0;
BA_ "GenSigTimeoutTime_PAM" SG_ 2654339074 StayActiveSource_EPS_15 0;
BA_ "GenSigTimeoutTime_BCM" SG_ 2654339074 StayActiveSource_EPS_2 0;
BA_ "GenSigTimeoutTime_BSM" SG_ 2654339074 StayActiveSource_EPS_2 0;
BA_ "GenSigTimeoutTime_DIAG_TEST" SG_ 2654339074 StayActiveSource_EPS_2 0;
BA_ "GenSigTimeoutTime_ECM" SG_ 2654339074 StayActiveSource_EPS_2 0;
BA_ "GenSigTimeoutTime_EPS" SG_ 2654339074 StayActiveSource_EPS_2 0;
BA_ "GenSigTimeoutTime_IPC" SG_ 2654339074 StayActiveSource_EPS_2 0;
BA_ "GenSigTimeoutTime_MTA" SG_ 2654339074 StayActiveSource_EPS_2 0;
BA_ "GenSigTimeoutTime_ORC" SG_ 2654339074 StayActiveSource_EPS_2 0;
BA_ "GenSigTimeoutTime_PAM" SG_ 2654339074 StayActiveSource_EPS_2 0;
BA_ "GenSigTimeoutTime_BCM" SG_ 2654339074 StayActiveSource_EPS_3 0;
BA_ "GenSigTimeoutTime_BSM" SG_ 2654339074 StayActiveSource_EPS_3 0;
BA_ "GenSigTimeoutTime_DIAG_TEST" SG_ 2654339074 StayActiveSource_EPS_3 0;
BA_ "GenSigTimeoutTime_ECM" SG_ 2654339074 StayActiveSource_EPS_3 0;
BA_ "GenSigTimeoutTime_EPS" SG_ 2654339074 StayActiveSource_EPS_3 0;
BA_ "GenSigTimeoutTime_IPC" SG_ 2654339074 StayActiveSource_EPS_3 0;
BA_ "GenSigTimeoutTime_MTA" SG_ 2654339074 StayActiveSource_EPS_3 0;
BA_ "GenSigTimeoutTime_ORC" SG_ 2654339074 StayActiveSource_EPS_3 0;
BA_ "GenSigTimeoutTime_PAM" SG_ 2654339074 StayActiveSource_EPS_3 0;
BA_ "GenSigTimeoutTime_BCM" SG_ 2654339074 StayActiveSource_EPS_4 0;
BA_ "GenSigTimeoutTime_BSM" SG_ 2654339074 StayActiveSource_EPS_4 0;
BA_ "GenSigTimeoutTime_DIAG_TEST" SG_ 2654339074 StayActiveSource_EPS_4 0;
BA_ "GenSigTimeoutTime_ECM" SG_ 2654339074 StayActiveSource_EPS_4 0;
BA_ "GenSigTimeoutTime_EPS" SG_ 2654339074 StayActiveSource_EPS_4 0;
BA_ "GenSigTimeoutTime_IPC" SG_ 2654339074 StayActiveSource_EPS_4 0;
BA_ "GenSigTimeoutTime_MTA" SG_ 2654339074 StayActiveSource_EPS_4 0;
BA_ "GenSigTimeoutTime_ORC" SG_ 2654339074 StayActiveSource_EPS_4 0;
BA_ "GenSigTimeoutTime_PAM" SG_ 2654339074 StayActiveSource_EPS_4 0;
BA_ "GenSigTimeoutTime_BCM" SG_ 2654339074 StayActiveSource_EPS_5 0;
BA_ "GenSigTimeoutTime_BSM" SG_ 2654339074 StayActiveSource_EPS_5 0;
BA_ "GenSigTimeoutTime_DIAG_TEST" SG_ 2654339074 StayActiveSource_EPS_5 0;
BA_ "GenSigTimeoutTime_ECM" SG_ 2654339074 StayActiveSource_EPS_5 0;
BA_ "GenSigTimeoutTime_EPS" SG_ 2654339074 StayActiveSource_EPS_5 0;
BA_ "GenSigTimeoutTime_IPC" SG_ 2654339074 StayActiveSource_EPS_5 0;
BA_ "GenSigTimeoutTime_MTA" SG_ 2654339074 StayActiveSource_EPS_5 0;
BA_ "GenSigTimeoutTime_ORC" SG_ 2654339074 StayActiveSource_EPS_5 0;
BA_ "GenSigTimeoutTime_PAM" SG_ 2654339074 StayActiveSource_EPS_5 0;
BA_ "GenSigTimeoutTime_BCM" SG_ 2654339074 StayActiveSource_EPS_6 0;
BA_ "GenSigTimeoutTime_BSM" SG_ 2654339074 StayActiveSource_EPS_6 0;
BA_ "GenSigTimeoutTime_DIAG_TEST" SG_ 2654339074 StayActiveSource_EPS_6 0;
BA_ "GenSigTimeoutTime_ECM" SG_ 2654339074 StayActiveSource_EPS_6 0;
BA_ "GenSigTimeoutTime_EPS" SG_ 2654339074 StayActiveSource_EPS_6 0;
BA_ "GenSigTimeoutTime_IPC" SG_ 2654339074 StayActiveSource_EPS_6 0;
BA_ "GenSigTimeoutTime_MTA" SG_ 2654339074 StayActiveSource_EPS_6 0;
BA_ "GenSigTimeoutTime_ORC" SG_ 2654339074 StayActiveSource_EPS_6 0;
BA_ "GenSigTimeoutTime_PAM" SG_ 2654339074 StayActiveSource_EPS_6 0;
BA_ "GenSigTimeoutTime_BCM" SG_ 2654339074 StayActiveSource_EPS_7 0;
BA_ "GenSigTimeoutTime_BSM" SG_ 2654339074 StayActiveSource_EPS_7 0;
BA_ "GenSigTimeoutTime_DIAG_TEST" SG_ 2654339074 StayActiveSource_EPS_7 0;
BA_ "GenSigTimeoutTime_ECM" SG_ 2654339074 StayActiveSource_EPS_7 0;
BA_ "GenSigTimeoutTime_EPS" SG_ 2654339074 StayActiveSource_EPS_7 0;
BA_ "GenSigTimeoutTime_IPC" SG_ 2654339074 StayActiveSource_EPS_7 0;
BA_ "GenSigTimeoutTime_MTA" SG_ 2654339074 StayActiveSource_EPS_7 0;
BA_ "GenSigTimeoutTime_ORC" SG_ 2654339074 StayActiveSource_EPS_7 0;
BA_ "GenSigTimeoutTime_PAM" SG_ 2654339074 StayActiveSource_EPS_7 0;
BA_ "GenSigTimeoutTime_BCM" SG_ 2654339074 StayActiveSource_EPS_8 0;
BA_ "GenSigTimeoutTime_BSM" SG_ 2654339074 StayActiveSource_EPS_8 0;
BA_ "GenSigTimeoutTime_DIAG_TEST" SG_ 2654339074 StayActiveSource_EPS_8 0;
BA_ "GenSigTimeoutTime_ECM" SG_ 2654339074 StayActiveSource_EPS_8 0;
BA_ "GenSigTimeoutTime_EPS" SG_ 2654339074 StayActiveSource_EPS_8 0;
BA_ "GenSigTimeoutTime_IPC" SG_ 2654339074 StayActiveSource_EPS_8 0;
BA_ "GenSigTimeoutTime_MTA" SG_ 2654339074 StayActiveSource_EPS_8 0;
BA_ "GenSigTimeoutTime_ORC" SG_ 2654339074 StayActiveSource_EPS_8 0;
BA_ "GenSigTimeoutTime_PAM" SG_ 2654339074 StayActiveSource_EPS_8 0;
BA_ "GenSigTimeoutTime_BCM" SG_ 2654339074 StayActiveSource_EPS_9 0;
BA_ "GenSigTimeoutTime_BSM" SG_ 2654339074 StayActiveSource_EPS_9 0;
BA_ "GenSigTimeoutTime_DIAG_TEST" SG_ 2654339074 StayActiveSource_EPS_9 0;
BA_ "GenSigTimeoutTime_ECM" SG_ 2654339074 StayActiveSource_EPS_9 0;
BA_ "GenSigTimeoutTime_EPS" SG_ 2654339074 StayActiveSource_EPS_9 0;
BA_ "GenSigTimeoutTime_IPC" SG_ 2654339074 StayActiveSource_EPS_9 0;
BA_ "GenSigTimeoutTime_MTA" SG_ 2654339074 StayActiveSource_EPS_9 0;
BA_ "GenSigTimeoutTime_ORC" SG_ 2654339074 StayActiveSource_EPS_9 0;
BA_ "GenSigTimeoutTime_PAM" SG_ 2654339074 StayActiveSource_EPS_9 0;
BA_ "GenSigTimeoutTime_BSM" SG_ 2654339075 CurrentFailSts_IPC 0;
BA_ "GenSigTimeoutTime_DIAG_TEST" SG_ 2654339075 CurrentFailSts_IPC 0;
BA_ "GenSigTimeoutTime_ECM" SG_ 2654339075 CurrentFailSts_IPC 0;
BA_ "GenSigTimeoutTime_EPS" SG_ 2654339075 CurrentFailSts_IPC 0;
BA_ "GenSigTimeoutTime_IPC" SG_ 2654339075 CurrentFailSts_IPC 0;
BA_ "GenSigTimeoutTime_MTA" SG_ 2654339075 CurrentFailSts_IPC 0;
BA_ "GenSigTimeoutTime_ORC" SG_ 2654339075 CurrentFailSts_IPC 0;
BA_ "GenSigTimeoutTime_PAM" SG_ 2654339075 CurrentFailSts_IPC 0;
BA_ "GenSigTimeoutTime_BCM" SG_ 2654339075 DES_IPC 0;
BA_ "GenSigTimeoutTime_BSM" SG_ 2654339075 DES_IPC 0;
BA_ "GenSigTimeoutTime_DIAG_TEST" SG_ 2654339075 DES_IPC 0;
BA_ "GenSigTimeoutTime_ECM" SG_ 2654339075 DES_IPC 0;
BA_ "GenSigTimeoutTime_EPS" SG_ 2654339075 DES_IPC 0;
BA_ "GenSigTimeoutTime_IPC" SG_ 2654339075 DES_IPC 0;
BA_ "GenSigTimeoutTime_MTA" SG_ 2654339075 DES_IPC 0;
BA_ "GenSigTimeoutTime_ORC" SG_ 2654339075 DES_IPC 0;
BA_ "GenSigTimeoutTime_PAM" SG_ 2654339075 DES_IPC 0;
BA_ "GenSigTimeoutTime_BSM" SG_ 2654339075 EOL_IPC 0;
BA_ "GenSigTimeoutTime_DIAG_TEST" SG_ 2654339075 EOL_IPC 0;
BA_ "GenSigTimeoutTime_ECM" SG_ 2654339075 EOL_IPC 0;
BA_ "GenSigTimeoutTime_EPS" SG_ 2654339075 EOL_IPC 0;
BA_ "GenSigTimeoutTime_IPC" SG_ 2654339075 EOL_IPC 0;
BA_ "GenSigTimeoutTime_MTA" SG_ 2654339075 EOL_IPC 0;
BA_ "GenSigTimeoutTime_ORC" SG_ 2654339075 EOL_IPC 0;
BA_ "GenSigTimeoutTime_PAM" SG_ 2654339075 EOL_IPC 0;
BA_ "GenSigTimeoutTime_BSM" SG_ 2654339075 GenericFailSts_IPC 0;
BA_ "GenSigTimeoutTime_DIAG_TEST" SG_ 2654339075 GenericFailSts_IPC 0;
BA_ "GenSigTimeoutTime_ECM" SG_ 2654339075 GenericFailSts_IPC 0;
BA_ "GenSigTimeoutTime_EPS" SG_ 2654339075 GenericFailSts_IPC 0;
BA_ "GenSigTimeoutTime_IPC" SG_ 2654339075 GenericFailSts_IPC 0;
BA_ "GenSigTimeoutTime_MTA" SG_ 2654339075 GenericFailSts_IPC 0;
BA_ "GenSigTimeoutTime_ORC" SG_ 2654339075 GenericFailSts_IPC 0;
BA_ "GenSigTimeoutTime_PAM" SG_ 2654339075 GenericFailSts_IPC 0;
BA_ "GenSigTimeoutTime_BCM" SG_ 2654339075 Reserved_for_PDC_IPC 0;
BA_ "GenSigTimeoutTime_BSM" SG_ 2654339075 Reserved_for_PDC_IPC 0;
BA_ "GenSigTimeoutTime_DIAG_TEST" SG_ 2654339075 Reserved_for_PDC_IPC 0;
BA_ "GenSigTimeoutTime_ECM" SG_ 2654339075 Reserved_for_PDC_IPC 0;
BA_ "GenSigTimeoutTime_EPS" SG_ 2654339075 Reserved_for_PDC_IPC 0;
BA_ "GenSigTimeoutTime_IPC" SG_ 2654339075 Reserved_for_PDC_IPC 0;
BA_ "GenSigTimeoutTime_MTA" SG_ 2654339075 Reserved_for_PDC_IPC 0;
BA_ "GenSigTimeoutTime_ORC" SG_ 2654339075 Reserved_for_PDC_IPC 0;
BA_ "GenSigTimeoutTime_PAM" SG_ 2654339075 Reserved_for_PDC_IPC 0;
BA_ "GenSigTimeoutTime_BCM" SG_ 2654339075 StayActiveSource_IPC_0 0;
BA_ "GenSigTimeoutTime_BSM" SG_ 2654339075 StayActiveSource_IPC_0 0;
BA_ "GenSigTimeoutTime_DIAG_TEST" SG_ 2654339075 StayActiveSource_IPC_0 0;
BA_ "GenSigTimeoutTime_ECM" SG_ 2654339075 StayActiveSource_IPC_0 0;
BA_ "GenSigTimeoutTime_EPS" SG_ 2654339075 StayActiveSource_IPC_0 0;
BA_ "GenSigTimeoutTime_IPC" SG_ 2654339075 StayActiveSource_IPC_0 0;
BA_ "GenSigTimeoutTime_MTA" SG_ 2654339075 StayActiveSource_IPC_0 0;
BA_ "GenSigTimeoutTime_ORC" SG_ 2654339075 StayActiveSource_IPC_0 0;
BA_ "GenSigTimeoutTime_PAM" SG_ 2654339075 StayActiveSource_IPC_0 0;
BA_ "GenSigTimeoutTime_BCM" SG_ 2654339075 StayActiveSource_IPC_1 0;
BA_ "GenSigTimeoutTime_BSM" SG_ 2654339075 StayActiveSource_IPC_1 0;
BA_ "GenSigTimeoutTime_DIAG_TEST" SG_ 2654339075 StayActiveSource_IPC_1 0;
BA_ "GenSigTimeoutTime_ECM" SG_ 2654339075 StayActiveSource_IPC_1 0;
BA_ "GenSigTimeoutTime_EPS" SG_ 2654339075 StayActiveSource_IPC_1 0;
BA_ "GenSigTimeoutTime_IPC" SG_ 2654339075 StayActiveSource_IPC_1 0;
BA_ "GenSigTimeoutTime_MTA" SG_ 2654339075 StayActiveSource_IPC_1 0;
BA_ "GenSigTimeoutTime_ORC" SG_ 2654339075 StayActiveSource_IPC_1 0;
BA_ "GenSigTimeoutTime_PAM" SG_ 2654339075 StayActiveSource_IPC_1 0;
BA_ "GenSigTimeoutTime_BCM" SG_ 2654339075 StayActiveSource_IPC_10 0;
BA_ "GenSigTimeoutTime_BSM" SG_ 2654339075 StayActiveSource_IPC_10 0;
BA_ "GenSigTimeoutTime_DIAG_TEST" SG_ 2654339075 StayActiveSource_IPC_10 0;
BA_ "GenSigTimeoutTime_ECM" SG_ 2654339075 StayActiveSource_IPC_10 0;
BA_ "GenSigTimeoutTime_EPS" SG_ 2654339075 StayActiveSource_IPC_10 0;
BA_ "GenSigTimeoutTime_IPC" SG_ 2654339075 StayActiveSource_IPC_10 0;
BA_ "GenSigTimeoutTime_MTA" SG_ 2654339075 StayActiveSource_IPC_10 0;
BA_ "GenSigTimeoutTime_ORC" SG_ 2654339075 StayActiveSource_IPC_10 0;
BA_ "GenSigTimeoutTime_PAM" SG_ 2654339075 StayActiveSource_IPC_10 0;
BA_ "GenSigTimeoutTime_BCM" SG_ 2654339075 StayActiveSource_IPC_11 0;
BA_ "GenSigTimeoutTime_BSM" SG_ 2654339075 StayActiveSource_IPC_11 0;
BA_ "GenSigTimeoutTime_DIAG_TEST" SG_ 2654339075 StayActiveSource_IPC_11 0;
BA_ "GenSigTimeoutTime_ECM" SG_ 2654339075 StayActiveSource_IPC_11 0;
BA_ "GenSigTimeoutTime_EPS" SG_ 2654339075 StayActiveSource_IPC_11 0;
BA_ "GenSigTimeoutTime_IPC" SG_ 2654339075 StayActiveSource_IPC_11 0;
BA_ "GenSigTimeoutTime_MTA" SG_ 2654339075 StayActiveSource_IPC_11 0;
BA_ "GenSigTimeoutTime_ORC" SG_ 2654339075 StayActiveSource_IPC_11 0;
BA_ "GenSigTimeoutTime_PAM" SG_ 2654339075 StayActiveSource_IPC_11 0;
BA_ "GenSigTimeoutTime_BCM" SG_ 2654339075 StayActiveSource_IPC_12 0;
BA_ "GenSigTimeoutTime_BSM" SG_ 2654339075 StayActiveSource_IPC_12 0;
BA_ "GenSigTimeoutTime_DIAG_TEST" SG_ 2654339075 StayActiveSource_IPC_12 0;
BA_ "GenSigTimeoutTime_ECM" SG_ 2654339075 StayActiveSource_IPC_12 0;
BA_ "GenSigTimeoutTime_EPS" SG_ 2654339075 StayActiveSource_IPC_12 0;
BA_ "GenSigTimeoutTime_IPC" SG_ 2654339075 StayActiveSource_IPC_12 0;
BA_ "GenSigTimeoutTime_MTA" SG_ 2654339075 StayActiveSource_IPC_12 0;
BA_ "GenSigTimeoutTime_ORC" SG_ 2654339075 StayActiveSource_IPC_12 0;
BA_ "GenSigTimeoutTime_PAM" SG_ 2654339075 StayActiveSource_IPC_12 0;
BA_ "GenSigTimeoutTime_BCM" SG_ 2654339075 StayActiveSource_IPC_13 0;
BA_ "GenSigTimeoutTime_BSM" SG_ 2654339075 StayActiveSource_IPC_13 0;
BA_ "GenSigTimeoutTime_DIAG_TEST" SG_ 2654339075 StayActiveSource_IPC_13 0;
BA_ "GenSigTimeoutTime_ECM" SG_ 2654339075 StayActiveSource_IPC_13 0;
BA_ "GenSigTimeoutTime_EPS" SG_ 2654339075 StayActiveSource_IPC_13 0;
BA_ "GenSigTimeoutTime_IPC" SG_ 2654339075 StayActiveSource_IPC_13 0;
BA_ "GenSigTimeoutTime_MTA" SG_ 2654339075 StayActiveSource_IPC_13 0;
BA_ "GenSigTimeoutTime_ORC" SG_ 2654339075 StayActiveSource_IPC_13 0;
BA_ "GenSigTimeoutTime_PAM" SG_ 2654339075 StayActiveSource_IPC_13 0;
BA_ "GenSigTimeoutTime_BCM" SG_ 2654339075 StayActiveSource_IPC_14 0;
BA_ "GenSigTimeoutTime_BSM" SG_ 2654339075 StayActiveSource_IPC_14 0;
BA_ "GenSigTimeoutTime_DIAG_TEST" SG_ 2654339075 StayActiveSource_IPC_14 0;
BA_ "GenSigTimeoutTime_ECM" SG_ 2654339075 StayActiveSource_IPC_14 0;
BA_ "GenSigTimeoutTime_EPS" SG_ 2654339075 StayActiveSource_IPC_14 0;
BA_ "GenSigTimeoutTime_IPC" SG_ 2654339075 StayActiveSource_IPC_14 0;
BA_ "GenSigTimeoutTime_MTA" SG_ 2654339075 StayActiveSource_IPC_14 0;
BA_ "GenSigTimeoutTime_ORC" SG_ 2654339075 StayActiveSource_IPC_14 0;
BA_ "GenSigTimeoutTime_PAM" SG_ 2654339075 StayActiveSource_IPC_14 0;
BA_ "GenSigTimeoutTime_BCM" SG_ 2654339075 StayActiveSource_IPC_15 0;
BA_ "GenSigTimeoutTime_BSM" SG_ 2654339075 StayActiveSource_IPC_15 0;
BA_ "GenSigTimeoutTime_DIAG_TEST" SG_ 2654339075 StayActiveSource_IPC_15 0;
BA_ "GenSigTimeoutTime_ECM" SG_ 2654339075 StayActiveSource_IPC_15 0;
BA_ "GenSigTimeoutTime_EPS" SG_ 2654339075 StayActiveSource_IPC_15 0;
BA_ "GenSigTimeoutTime_IPC" SG_ 2654339075 StayActiveSource_IPC_15 0;
BA_ "GenSigTimeoutTime_MTA" SG_ 2654339075 StayActiveSource_IPC_15 0;
BA_ "GenSigTimeoutTime_ORC" SG_ 2654339075 StayActiveSource_IPC_15 0;
BA_ "GenSigTimeoutTime_PAM" SG_ 2654339075 StayActiveSource_IPC_15 0;
BA_ "GenSigTimeoutTime_BCM" SG_ 2654339075 StayActiveSource_IPC_2 0;
BA_ "GenSigTimeoutTime_BSM" SG_ 2654339075 StayActiveSource_IPC_2 0;
BA_ "GenSigTimeoutTime_DIAG_TEST" SG_ 2654339075 StayActiveSource_IPC_2 0;
BA_ "GenSigTimeoutTime_ECM" SG_ 2654339075 StayActiveSource_IPC_2 0;
BA_ "GenSigTimeoutTime_EPS" SG_ 2654339075 StayActiveSource_IPC_2 0;
BA_ "GenSigTimeoutTime_IPC" SG_ 2654339075 StayActiveSource_IPC_2 0;
BA_ "GenSigTimeoutTime_MTA" SG_ 2654339075 StayActiveSource_IPC_2 0;
BA_ "GenSigTimeoutTime_ORC" SG_ 2654339075 StayActiveSource_IPC_2 0;
BA_ "GenSigTimeoutTime_PAM" SG_ 2654339075 StayActiveSource_IPC_2 0;
BA_ "GenSigTimeoutTime_BCM" SG_ 2654339075 StayActiveSource_IPC_3 0;
BA_ "GenSigTimeoutTime_BSM" SG_ 2654339075 StayActiveSource_IPC_3 0;
BA_ "GenSigTimeoutTime_DIAG_TEST" SG_ 2654339075 StayActiveSource_IPC_3 0;
BA_ "GenSigTimeoutTime_ECM" SG_ 2654339075 StayActiveSource_IPC_3 0;
BA_ "GenSigTimeoutTime_EPS" SG_ 2654339075 StayActiveSource_IPC_3 0;
BA_ "GenSigTimeoutTime_IPC" SG_ 2654339075 StayActiveSource_IPC_3 0;
BA_ "GenSigTimeoutTime_MTA" SG_ 2654339075 StayActiveSource_IPC_3 0;
BA_ "GenSigTimeoutTime_ORC" SG_ 2654339075 StayActiveSource_IPC_3 0;
BA_ "GenSigTimeoutTime_PAM" SG_ 2654339075 StayActiveSource_IPC_3 0;
BA_ "GenSigTimeoutTime_BCM" SG_ 2654339075 StayActiveSource_IPC_4 0;
BA_ "GenSigTimeoutTime_BSM" SG_ 2654339075 StayActiveSource_IPC_4 0;
BA_ "GenSigTimeoutTime_DIAG_TEST" SG_ 2654339075 StayActiveSource_IPC_4 0;
BA_ "GenSigTimeoutTime_ECM" SG_ 2654339075 StayActiveSource_IPC_4 0;
BA_ "GenSigTimeoutTime_EPS" SG_ 2654339075 StayActiveSource_IPC_4 0;
BA_ "GenSigTimeoutTime_IPC" SG_ 2654339075 StayActiveSource_IPC_4 0;
BA_ "GenSigTimeoutTime_MTA" SG_ 2654339075 StayActiveSource_IPC_4 0;
BA_ "GenSigTimeoutTime_ORC" SG_ 2654339075 StayActiveSource_IPC_4 0;
BA_ "GenSigTimeoutTime_PAM" SG_ 2654339075 StayActiveSource_IPC_4 0;
BA_ "GenSigTimeoutTime_BCM" SG_ 2654339075 StayActiveSource_IPC_5 0;
BA_ "GenSigTimeoutTime_BSM" SG_ 2654339075 StayActiveSource_IPC_5 0;
BA_ "GenSigTimeoutTime_DIAG_TEST" SG_ 2654339075 StayActiveSource_IPC_5 0;
BA_ "GenSigTimeoutTime_ECM" SG_ 2654339075 StayActiveSource_IPC_5 0;
BA_ "GenSigTimeoutTime_EPS" SG_ 2654339075 StayActiveSource_IPC_5 0;
BA_ "GenSigTimeoutTime_IPC" SG_ 2654339075 StayActiveSource_IPC_5 0;
BA_ "GenSigTimeoutTime_MTA" SG_ 2654339075 StayActiveSource_IPC_5 0;
BA_ "GenSigTimeoutTime_ORC" SG_ 2654339075 StayActiveSource_IPC_5 0;
BA_ "GenSigTimeoutTime_PAM" SG_ 2654339075 StayActiveSource_IPC_5 0;
BA_ "GenSigTimeoutTime_BCM" SG_ 2654339075 StayActiveSource_IPC_6 0;
BA_ "GenSigTimeoutTime_BSM" SG_ 2654339075 StayActiveSource_IPC_6 0;
BA_ "GenSigTimeoutTime_DIAG_TEST" SG_ 2654339075 StayActiveSource_IPC_6 0;
BA_ "GenSigTimeoutTime_ECM" SG_ 2654339075 StayActiveSource_IPC_6 0;
BA_ "GenSigTimeoutTime_EPS" SG_ 2654339075 StayActiveSource_IPC_6 0;
BA_ "GenSigTimeoutTime_IPC" SG_ 2654339075 StayActiveSource_IPC_6 0;
BA_ "GenSigTimeoutTime_MTA" SG_ 2654339075 StayActiveSource_IPC_6 0;
BA_ "GenSigTimeoutTime_ORC" SG_ 2654339075 StayActiveSource_IPC_6 0;
BA_ "GenSigTimeoutTime_PAM" SG_ 2654339075 StayActiveSource_IPC_6 0;
BA_ "GenSigTimeoutTime_BCM" SG_ 2654339075 StayActiveSource_IPC_7 0;
BA_ "GenSigTimeoutTime_BSM" SG_ 2654339075 StayActiveSource_IPC_7 0;
BA_ "GenSigTimeoutTime_DIAG_TEST" SG_ 2654339075 StayActiveSource_IPC_7 0;
BA_ "GenSigTimeoutTime_ECM" SG_ 2654339075 StayActiveSource_IPC_7 0;
BA_ "GenSigTimeoutTime_EPS" SG_ 2654339075 StayActiveSource_IPC_7 0;
BA_ "GenSigTimeoutTime_IPC" SG_ 2654339075 StayActiveSource_IPC_7 0;
BA_ "GenSigTimeoutTime_MTA" SG_ 2654339075 StayActiveSource_IPC_7 0;
BA_ "GenSigTimeoutTime_ORC" SG_ 2654339075 StayActiveSource_IPC_7 0;
BA_ "GenSigTimeoutTime_PAM" SG_ 2654339075 StayActiveSource_IPC_7 0;
BA_ "GenSigTimeoutTime_BCM" SG_ 2654339075 StayActiveSource_IPC_8 0;
BA_ "GenSigTimeoutTime_BSM" SG_ 2654339075 StayActiveSource_IPC_8 0;
BA_ "GenSigTimeoutTime_DIAG_TEST" SG_ 2654339075 StayActiveSource_IPC_8 0;
BA_ "GenSigTimeoutTime_ECM" SG_ 2654339075 StayActiveSource_IPC_8 0;
BA_ "GenSigTimeoutTime_EPS" SG_ 2654339075 StayActiveSource_IPC_8 0;
BA_ "GenSigTimeoutTime_IPC" SG_ 2654339075 StayActiveSource_IPC_8 0;
BA_ "GenSigTimeoutTime_MTA" SG_ 2654339075 StayActiveSource_IPC_8 0;
BA_ "GenSigTimeoutTime_ORC" SG_ 2654339075 StayActiveSource_IPC_8 0;
BA_ "GenSigTimeoutTime_PAM" SG_ 2654339075 StayActiveSource_IPC_8 0;
BA_ "GenSigTimeoutTime_BCM" SG_ 2654339075 StayActiveSource_IPC_9 0;
BA_ "GenSigTimeoutTime_BSM" SG_ 2654339075 StayActiveSource_IPC_9 0;
BA_ "GenSigTimeoutTime_DIAG_TEST" SG_ 2654339075 StayActiveSource_IPC_9 0;
BA_ "GenSigTimeoutTime_ECM" SG_ 2654339075 StayActiveSource_IPC_9 0;
BA_ "GenSigTimeoutTime_EPS" SG_ 2654339075 StayActiveSource_IPC_9 0;
BA_ "GenSigTimeoutTime_IPC" SG_ 2654339075 StayActiveSource_IPC_9 0;
BA_ "GenSigTimeoutTime_MTA" SG_ 2654339075 StayActiveSource_IPC_9 0;
BA_ "GenSigTimeoutTime_ORC" SG_ 2654339075 StayActiveSource_IPC_9 0;
BA_ "GenSigTimeoutTime_PAM" SG_ 2654339075 StayActiveSource_IPC_9 0;
VAL_ 750 EngineStopStartSts 0 "Engine_Stop" 1 "Engine_Not_in_Stop" 2 "Engine_Stall" 3 "Engine_Stopping" ;
VAL_ 750 EngineWaterTemp 255 "SNA" ;
VAL_ 750 EngineWaterTempFailSts 0 "Fail_Not_Present" 1 "Fail_Present" ;
VAL_ 750 FuelConsumption_GAG 65535 "SNA" ;
VAL_ 750 GearShiftIndication 0 "No_Gearshift_Suggestion_by_ECM" 1 "Downshift_Suggestion_by_ECM" 2 "Upshift_Suggestion_by_ECM" 3 "Strategy_Not_Available_ECM_Fail" ;
VAL_ 750 RechargeSts 0 "Charging" 1 "Not_Charging" ;
VAL_ 750 SAMInfo 0 "SAMOFF" 1 "Engine_OFF" 2 "Cranking_management" 3 "ColdEngineManagement" 4 "PassiveBoost" 5 "Steady_State" 6 "RegenerativeBraking" 7 "QuickCharge" 8 "Auto_Shut_OFF" 9 "Shut_OFF" 10 "SAM_recovery" 11 "Battery_Regeneration" 12 "Not_Used" 13 "Not_Used" 14 "Not_Used" 15 "SNA" ;
VAL_ 750 StartRelayBCMFeedbackFault 0 "False" 1 "True" ;
VAL_ 750 StartRelayECMFeedbackFault 0 "False" 1 "True" ;
VAL_ 750 StopStartFaultSts 0 "False" 1 "True" ;
VAL_ 750 StopStartSts 0 "OFF" 1 "ON" 2 "Functional_Disable_Request" 3 "Safety_Disable_Request" ;
VAL_ 1054 AF_FailSts 0 "Fail_Not_Present" 1 "Fail_Present" ;
VAL_ 1054 AtmosphericPressure 255 "SNA" ;
VAL_ 1054 AtmosphericPressureFailSts 0 "Fail_Not_Present" 1 "Fail_Present" ;
VAL_ 2654208000 CBV_bit4_ActiveWakeupBit 0 "PassiveWakeup" 1 "ActiveWakeup" ;
VAL_ 2654208006 CBV_bit4_ActiveWakeupBit 0 "PassiveWakeup" 1 "ActiveWakeup" ;
VAL_ 2654208001 CBV_bit4_ActiveWakeupBit 0 "PassiveWakeup" 1 "ActiveWakeup" ;
VAL_ 2654208002 CBV_bit4_ActiveWakeupBit 0 "PassiveWakeup" 1 "ActiveWakeup" ;
VAL_ 2654208003 CBV_bit4_ActiveWakeupBit 0 "PassiveWakeup" 1 "ActiveWakeup" ;
VAL_ 2654208011 CBV_bit4_ActiveWakeupBit 0 "PassiveWakeup" 1 "ActiveWakeup" ;
VAL_ 270 InternalError 0 "No_int_processing_error_detected" 1 "Int_processing_error_detected" ;
VAL_ 270 LatAcceleration 4095 "SNA" ;
VAL_ 270 LatAccelerationFailSts 0 "Fail_Not_Present" 1 "Fail_Present" ;
VAL_ 270 LongAcceleration 4095 "SNA" ;
VAL_ 270 LongAccelerationFailSts 0 "Fail_Not_Present" 1 "Fail_Present" ;
VAL_ 270 YawRate 4095 "SNA" ;
VAL_ 270 YawRateFailSts 0 "Fail_Not_Present" 1 "Fail_Present" ;
VAL_ 999 Alert_CHR 0 "No_object_detected" 1 "1_Arc" 2 "2_Arc" 3 "3_Arc" 4 "4_Arc" 5 "5_Arc" 6 "6_Arc" 7 "SNA" ;
VAL_ 999 Alert_LHR 0 "No_object_detected" 1 "1_Arc" 2 "2_Arc" 7 "SNA" ;
VAL_ 999 Alert_RHR 0 "No_object_detected" 1 "1_Arc" 2 "2_Arc" 7 "SNA" ;
VAL_ 999 ChimeActivation_LHR 0 "NotActive" 1 "Active" ;
VAL_ 999 ChimeActivation_RHR 0 "NotActive" 1 "Active" ;
VAL_ 999 ChimeType_Rear 0 "Type0" 1 "Type1" 2 "Type2" 3 "Type3" ;
VAL_ 999 DisplayActivation 0 "NotActive" 1 "Active" ;
VAL_ 999 Graphic_CHR 0 "Slow_flash" 1 "Solid" 2 "None" 3 "SNA" ;
VAL_ 999 Graphic_LHR 0 "Slow_flash" 1 "Solid" 2 "None" 3 "SNA" ;
VAL_ 999 Graphic_RHR 0 "Slow_flash" 1 "Solid" 2 "None" 3 "SNA" ;
VAL_ 2654339072 CurrentFailSts_BCM 0 "No_Fail_Present" 1 "Fail_Present" ;
VAL_ 2654339072 DES_BCM 0 "No_Busoff" 1 "Busoff_Occurred" ;
VAL_ 2654339072 EOL_BCM 0 "No_EOL_Programming" 1 "EOL_Programming" ;
VAL_ 2654339072 GenericFailSts_BCM 0 "No_Fail_Present" 1 "Fail_Present" ;
VAL_ 2654339072 StayActiveSource_BCM_0 0 "Active" 1 "NotActive" ;
VAL_ 2654339072 StayActiveSource_BCM_1 0 "Active" 1 "NotActive" ;
VAL_ 2654339072 StayActiveSource_BCM_10 0 "Active" 1 "NotActive" ;
VAL_ 2654339072 StayActiveSource_BCM_11 0 "Active" 1 "NotActive" ;
VAL_ 2654339072 StayActiveSource_BCM_12 0 "Active" 1 "NotActive" ;
VAL_ 2654339072 StayActiveSource_BCM_13 0 "Active" 1 "NotActive" ;
VAL_ 2654339072 StayActiveSource_BCM_14 0 "Active" 1 "NotActive" ;
VAL_ 2654339072 StayActiveSource_BCM_15 0 "Active" 1 "NotActive" ;
VAL_ 2654339072 StayActiveSource_BCM_2 0 "Active" 1 "NotActive" ;
VAL_ 2654339072 StayActiveSource_BCM_3 0 "Active" 1 "NotActive" ;
VAL_ 2654339072 StayActiveSource_BCM_4 0 "Active" 1 "NotActive" ;
VAL_ 2654339072 StayActiveSource_BCM_5 0 "Active" 1 "NotActive" ;
VAL_ 2654339072 StayActiveSource_BCM_6 0 "Active" 1 "NotActive" ;
VAL_ 2654339072 StayActiveSource_BCM_7 0 "Active" 1 "NotActive" ;
VAL_ 2654339072 StayActiveSource_BCM_8 0 "Active" 1 "NotActive" ;
VAL_ 2654339072 StayActiveSource_BCM_9 0 "Active" 1 "NotActive" ;
VAL_ 2654339078 CurrentFailSts_BSM 0 "No_Fail_Present" 1 "Fail_Present" ;
VAL_ 2654339078 DES_BSM 0 "No_Busoff" 1 "Busoff_Occurred" ;
VAL_ 2654339078 EOL_BSM 0 "No_EOL_Programming" 1 "EOL_Programming" ;
VAL_ 2654339078 GenericFailSts_BSM 0 "No_Fail_Present" 1 "Fail_Present" ;
VAL_ 2654339078 StayActiveSource_BSM_0 0 "Active" 1 "NotActive" ;
VAL_ 2654339078 StayActiveSource_BSM_1 0 "Active" 1 "NotActive" ;
VAL_ 2654339078 StayActiveSource_BSM_10 0 "Active" 1 "NotActive" ;
VAL_ 2654339078 StayActiveSource_BSM_11 0 "Active" 1 "NotActive" ;
VAL_ 2654339078 StayActiveSource_BSM_12 0 "Active" 1 "NotActive" ;
VAL_ 2654339078 StayActiveSource_BSM_13 0 "Active" 1 "NotActive" ;
VAL_ 2654339078 StayActiveSource_BSM_14 0 "Active" 1 "NotActive" ;
VAL_ 2654339078 StayActiveSource_BSM_15 0 "Active" 1 "NotActive" ;
VAL_ 2654339078 StayActiveSource_BSM_2 0 "Active" 1 "NotActive" ;
VAL_ 2654339078 StayActiveSource_BSM_3 0 "Active" 1 "NotActive" ;
VAL_ 2654339078 StayActiveSource_BSM_4 0 "Active" 1 "NotActive" ;
VAL_ 2654339078 StayActiveSource_BSM_5 0 "Active" 1 "NotActive" ;
VAL_ 2654339078 StayActiveSource_BSM_6 0 "Active" 1 "NotActive" ;
VAL_ 2654339078 StayActiveSource_BSM_7 0 "Active" 1 "NotActive" ;
VAL_ 2654339078 StayActiveSource_BSM_8 0 "Active" 1 "NotActive" ;
VAL_ 2654339078 StayActiveSource_BSM_9 0 "Active" 1 "NotActive" ;
VAL_ 2654339073 CurrentFailSts_ECM 0 "No_Fail_Present" 1 "Fail_Present" ;
VAL_ 2654339073 DES_ECM 0 "No_Busoff" 1 "Busoff_Occurred" ;
VAL_ 2654339073 EOL_ECM 0 "No_EOL_Programming" 1 "EOL_Programming" ;
VAL_ 2654339073 GenericFailSts_ECM 0 "No_Fail_Present" 1 "Fail_Present" ;
VAL_ 2654339073 StayActiveSource_ECM_0 0 "Active" 1 "NotActive" ;
VAL_ 2654339073 StayActiveSource_ECM_1 0 "Active" 1 "NotActive" ;
VAL_ 2654339073 StayActiveSource_ECM_10 0 "Active" 1 "NotActive" ;
VAL_ 2654339073 StayActiveSource_ECM_11 0 "Active" 1 "NotActive" ;
VAL_ 2654339073 StayActiveSource_ECM_12 0 "Active" 1 "NotActive" ;
VAL_ 2654339073 StayActiveSource_ECM_13 0 "Active" 1 "NotActive" ;
VAL_ 2654339073 StayActiveSource_ECM_14 0 "Active" 1 "NotActive" ;
VAL_ 2654339073 StayActiveSource_ECM_15 0 "Active" 1 "NotActive" ;
VAL_ 2654339073 StayActiveSource_ECM_2 0 "Active" 1 "NotActive" ;
VAL_ 2654339073 StayActiveSource_ECM_3 0 "Active" 1 "NotActive" ;
VAL_ 2654339073 StayActiveSource_ECM_4 0 "Active" 1 "NotActive" ;
VAL_ 2654339073 StayActiveSource_ECM_5 0 "Active" 1 "NotActive" ;
VAL_ 2654339073 StayActiveSource_ECM_6 0 "Active" 1 "NotActive" ;
VAL_ 2654339073 StayActiveSource_ECM_7 0 "Active" 1 "NotActive" ;
VAL_ 2654339073 StayActiveSource_ECM_8 0 "Active" 1 "NotActive" ;
VAL_ 2654339073 StayActiveSource_ECM_9 0 "Active" 1 "NotActive" ;
VAL_ 2654339074 CurrentFailSts_EPS 0 "No_Fail_Present" 1 "Fail_Present" ;
VAL_ 2654339074 DES_EPS 0 "No_Busoff" 1 "Busoff_Occurred" ;
VAL_ 2654339074 EOL_EPS 0 "No_EOL_Programming" 1 "EOL_Programming" ;
VAL_ 2654339074 GenericFailSts_EPS 0 "No_Fail_Present" 1 "Fail_Present" ;
VAL_ 2654339074 StayActiveSource_EPS_0 0 "Active" 1 "NotActive" ;
VAL_ 2654339074 StayActiveSource_EPS_1 0 "Active" 1 "NotActive" ;
VAL_ 2654339074 StayActiveSource_EPS_10 0 "Active" 1 "NotActive" ;
VAL_ 2654339074 StayActiveSource_EPS_11 0 "Active" 1 "NotActive" ;
VAL_ 2654339074 StayActiveSource_EPS_12 0 "Active" 1 "NotActive" ;
VAL_ 2654339074 StayActiveSource_EPS_13 0 "Active" 1 "NotActive" ;
VAL_ 2654339074 StayActiveSource_EPS_14 0 "Active" 1 "NotActive" ;
VAL_ 2654339074 StayActiveSource_EPS_15 0 "Active" 1 "NotActive" ;
VAL_ 2654339074 StayActiveSource_EPS_2 0 "Active" 1 "NotActive" ;
VAL_ 2654339074 StayActiveSource_EPS_3 0 "Active" 1 "NotActive" ;
VAL_ 2654339074 StayActiveSource_EPS_4 0 "Active" 1 "NotActive" ;
VAL_ 2654339074 StayActiveSource_EPS_5 0 "Active" 1 "NotActive" ;
VAL_ 2654339074 StayActiveSource_EPS_6 0 "Active" 1 "NotActive" ;
VAL_ 2654339074 StayActiveSource_EPS_7 0 "Active" 1 "NotActive" ;
VAL_ 2654339074 StayActiveSource_EPS_8 0 "Active" 1 "NotActive" ;
VAL_ 2654339074 StayActiveSource_EPS_9 0 "Active" 1 "NotActive" ;
VAL_ 2654339075 CurrentFailSts_IPC 0 "No_Fail_Present" 1 "Fail_Present" ;
VAL_ 2654339075 DES_IPC 0 "No_Busoff" 1 "Busoff_Occurred" ;
VAL_ 2654339075 EOL_IPC 0 "No_EOL_Programming" 1 "EOL_Programming" ;
VAL_ 2654339075 GenericFailSts_IPC 0 "No_Fail_Present" 1 "Fail_Present" ;
VAL_ 2654339075 StayActiveSource_IPC_0 0 "Active" 1 "NotActive" ;
VAL_ 2654339075 StayActiveSource_IPC_1 0 "Active" 1 "NotActive" ;
VAL_ 2654339075 StayActiveSource_IPC_10 0 "Active" 1 "NotActive" ;
VAL_ 2654339075 StayActiveSource_IPC_11 0 "Active" 1 "NotActive" ;
VAL_ 2654339075 StayActiveSource_IPC_12 0 "Active" 1 "NotActive" ;
VAL_ 2654339075 StayActiveSource_IPC_13 0 "Active" 1 "NotActive" ;
VAL_ 2654339075 StayActiveSource_IPC_14 0 "Active" 1 "NotActive" ;
VAL_ 2654339075 StayActiveSource_IPC_15 0 "Active" 1 "NotActive" ;
VAL_ 2654339075 StayActiveSource_IPC_2 0 "Active" 1 "NotActive" ;
VAL_ 2654339075 StayActiveSource_IPC_3 0 "Active" 1 "NotActive" ;
VAL_ 2654339075 StayActiveSource_IPC_4 0 "Active" 1 "NotActive" ;
VAL_ 2654339075 StayActiveSource_IPC_5 0 "Active" 1 "NotActive" ;
VAL_ 2654339075 StayActiveSource_IPC_6 0 "Active" 1 "NotActive" ;
VAL_ 2654339075 StayActiveSource_IPC_7 0 "Active" 1 "NotActive" ;
VAL_ 2654339075 StayActiveSource_IPC_8 0 "Active" 1 "NotActive" ;
VAL_ 2654339075 StayActiveSource_IPC_9 0 "Active" 1 "NotActive" ;
